VERSION ""

NS_ :

BS_:

BU_: SVB1 Tester Gateway CDS1 CDS2 ADV IRC AVP AVM PDC ADB1 ADB2 HDMAP DSM Fradar LCDA1 LCDA2

BO_ 3221225472 VECTOR__INDEPENDENT_SIG_MSG: 0 Vector__XXX
 SG_ Nanoseconds : 0|30@1+ (1,0) [0|0] "" Vector__XXX

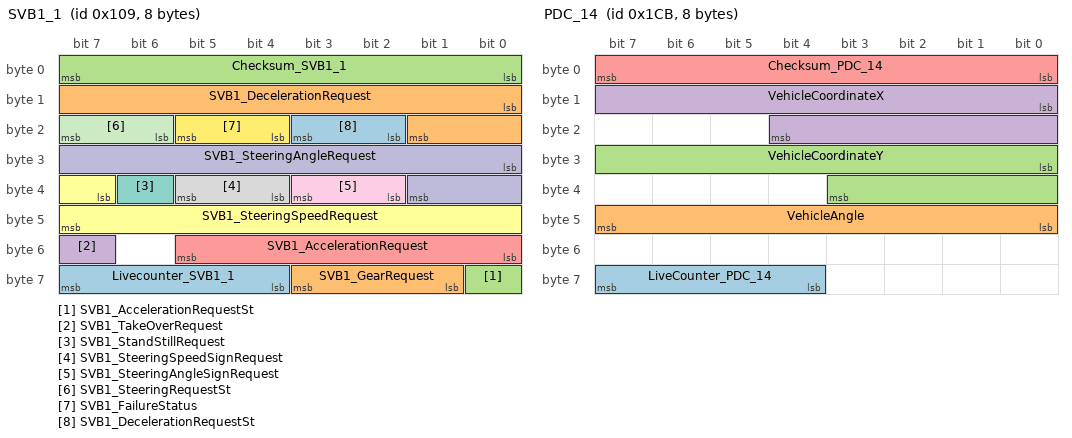
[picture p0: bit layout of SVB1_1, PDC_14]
BO_ 265 SVB1_1: 8 SVB1
 SG_ Livecounter_SVB1_1 : 60|4@1+ (1,0) [0|15] "Pulse"  CDS1,CDS2
 SG_ SVB1_GearRequest : 57|3@1+ (1,0) [0|7] ""  CDS1,CDS2
 SG_ SVB1_AccelerationRequestSt : 56|1@1+ (1,0) [0|1] ""  CDS1,CDS2
 SG_ SVB1_TakeOverRequest : 55|1@1+ (1,0) [0|1] ""  CDS1,CDS2
 SG_ SVB1_AccelerationRequest : 48|6@1+ (0.1,0) [0|6.3] "m/s2"  CDS1,CDS2
 SG_ SVB1_SteeringSpeedRequest : 39|9@1+ (1,0) [0|500] "deg/s"  CDS1,CDS2
 SG_ SVB1_StandStillRequest : 38|1@1+ (1,0) [0|1] ""  CDS1,CDS2
 SG_ SVB1_SteeringSpeedSignRequest : 36|2@1+ (1,0) [0|3] ""  CDS1,CDS2
 SG_ SVB1_SteeringAngleSignRequest : 34|2@1+ (1,0) [0|3] ""  CDS1,CDS2
 SG_ SVB1_SteeringAngleRequest : 24|10@1+ (1,0) [0|1023] "deg"  CDS1,CDS2
 SG_ SVB1_SteeringRequestSt : 22|2@1+ (1,0) [0|3] ""  CDS1,CDS2
 SG_ SVB1_FailureStatus : 20|2@1+ (1,0) [0|3] ""  CDS1,CDS2
 SG_ SVB1_DecelerationRequestSt : 18|2@1+ (1,0) [0|3] ""  CDS1,CDS2
 SG_ SVB1_DecelerationRequest : 8|10@1+ (0.01,-10) [-10|0] "m/s2"  CDS1,CDS2
 SG_ Checksum_SVB1_1 : 0|8@1+ (1,0) [0|255] ""  CDS1,CDS2

BO_ 416 SVB1_2: 8 SVB1
 SG_ Livecounter_SVB1_2 : 60|4@1+ (1,0) [0|15] "Pulse"  CDS1,CDS2
 SG_ Checksum_SVB1_2 : 0|8@1+ (1,0) [0|255] ""  CDS1,CDS2
 SG_ SVB1_LeftTurningLightRequest : 10|2@1+ (1,0) [0|3] ""  CDS1,CDS2
 SG_ SVB1_RightTurningLightRequest : 12|2@1+ (1,0) [0|3] ""  CDS1,CDS2
 SG_ SVB1_HazardLightRequest : 14|2@1+ (1,0) [0|3] ""  CDS1,CDS2
 SG_ SVB1_FogRequest : 16|3@1+ (1,0) [0|7] ""  CDS1,CDS2
 SG_ SVB1_HornRequest : 19|1@1+ (1,0) [0|1] ""  CDS1,CDS2
 SG_ SVB1_Lowbeamrequest : 20|2@1+ (1,0) [0|3] ""  CDS1,CDS2
 SG_ SVB1_HighBeamRequest : 22|2@1+ (1,0) [0|3] ""  CDS1,CDS2
 SG_ SVB1_HU_SpeechReq_LeftTempAdjSW : 26|3@1+ (1,0) [0|7] ""  CDS1,CDS2
 SG_ SVB1_HU_SpeechRequest_SetLeftBLW : 29|3@1+ (1,0) [0|7] ""  CDS1,CDS2
 SG_ SVB1_PositionLightRequest : 32|3@1+ (1,0) [0|7] ""  CDS1,CDS2
 SG_ SVB1_HU_SpeechRequest_AC : 35|2@1+ (1,0) [0|3] ""  CDS1,CDS2
 SG_ SVB1_HU_SpeechRequest_FRSREC : 37|2@1+ (1,0) [0|3] ""  CDS1,CDS2
 SG_ SVB1_HU_SpeechRequest_BlwlevelAd : 40|2@1+ (1,0) [0|3] ""  CDS1,CDS2
 SG_ SVB1_HU_SpeechReq_FLseatHeatLeve : 42|3@1+ (1,0) [0|7] ""  CDS1,CDS2
 SG_ SVB1_HU_SpeechReq_FRseatHeatLeve : 45|3@1+ (1,0) [0|7] ""  CDS1,CDS2
 SG_ SVB1_HU_SpeechReq_SetLeftTemp : 48|6@1+ (0.5,15) [15|40] "°Ê"  CDS1,CDS2
 SG_ SVB1_EPBRequest : 54|2@1+ (1,0) [0|3] ""  CDS1,CDS2
 SG_ SVB1_RequestTurnOffLowVoltage : 56|2@1+ (1,0) [0|3] ""  CDS1,CDS2

BO_ 704 SVB1_3: 8 SVB1
 SG_ SVB1_3_res : 0|8@1+ (1,0) [0|255] ""  CDS1,CDS2

BO_ 706 SVB1_4: 8 SVB1
 SG_ SVB1_4_res : 0|8@1+ (1,0) [0|255] ""  CDS1,CDS2

BO_ 708 SVB1_5: 8 SVB1
 SG_ SVB1_5_res : 0|8@1+ (1,0) [0|255] ""  CDS1,CDS2

BO_ 276 SVB1_6: 8 SVB1
 SG_ SVB1_6_res : 0|8@1+ (1,0) [0|255] ""  CDS1,CDS2

BO_ 459 PDC_14: 8 PDC
 SG_ LiveCounter_PDC_14 : 60|4@1+ (1,0) [0|15] "Pulse"  AVM,AVP,ADV
 SG_ VehicleAngle : 40|8@1+ (0.1,-10) [-10|10] "°„"  AVM,AVP,ADV
 SG_ VehicleCoordinateY : 24|12@1+ (1,-1000) [-1000|3095] "cm"  AVM,AVP,ADV
 SG_ VehicleCoordinateX : 8|13@1+ (1,0) [0|8191] "cm"  AVM,AVP,ADV
 SG_ Checksum_PDC_14 : 0|8@1+ (1,0) [0|255] ""  AVM,AVP,ADV

BO_ 605 PDC_2: 8 PDC
 SG_ ParkingSlotDegree_Right : 52|12@1+ (0.1,0) [0|409.5] "°„"  AVM,AVP
 SG_ ParkingSlotDegree_Left : 40|12@1+ (0.1,0) [0|409.5] "°„"  AVM,AVP
 SG_ SensorErrorSt_RRS : 39|1@1+ (1,0) [0|1] ""  AVM,AVP,ADV,Gateway
 SG_ ObjectRange_RRS : 36|3@1+ (1,0) [0|7] ""  AVM,AVP,ADV,Gateway
 SG_ SensorErrorSt_RLS : 35|1@1+ (1,0) [0|1] ""  AVM,AVP,ADV,Gateway
 SG_ ObjectRange_RLS : 32|3@1+ (1,0) [0|7] ""  AVM,AVP,ADV,Gateway
 SG_ SensorErrorSt_FRS : 31|1@1+ (1,0) [0|1] ""  AVM,AVP,ADV,Gateway
 SG_ ObjectRange_FRS : 28|3@1+ (1,0) [0|7] ""  AVM,AVP,ADV,Gateway
 SG_ SensorErrorSt_FLS : 27|1@1+ (1,0) [0|1] ""  AVM,AVP,ADV,Gateway
 SG_ ObjectRange_FLS : 24|3@1+ (1,0) [0|7] ""  AVM,AVP,ADV,Gateway
 SG_ SensorBlockageSt_RRS : 21|1@1+ (1,0) [0|1] ""  AVM,AVP,ADV,Gateway
 SG_ SensorBlockageSt_RLS : 20|1@1+ (1,0) [0|1] ""  AVM,AVP,ADV,Gateway
 SG_ SensorBlockageSt_FRS : 19|1@1+ (1,0) [0|1] ""  AVM,AVP,ADV,Gateway
 SG_ SensorBlockageSt_FLS : 18|1@1+ (1,0) [0|1] ""  AVM,AVP,ADV,Gateway
 SG_ SensorBlockageSt_FL : 15|1@1+ (1,0) [0|1] ""  AVM,AVP,ADV,Gateway
 SG_ SensorBlockageSt_FML : 14|1@1+ (1,0) [0|1] ""  AVM,AVP,ADV,Gateway
 SG_ SensorBlockageSt_FMR : 13|1@1+ (1,0) [0|1] ""  AVM,AVP,ADV,Gateway
 SG_ SensorBlockageSt_FR : 12|1@1+ (1,0) [0|1] ""  AVM,AVP,ADV,Gateway
 SG_ SensorBlockageSt_RL : 11|1@1+ (1,0) [0|1] ""  AVM,AVP,ADV,Gateway
 SG_ SensorBlockageSt_RML : 10|1@1+ (1,0) [0|1] ""  AVM,AVP,ADV,Gateway
 SG_ SensorBlockageSt_RMR : 9|1@1+ (1,0) [0|1] ""  AVM,AVP,ADV,Gateway
 SG_ SensorBlockageSt_RR : 8|1@1+ (1,0) [0|1] ""  AVM,AVP,ADV,Gateway

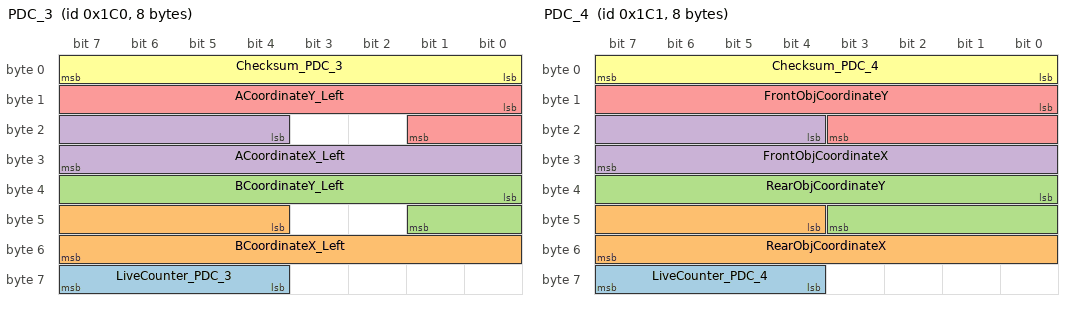
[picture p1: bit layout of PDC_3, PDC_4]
BO_ 448 PDC_3: 8 PDC
 SG_ LiveCounter_PDC_3 : 60|4@1+ (1,0) [0|15] "Pulse"  AVM,AVP,ADV
 SG_ BCoordinateX_Left : 44|12@1+ (1,0) [0|4095] "cm"  AVM,AVP,ADV
 SG_ BCoordinateY_Left : 32|10@1+ (1,0) [0|1023] "cm"  AVM,AVP,ADV
 SG_ ACoordinateX_Left : 20|12@1+ (1,0) [0|4095] "cm"  AVM,AVP,ADV
 SG_ ACoordinateY_Left : 8|10@1+ (1,0) [0|1023] "cm"  AVM,AVP,ADV
 SG_ Checksum_PDC_3 : 0|8@1+ (1,0) [0|255] ""  AVM,AVP,ADV

BO_ 449 PDC_4: 8 PDC
 SG_ LiveCounter_PDC_4 : 60|4@1+ (1,0) [0|15] "Pulse"  AVM,AVP,ADV
 SG_ RearObjCoordinateX : 44|12@1+ (2,-4000) [-4000|4190] "cm"  AVM,AVP,ADV
 SG_ RearObjCoordinateY : 32|12@1+ (2,-4000) [-4000|4190] "cm"  AVM,AVP,ADV
 SG_ FrontObjCoordinateX : 20|12@1+ (2,-4000) [-4000|4190] "cm"  AVM,AVP,ADV
 SG_ FrontObjCoordinateY : 8|12@1+ (2,-4000) [-4000|4190] "cm"  AVM,AVP,ADV
 SG_ Checksum_PDC_4 : 0|8@1+ (1,0) [0|255] ""  AVM,AVP,ADV

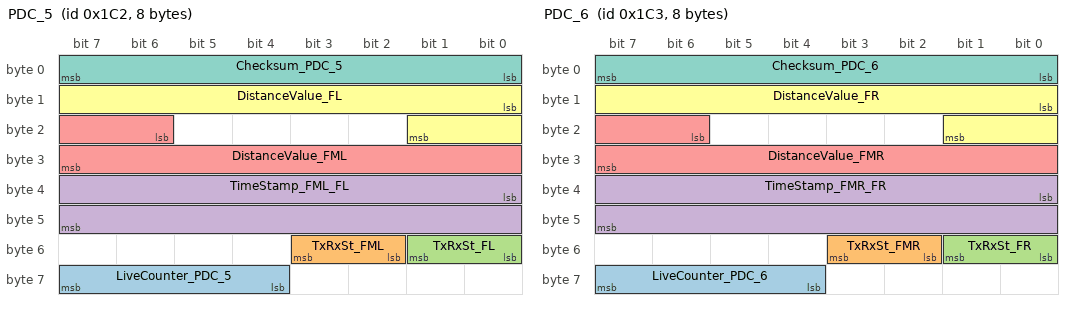
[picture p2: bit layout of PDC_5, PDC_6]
BO_ 450 PDC_5: 8 PDC
 SG_ LiveCounter_PDC_5 : 60|4@1+ (1,0) [0|15] "Pulse"  AVM,AVP,ADV
 SG_ TxRxSt_FML : 50|2@1+ (1,0) [0|3] ""  AVM,AVP,ADV
 SG_ TxRxSt_FL : 48|2@1+ (1,0) [0|3] ""  AVM,AVP,ADV
 SG_ TimeStamp_FML_FL : 32|16@1+ (1,0) [0|65535] "ms"  AVM,AVP,ADV
 SG_ DistanceValue_FML : 22|10@1+ (1,0) [0|1023] "cm"  AVM,AVP,ADV
 SG_ DistanceValue_FL : 8|10@1+ (1,0) [0|1023] "cm"  AVM,AVP,ADV
 SG_ Checksum_PDC_5 : 0|8@1+ (1,0) [0|255] ""  AVM,AVP,ADV

BO_ 451 PDC_6: 8 PDC
 SG_ LiveCounter_PDC_6 : 60|4@1+ (1,0) [0|15] "Pulse"  AVM,AVP,ADV
 SG_ TxRxSt_FMR : 50|2@1+ (1,0) [0|3] ""  AVM,AVP,ADV
 SG_ TxRxSt_FR : 48|2@1+ (1,0) [0|3] ""  AVM,AVP,ADV
 SG_ TimeStamp_FMR_FR : 32|16@1+ (1,0) [0|65535] "ms"  AVM,AVP,ADV
 SG_ DistanceValue_FMR : 22|10@1+ (1,0) [0|1023] "cm"  AVM,AVP,ADV
 SG_ DistanceValue_FR : 8|10@1+ (1,0) [0|1023] "cm"  AVM,AVP,ADV
 SG_ Checksum_PDC_6 : 0|8@1+ (1,0) [0|255] ""  AVM,AVP,ADV

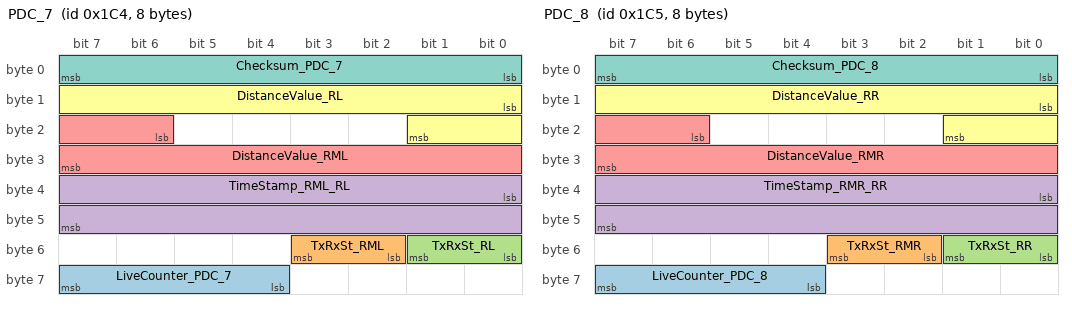
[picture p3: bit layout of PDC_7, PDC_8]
BO_ 452 PDC_7: 8 PDC
 SG_ LiveCounter_PDC_7 : 60|4@1+ (1,0) [0|15] "Pulse"  AVM,AVP,ADV
 SG_ TxRxSt_RML : 50|2@1+ (1,0) [0|3] ""  AVM,AVP,ADV
 SG_ TxRxSt_RL : 48|2@1+ (1,0) [0|3] ""  AVM,AVP,ADV
 SG_ TimeStamp_RML_RL : 32|16@1+ (1,0) [0|65535] "ms"  AVM,AVP,ADV
 SG_ DistanceValue_RML : 22|10@1+ (1,0) [0|1023] "cm"  AVM,AVP,ADV
 SG_ DistanceValue_RL : 8|10@1+ (1,0) [0|1023] "cm"  AVM,AVP,ADV
 SG_ Checksum_PDC_7 : 0|8@1+ (1,0) [0|255] ""  AVM,AVP,ADV

BO_ 453 PDC_8: 8 PDC
 SG_ LiveCounter_PDC_8 : 60|4@1+ (1,0) [0|15] "Pulse"  AVM,AVP,ADV
 SG_ TxRxSt_RMR : 50|2@1+ (1,0) [0|3] ""  AVM,AVP,ADV
 SG_ TxRxSt_RR : 48|2@1+ (1,0) [0|3] ""  AVM,AVP,ADV
 SG_ TimeStamp_RMR_RR : 32|16@1+ (1,0) [0|65535] "ms"  AVM,AVP,ADV
 SG_ DistanceValue_RMR : 22|10@1+ (1,0) [0|1023] "cm"  AVM,AVP,ADV
 SG_ DistanceValue_RR : 8|10@1+ (1,0) [0|1023] "cm"  AVM,AVP,ADV
 SG_ Checksum_PDC_8 : 0|8@1+ (1,0) [0|255] ""  AVM,AVP,ADV

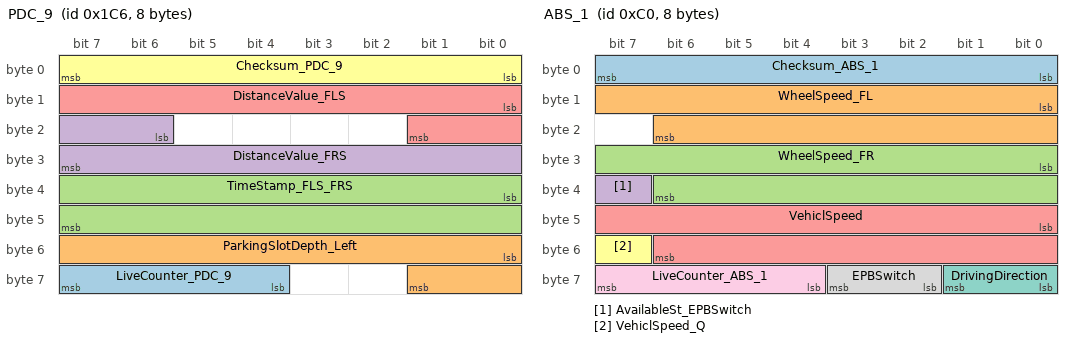
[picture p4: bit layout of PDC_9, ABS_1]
BO_ 454 PDC_9: 8 PDC
 SG_ LiveCounter_PDC_9 : 60|4@1+ (1,0) [0|15] "Pulse"  AVM,AVP,ADV
 SG_ ParkingSlotDepth_Left : 48|10@1+ (1,0) [0|1023] "cm"  AVM,AVP
 SG_ TimeStamp_FLS_FRS : 32|16@1+ (1,0) [0|65535] "ms"  AVM,AVP,ADV
 SG_ DistanceValue_FRS : 22|10@1+ (1,0) [0|1023] "cm"  AVM,AVP,ADV
 SG_ DistanceValue_FLS : 8|10@1+ (1,0) [0|1023] "cm"  AVM,AVP,ADV
 SG_ Checksum_PDC_9 : 0|8@1+ (1,0) [0|255] ""  AVM,AVP,ADV

BO_ 192 ABS_1: 8 Gateway
 SG_ Checksum_ABS_1 : 0|8@1+ (1,0) [0|255] ""  SVB1,CDS1,CDS2,ADV,IRC,AVP,AVM,PDC,ADB1,ADB2,HDMAP,DSM,Fradar,LCDA1,LCDA2
 SG_ WheelSpeed_FL : 8|15@1+ (0.01,0) [0|327.67] "km/h"  SVB1,CDS1,CDS2,ADV,AVP,AVM,PDC,HDMAP,DSM
 SG_ WheelSpeed_FR : 24|15@1+ (0.01,0) [0|327.67] "km/h"  SVB1,CDS1,CDS2,ADV,AVP,AVM,PDC,HDMAP,DSM
 SG_ AvailableSt_EPBSwitch : 39|1@1+ (1,0) [0|1] ""  SVB1,CDS1,CDS2,ADV
 SG_ VehiclSpeed : 40|15@1+ (0.01,0) [0|327.67] "km/h"  SVB1,CDS1,CDS2,ADV,IRC,AVP,AVM,PDC,ADB1,ADB2,HDMAP,DSM,Fradar,LCDA1,LCDA2
 SG_ VehiclSpeed_Q : 55|1@1+ (1,0) [0|1] ""  SVB1,CDS1,CDS2,ADV,IRC,HDMAP,DSM
 SG_ DrivingDirection : 56|2@1+ (1,0) [0|3] ""  SVB1,CDS1,CDS2,ADV,AVP,AVM,PDC,Fradar,LCDA1,LCDA2
 SG_ EPBSwitch : 58|2@1+ (1,0) [0|3] ""  SVB1,CDS1,CDS2,ADV
 SG_ LiveCounter_ABS_1 : 60|4@1+ (1,0) [0|15] ""  SVB1,CDS1,CDS2,ADV,IRC,AVP,AVM,PDC,ADB1,ADB2,HDMAP,DSM,Fradar,LCDA1,LCDA2

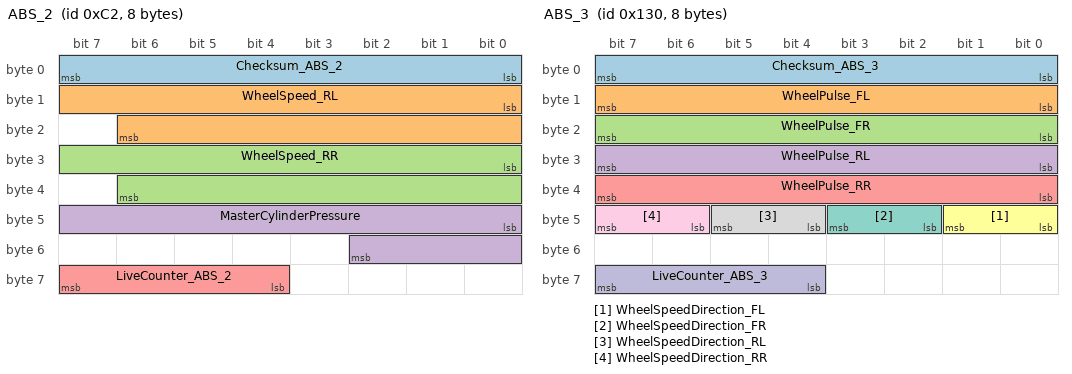
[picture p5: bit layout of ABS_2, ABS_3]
BO_ 194 ABS_2: 8 Gateway
 SG_ Checksum_ABS_2 : 0|8@1+ (1,0) [0|255] ""  SVB1,CDS1,CDS2,ADV,AVP,AVM,PDC,HDMAP
 SG_ WheelSpeed_RL : 8|15@1+ (0.01,0) [0|327.67] "km/h"  SVB1,CDS1,CDS2,ADV,AVP,AVM,PDC,HDMAP
 SG_ WheelSpeed_RR : 24|15@1+ (0.01,0) [0|327.67] "km/h"  SVB1,CDS1,CDS2,ADV,AVP,AVM,PDC,HDMAP
 SG_ MasterCylinderPressure : 40|11@1+ (0.1,0) [0|204.7] "bar"  SVB1,CDS1,CDS2,ADV,HDMAP
 SG_ LiveCounter_ABS_2 : 60|4@1+ (1,0) [0|15] ""  SVB1,CDS1,CDS2,ADV,AVP,AVM,PDC,HDMAP

BO_ 304 ABS_3: 8 Gateway
 SG_ Checksum_ABS_3 : 0|8@1+ (1,0) [0|255] ""  SVB1,CDS1,CDS2,ADV,AVP,AVM,PDC,HDMAP
 SG_ WheelPulse_FL : 8|8@1+ (1,0) [0|255] ""  SVB1,CDS1,CDS2,ADV,AVP,AVM,PDC,HDMAP
 SG_ WheelPulse_FR : 16|8@1+ (1,0) [0|255] ""  SVB1,CDS1,CDS2,ADV,AVP,AVM,PDC,HDMAP
 SG_ WheelPulse_RL : 24|8@1+ (1,0) [0|255] ""  SVB1,CDS1,CDS2,ADV,AVP,AVM,PDC,HDMAP
 SG_ WheelPulse_RR : 32|8@1+ (1,0) [0|255] ""  SVB1,CDS1,CDS2,ADV,AVP,AVM,PDC,HDMAP
 SG_ WheelSpeedDirection_FL : 40|2@1+ (1,0) [0|3] ""  CDS2,CDS1,SVB1,PDC
 SG_ WheelSpeedDirection_FR : 42|2@1+ (1,0) [0|3] ""  CDS2,CDS1,SVB1,PDC
 SG_ WheelSpeedDirection_RL : 44|2@1+ (1,0) [0|3] ""  CDS2,CDS1,SVB1,PDC
 SG_ WheelSpeedDirection_RR : 46|2@1+ (1,0) [0|3] ""  CDS2,CDS1,SVB1,PDC
 SG_ LiveCounter_ABS_3 : 60|4@1+ (1,0) [0|15] ""  SVB1,CDS1,CDS2,ADV,AVP,AVM,PDC,HDMAP

BO_ 306 ESC_2_1: 8 Gateway
 SG_ Checksum_ESC_2_1 : 0|8@1+ (1,0) [0|255] ""  SVB1,CDS1,CDS2,ADV,AVP,AVM,PDC
 SG_ WorkingSt_ESC : 8|1@1+ (1,0) [0|1] ""  SVB1,CDS1,CDS2
 SG_ ErrorSt_ESC : 9|1@1+ (1,0) [0|1] ""  SVB1,CDS1,CDS2,ADV
 SG_ Intervention_ESC : 10|1@1+ (1,0) [0|1] ""  SVB1,CDS1,CDS2,ADV
 SG_ ErrorSt_ABS : 11|1@1+ (1,0) [0|1] ""  SVB1,CDS1,CDS2
 SG_ Intervention_ABS : 12|1@1+ (1,0) [0|1] ""  SVB1,CDS1,CDS2,ADV
 SG_ Intervention_TCS : 14|1@1+ (1,0) [0|1] ""  SVB1,CDS1,CDS2,ADV
 SG_ ErrorSt_EBD : 15|1@1+ (1,0) [0|1] ""  CDS2,SVB1,CDS1,ADV
 SG_ AvailableSt_CDP : 16|1@1+ (1,0) [0|1] ""  CDS2,SVB1,CDS1
 SG_ Intervention_CDP_RWU : 17|1@1+ (1,0) [0|1] ""  CDS2,SVB1,CDS1
 SG_ LampCmd_EPB : 18|2@1+ (1,0) [0|3] ""  CDS2,CDS1,SVB1
 SG_ ErrotSt_EPB : 20|2@1+ (1,0) [0|3] ""  SVB1,CDS1,CDS2,ADV,AVP,AVM
 SG_ AvailableSt_HDC : 26|1@1+ (1,0) [0|1] ""  SVB1,CDS1,CDS2
 SG_ WorkingSt_HDC : 27|2@1+ (1,0) [0|3] ""  SVB1,CDS1,CDS2
 SG_ ErrorSt_AVH : 29|1@1+ (1,0) [0|1] ""  CDS2,CDS1,SVB1
 SG_ WorkingSt_AVH : 30|2@1+ (1,0) [0|3] ""  CDS2,CDS1,SVB1
 SG_ AvailableSt_CDDS : 32|1@1+ (1,0) [0|1] ""  SVB1,CDS1,CDS2
 SG_ Intervention_CDDS : 33|1@1+ (1,0) [0|1] ""  SVB1,CDS1,CDS2
 SG_ AvailableSt_AEB : 34|1@1+ (1,0) [0|1] ""  SVB1,CDS1,CDS2
 SG_ Intervention_AEB : 35|1@1+ (1,0) [0|1] ""  SVB1,CDS1,CDS2
 SG_ AvailableSt_ABP : 36|1@1+ (1,0) [0|1] ""  SVB1,CDS1,CDS2
 SG_ Intervention_ABP : 37|1@1+ (1,0) [0|1] ""  SVB1,CDS1,CDS2
 SG_ AvailableSt_AWB : 38|1@1+ (1,0) [0|1] ""  SVB1,CDS1,CDS2
 SG_ Intervention_AWB : 39|1@1+ (1,0) [0|1] ""  SVB1,CDS1,CDS2
 SG_ AvailableSt_HBA : 40|1@1+ (1,0) [0|1] ""  CDS2,CDS1,SVB1
 SG_ Intervention_HBA : 41|1@1+ (1,0) [0|1] ""  CDS2,CDS1,SVB1
 SG_ WorkingSt_HBB : 42|2@1+ (1,0) [0|3] ""  CDS2,CDS1,SVB1
 SG_ Intervention_HBB : 44|1@1+ (1,0) [0|1] ""  CDS2,CDS1,SVB1
 SG_ Intervention_EmergencyBrake : 45|1@1+ (1,0) [0|1] ""  CDS2,CDS1,SVB1
 SG_ VehicleStandstillSt : 46|1@1+ (1,0) [0|1] ""  SVB1,CDS1,CDS2,ADV
 SG_ BrakeLightCtrlCmd : 47|1@1+ (1,0) [0|1] ""  CDS2,CDS1,SVB1
 SG_ WorkingSt_EPB : 48|2@1+ (1,0) [0|3] ""  SVB1,CDS1,CDS2,ADV,AVP,AVM,PDC
 SG_ APA_Available_ESC : 50|1@1+ (1,0) [0|1] ""  CDS2,SVB1,CDS1,ADV
 SG_ APA_Intervention_ESC : 51|1@1+ (1,0) [0|1] ""  CDS2,SVB1,CDS1,ADV
 SG_ LiveCounter_ESC_2_1 : 60|4@1+ (1,0) [0|15] ""  SVB1,CDS1,CDS2,ADV,AVP,AVM,PDC

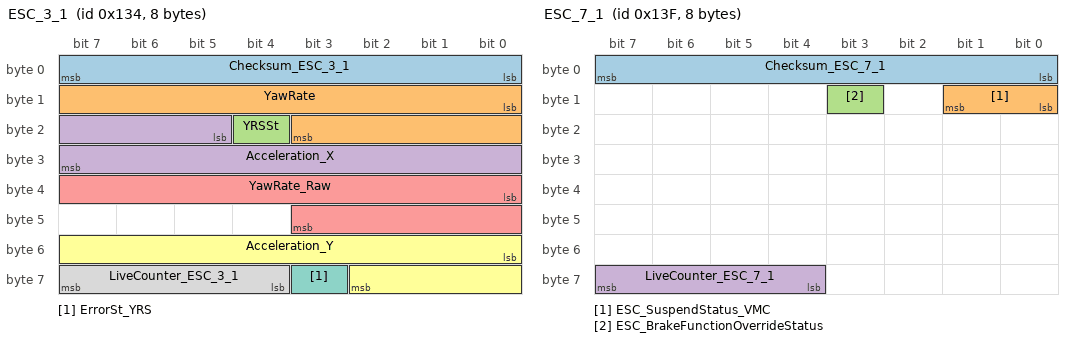
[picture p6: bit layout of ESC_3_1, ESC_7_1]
BO_ 308 ESC_3_1: 8 Gateway
 SG_ Checksum_ESC_3_1 : 0|8@1+ (1,0) [0|255] ""  SVB1,CDS1,CDS2,ADV,IRC,AVP,AVM,PDC,HDMAP,Fradar,LCDA1,LCDA2
 SG_ YawRate : 8|12@1+ (0.05,-100) [-100|104.75] "deg/s"  SVB1,CDS1,CDS2,ADV,IRC,AVP,AVM,PDC,HDMAP,Fradar,LCDA1,LCDA2
 SG_ YRSSt : 20|1@1+ (1,0) [0|1] ""  SVB1,CDS1,CDS2,ADV,IRC,AVP,AVM,HDMAP,Fradar,LCDA1,LCDA2
 SG_ Acceleration_X : 21|11@1+ (0.027127,-21.593) [-21.593|33.935969] ""  SVB1,CDS1,CDS2,ADV,AVP,AVM,HDMAP,Fradar,LCDA1,LCDA2
 SG_ YawRate_Raw : 32|12@1+ (0.05,-100) [-100|104.75] "deg/s"  CDS2,CDS1,SVB1,AVP,AVM
 SG_ Acceleration_Y : 48|11@1+ (0.027127,-21.593) [-21.593|33.935969] ""  SVB1,CDS1,CDS2,ADV,AVP,AVM,HDMAP,Fradar,LCDA1,LCDA2
 SG_ ErrorSt_YRS : 59|1@1+ (1,0) [0|1] ""  SVB1,CDS1,CDS2,ADV,AVP,AVM,HDMAP,Fradar,LCDA1,LCDA2
 SG_ LiveCounter_ESC_3_1 : 60|4@1+ (1,0) [0|15] ""  SVB1,CDS1,CDS2,ADV,IRC,AVP,AVM,PDC,HDMAP,Fradar,LCDA1,LCDA2

BO_ 312 ESC_5_1: 8 Gateway
 SG_ Checksum_ESC_5_1 : 0|8@1+ (1,0) [0|255] ""  SVB1,CDS1,CDS2,ADV,HDMAP,DSM
 SG_ ESC_AutoPark_LCSt : 25|3@1+ (1,0) [0|7] ""  CDS2,SVB1,CDS1,ADV
 SG_ ESC_AutoPark_LCFailureSt : 28|3@1+ (1,0) [0|7] ""  CDS2,SVB1,CDS1,ADV
 SG_ ESC_AutoPark_LC_BrakeMode : 35|2@1+ (1,0) [0|3] ""  CDS2,SVB1,CDS1,ADV
 SG_ ESC_LSMAvail_Parking : 37|1@1+ (1,0) [0|1] ""  CDS2,SVB1,CDS1,ADV
 SG_ ESC_AutoPark_LC_APA_Avail : 38|2@1+ (1,0) [0|3] ""  CDS2,SVB1,CDS1,ADV
 SG_ ESC_VLCSt_L12 : 40|1@1+ (1,0) [0|1] ""  SVB1,CDS1,CDS2
 SG_ ESC_VLCSt_L3 : 41|1@1+ (1,0) [0|1] ""  SVB1,CDS1,CDS2
 SG_ ESC_VLC_Error_L12 : 42|1@1+ (1,0) [0|1] ""  SVB1,CDS1,CDS2
 SG_ ESC_VMC_Error_L3 : 44|2@1+ (1,0) [0|3] ""  SVB1,CDS1,CDS2
 SG_ ESC_AutoDriving_LC_Brakemode : 46|2@1+ (1,0) [0|3] ""  SVB1,CDS1,CDS2
 SG_ ESC_AutoPark_LC_RPA_Avail : 48|2@1+ (1,0) [0|3] ""  CDS2,SVB1,CDS1,ADV
 SG_ ESC_AutoParkingSt_Feedback : 50|1@1+ (1,0) [0|1] ""  SVB1,CDS1,CDS2,ADV
 SG_ ESC_BrakePedalStatus : 51|1@1+ (1,0) [0|1] ""  SVB1,CDS1,CDS2,ADV,AVP,AVM,HDMAP,DSM
 SG_ ESC_BrakePedalStatus_Q : 52|2@1+ (1,0) [0|3] ""  SVB1,CDS1,CDS2,ADV,HDMAP,DSM
 SG_ ESC_BrakePedalDominant_Q : 54|2@1+ (1,0) [0|3] ""  SVB1,CDS1,CDS2,ADV,HDMAP,DSM
 SG_ ESC_BrakePedalDominant : 56|1@1+ (1,0) [0|1] ""  SVB1,CDS1,CDS2,ADV,HDMAP,DSM
 SG_ ESC_AutoPark_LC_AVP_Avail : 57|2@1+ (1,0) [0|3] ""  CDS2,SVB1,CDS1,ADV
 SG_ ESC_ShutOffFinished : 59|1@1+ (1,0) [0|1] ""  SVB1,CDS1,CDS2
 SG_ LiveCounter_ESC_5_1 : 60|4@1+ (1,0) [0|15] "Pulse"  SVB1,CDS1,CDS2,ADV,HDMAP,DSM

BO_ 319 ESC_7_1: 8 Gateway
 SG_ Checksum_ESC_7_1 : 0|8@1+ (1,0) [0|255] ""  SVB1,CDS1,CDS2,ADV
 SG_ ESC_SuspendStatus_VMC : 8|2@1+ (1,0) [0|3] ""  SVB1,CDS1,CDS2,ADV
 SG_ ESC_BrakeFunctionOverrideStatus : 11|1@1+ (1,0) [0|1] ""  SVB1,CDS1,CDS2,ADV
 SG_ LiveCounter_ESC_7_1 : 60|4@1+ (1,0) [0|15] ""  SVB1,CDS1,CDS2,ADV

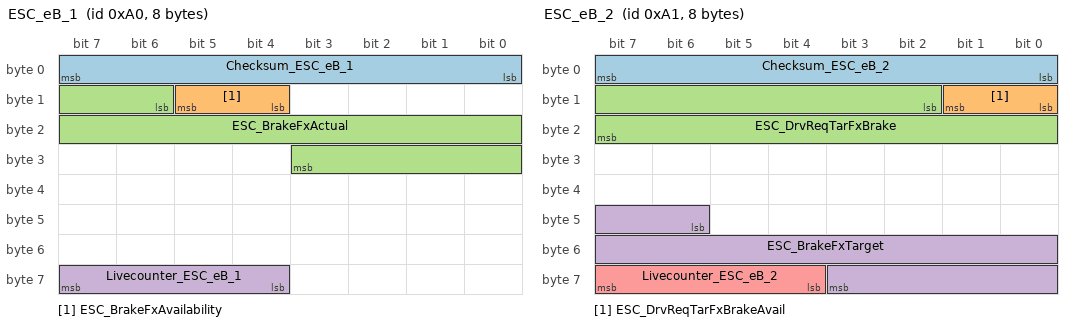
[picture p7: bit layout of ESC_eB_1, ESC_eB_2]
BO_ 160 ESC_eB_1: 8 Gateway
 SG_ Checksum_ESC_eB_1 : 0|8@1+ (1,0) [0|255] ""  SVB1,CDS2,CDS1
 SG_ ESC_BrakeFxAvailability : 12|2@1+ (1,0) [0|3] ""  SVB1,CDS2,CDS1
 SG_ ESC_BrakeFxActual : 14|14@1+ (8,-125000) [-125000|0] ""  SVB1,CDS2,CDS1
 SG_ Livecounter_ESC_eB_1 : 60|4@1+ (1,0) [0|15] "Pulse"  SVB1,CDS2,CDS1

BO_ 161 ESC_eB_2: 8 Gateway
 SG_ Checksum_ESC_eB_2 : 0|8@1+ (1,0) [0|255] ""  SVB1,CDS2,CDS1
 SG_ ESC_DrvReqTarFxBrakeAvail : 8|2@1+ (1,0) [0|3] ""  SVB1,CDS2,CDS1
 SG_ ESC_DrvReqTarFxBrake : 10|14@1+ (8,-125000) [-125000|0] ""  SVB1,CDS2,CDS1
 SG_ ESC_BrakeFxTarget : 46|14@1+ (8,-125000) [-125000|0] ""  SVB1,CDS2,CDS1
 SG_ Livecounter_ESC_eB_2 : 60|4@1+ (1,0) [0|15] "Pulse"  SVB1,CDS2,CDS1

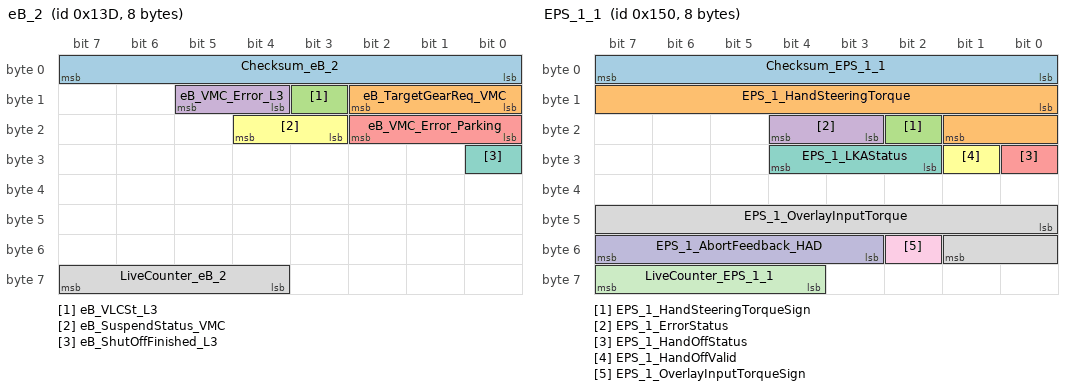
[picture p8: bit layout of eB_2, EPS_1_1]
BO_ 317 eB_2: 8 Gateway
 SG_ Checksum_eB_2 : 0|8@1+ (1,0) [0|255] ""  SVB1,CDS1,CDS2
 SG_ eB_TargetGearReq_VMC : 8|3@1+ (1,0) [0|7] ""  CDS2,CDS1,SVB1
 SG_ eB_VLCSt_L3 : 11|1@1+ (1,0) [0|1] ""  SVB1,CDS1,CDS2
 SG_ eB_VMC_Error_L3 : 12|2@1+ (1,0) [0|3] ""  SVB1,CDS1,CDS2
 SG_ eB_VMC_Error_Parking : 16|3@1+ (1,0) [0|7] ""  CDS2,CDS1,SVB1
 SG_ eB_SuspendStatus_VMC : 19|2@1+ (1,0) [0|3] ""  SVB1,CDS1,CDS2
 SG_ eB_ShutOffFinished_L3 : 24|1@1+ (1,0) [0|1] ""  SVB1,CDS1,CDS2
 SG_ LiveCounter_eB_2 : 60|4@1+ (1,0) [0|15] "Pulse"  SVB1,CDS1,CDS2

BO_ 336 EPS_1_1: 8 Gateway
 SG_ Checksum_EPS_1_1 : 0|8@1+ (1,0) [0|255] ""  SVB1,CDS1,CDS2,ADV,DSM
 SG_ EPS_1_HandSteeringTorque : 8|10@1+ (0.01,0) [0|10.23] "Nm"  SVB1,CDS1,CDS2,ADV,DSM
 SG_ EPS_1_HandSteeringTorqueSign : 18|1@1+ (1,0) [0|1] ""  SVB1,CDS1,CDS2,ADV,DSM
 SG_ EPS_1_ErrorStatus : 19|2@1+ (1,0) [0|3] ""  SVB1,CDS1,CDS2,ADV
 SG_ EPS_1_HandOffStatus : 24|1@1+ (1,0) [0|1] ""  SVB1,CDS1,CDS2,ADV,DSM
 SG_ EPS_1_HandOffValid : 25|1@1+ (1,0) [0|1] ""  SVB1,CDS1,CDS2,ADV,DSM
 SG_ EPS_1_LKAStatus : 26|3@1+ (1,0) [0|7] ""  SVB1,CDS1,CDS2
 SG_ EPS_1_OverlayInputTorque : 40|10@1+ (0.01,0) [0|10.23] "Nm"  SVB1,CDS1,CDS2,ADV
 SG_ EPS_1_OverlayInputTorqueSign : 50|1@1+ (1,0) [0|1] ""  SVB1,CDS1,CDS2,ADV
 SG_ EPS_1_AbortFeedback_HAD : 51|5@1+ (1,0) [0|31] ""  SVB1,Gateway,CDS1,CDS2,ADV
 SG_ LiveCounter_EPS_1_1 : 60|4@1+ (1,0) [0|15] "Pulse"  SVB1,CDS1,CDS2,ADV,DSM

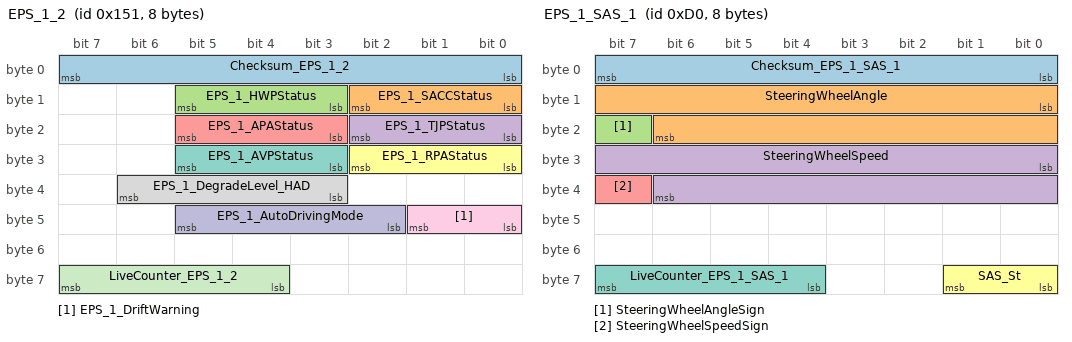
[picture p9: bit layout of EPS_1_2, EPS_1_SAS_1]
BO_ 337 EPS_1_2: 8 Gateway
 SG_ Checksum_EPS_1_2 : 0|8@1+ (1,0) [0|255] ""  SVB1,CDS1,CDS2,ADV
 SG_ EPS_1_SACCStatus : 8|3@1+ (1,0) [0|7] ""  SVB1,CDS1,CDS2
 SG_ EPS_1_HWPStatus : 11|3@1+ (1,0) [0|7] ""  SVB1,CDS1,CDS2
 SG_ EPS_1_TJPStatus : 16|3@1+ (1,0) [0|7] ""  SVB1,CDS1,CDS2
 SG_ EPS_1_APAStatus : 19|3@1+ (1,0) [0|7] ""  CDS2,SVB1,CDS1,ADV
 SG_ EPS_1_RPAStatus : 24|3@1+ (1,0) [0|7] ""  CDS2,SVB1,CDS1,ADV
 SG_ EPS_1_AVPStatus : 27|3@1+ (1,0) [0|7] ""  CDS2,SVB1,CDS1,ADV
 SG_ EPS_1_DegradeLevel_HAD : 35|4@1+ (1,0) [0|15] ""  SVB1,CDS1,CDS2,ADV
 SG_ EPS_1_DriftWarning : 40|2@1+ (1,0) [0|3] ""  SVB1,CDS1,CDS2
 SG_ EPS_1_AutoDrivingMode : 42|4@1+ (1,0) [0|15] ""  SVB1,CDS1,CDS2,ADV
 SG_ LiveCounter_EPS_1_2 : 60|4@1+ (1,0) [0|15] ""  SVB1,CDS1,CDS2,ADV

BO_ 208 EPS_1_SAS_1: 8 Gateway
 SG_ Checksum_EPS_1_SAS_1 : 0|8@1+ (1,0) [0|255] ""  SVB1,CDS1,CDS2,ADV,IRC,AVP,AVM,PDC,HDMAP,DSM,Fradar,LCDA1,LCDA2
 SG_ SteeringWheelAngle : 8|15@1+ (0.04375,0) [0|1433.55625] "°„"  SVB1,CDS1,CDS2,ADV,IRC,AVP,AVM,PDC,HDMAP,DSM,Fradar,LCDA1,LCDA2
 SG_ SteeringWheelAngleSign : 23|1@1+ (1,0) [0|1] ""  SVB1,CDS1,CDS2,ADV,IRC,AVP,AVM,PDC,HDMAP,DSM,Fradar,LCDA1,LCDA2
 SG_ SteeringWheelSpeed : 24|15@1+ (0.04375,0) [0|1433.55625] "°„/s"  SVB1,CDS1,CDS2,IRC,HDMAP,DSM
 SG_ SteeringWheelSpeedSign : 39|1@1+ (1,0) [0|1] ""  SVB1,CDS1,CDS2,IRC,HDMAP,DSM
 SG_ SAS_St : 56|2@1+ (1,0) [0|3] ""  SVB1,CDS1,CDS2,ADV,IRC,AVP,AVM,HDMAP,DSM,Fradar,LCDA1,LCDA2
 SG_ LiveCounter_EPS_1_SAS_1 : 60|4@1+ (1,0) [0|15] ""  SVB1,CDS1,CDS2,ADV,IRC,AVP,AVM,PDC,HDMAP,DSM,Fradar,LCDA1,LCDA2

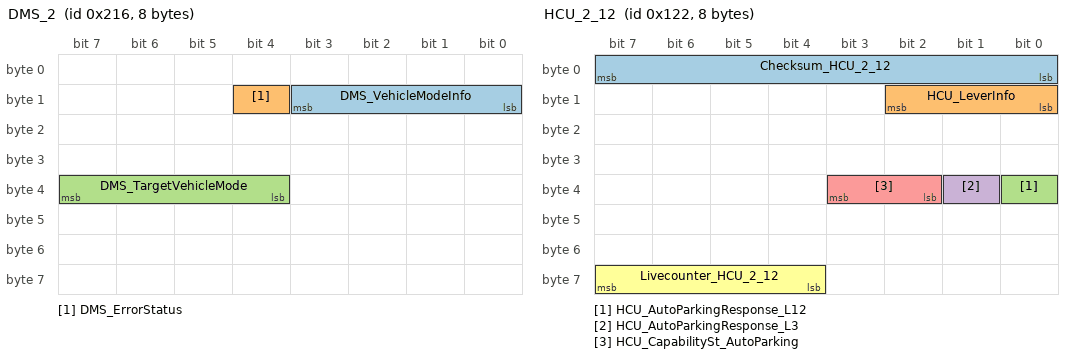
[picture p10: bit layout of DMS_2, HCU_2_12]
BO_ 534 DMS_2: 8 Gateway
 SG_ DMS_VehicleModeInfo : 8|4@1+ (1,0) [0|15] ""  SVB1,CDS1,CDS2,AVP,AVM
 SG_ DMS_ErrorStatus : 12|1@1+ (1,0) [0|1] ""  CDS2,SVB1,CDS1
 SG_ DMS_TargetVehicleMode : 36|4@1+ (1,0) [0|15] ""  SVB1,CDS1,CDS2

BO_ 290 HCU_2_12: 8 Gateway
 SG_ Checksum_HCU_2_12 : 0|8@1+ (1,0) [0|255] ""  SVB1,CDS1,CDS2,ADV,IRC,AVP,AVM,PDC,DSM,Fradar,LCDA1,LCDA2
 SG_ HCU_LeverInfo : 8|3@1+ (1,0) [0|7] ""  SVB1,CDS1,CDS2,ADV,IRC,AVP,AVM,PDC,DSM,Fradar,LCDA1,LCDA2
 SG_ HCU_AutoParkingResponse_L12 : 32|1@1+ (1,0) [0|1] ""  SVB1,CDS2,CDS1,ADV
 SG_ HCU_AutoParkingResponse_L3 : 33|1@1+ (1,0) [0|1] ""  SVB1,CDS2,CDS1
 SG_ HCU_CapabilitySt_AutoParking : 34|2@1+ (1,0) [0|3] ""  SVB1,CDS1,CDS2,ADV
 SG_ Livecounter_HCU_2_12 : 60|4@1+ (1,0) [0|15] "pulse"  SVB1,CDS1,CDS2,ADV,IRC,AVP,AVM,PDC,DSM,Fradar,LCDA1,LCDA2

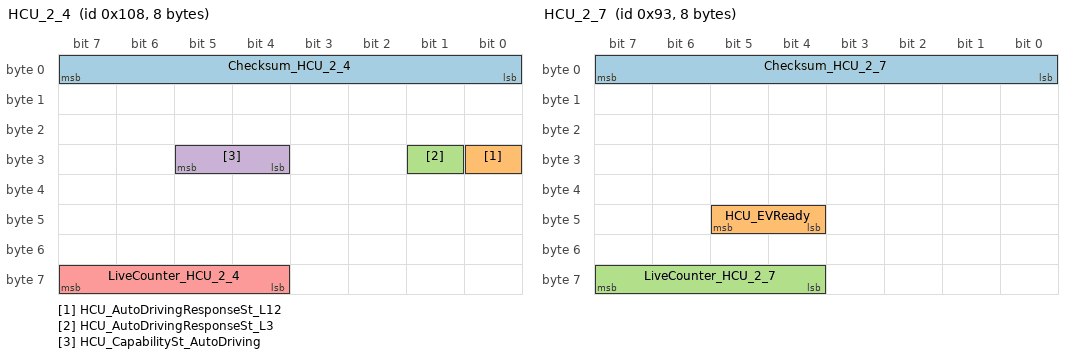
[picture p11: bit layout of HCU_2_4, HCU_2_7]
BO_ 264 HCU_2_4: 8 Gateway
 SG_ Checksum_HCU_2_4 : 0|8@1+ (1,0) [0|255] ""  SVB1,CDS1,CDS2
 SG_ HCU_AutoDrivingResponseSt_L12 : 24|1@1+ (1,0) [0|1] ""  SVB1,CDS1,CDS2
 SG_ HCU_AutoDrivingResponseSt_L3 : 25|1@1+ (1,0) [0|1] ""  SVB1,CDS1,CDS2
 SG_ HCU_CapabilitySt_AutoDriving : 28|2@1+ (1,0) [0|3] ""  SVB1,CDS1,CDS2
 SG_ LiveCounter_HCU_2_4 : 60|4@1+ (1,0) [0|15] ""  SVB1,CDS1,CDS2

BO_ 147 HCU_2_7: 8 Gateway
 SG_ Checksum_HCU_2_7 : 0|8@1+ (1,0) [0|255] ""  SVB1,CDS1,CDS2,ADV,DSM
 SG_ HCU_EVReady : 44|2@1+ (1,0) [0|3] ""  SVB1,CDS1,CDS2,ADV,DSM
 SG_ LiveCounter_HCU_2_7 : 60|4@1+ (1,0) [0|15] "Pulse"  SVB1,CDS1,CDS2,ADV,DSM

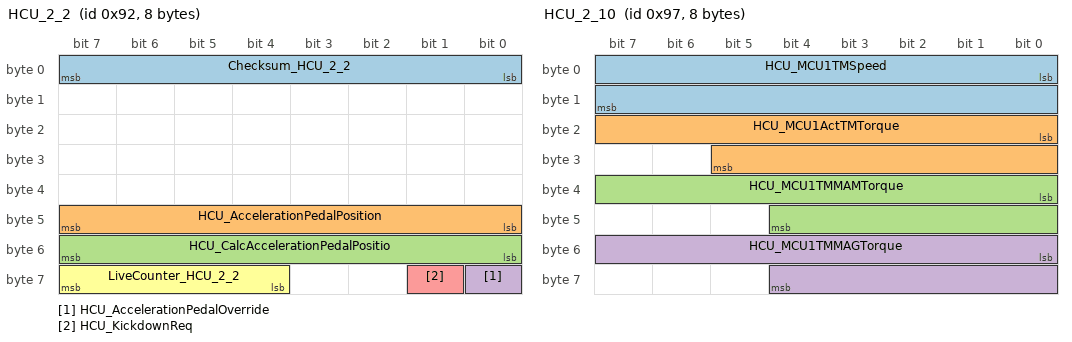
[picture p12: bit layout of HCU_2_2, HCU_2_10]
BO_ 146 HCU_2_2: 8 Gateway
 SG_ Checksum_HCU_2_2 : 0|8@1+ (1,0) [0|255] ""  SVB1,CDS1,CDS2,ADV,HDMAP,LCDA1,LCDA2
 SG_ HCU_AccelerationPedalPosition : 40|8@1+ (0.4,0) [0|102] "%"  SVB1,CDS1,CDS2,ADV,HDMAP,LCDA1,LCDA2
 SG_ HCU_CalcAccelerationPedalPositio : 48|8@1+ (0.4,0) [0|102] "%"  SVB1,CDS1,CDS2,ADV,HDMAP
 SG_ HCU_AccelerationPedalOverride : 56|1@1+ (1,0) [0|1] ""  SVB1,CDS1,CDS2,ADV
 SG_ HCU_KickdownReq : 57|1@1+ (1,0) [0|1] ""  SVB1,CDS1,CDS2,ADV
 SG_ LiveCounter_HCU_2_2 : 60|4@1+ (1,0) [0|15] ""  SVB1,CDS1,CDS2,ADV,HDMAP,LCDA1,LCDA2

BO_ 151 HCU_2_10: 8 Gateway
 SG_ HCU_MCU1TMSpeed : 0|16@1+ (1,-30000) [-30000|35535] "rpm"  SVB1,CDS1,CDS2
 SG_ HCU_MCU1ActTMTorque : 16|14@1+ (0.1,-800) [-800|838.3] "Nm"  SVB1,CDS1,CDS2
 SG_ HCU_MCU1TMMAMTorque : 32|13@1+ (0.1,0) [0|819.1] "Nm"  SVB1,CDS1,CDS2
 SG_ HCU_MCU1TMMAGTorque : 48|13@1+ (0.1,-800) [-800|19.1] "Nm"  SVB1,CDS1,CDS2

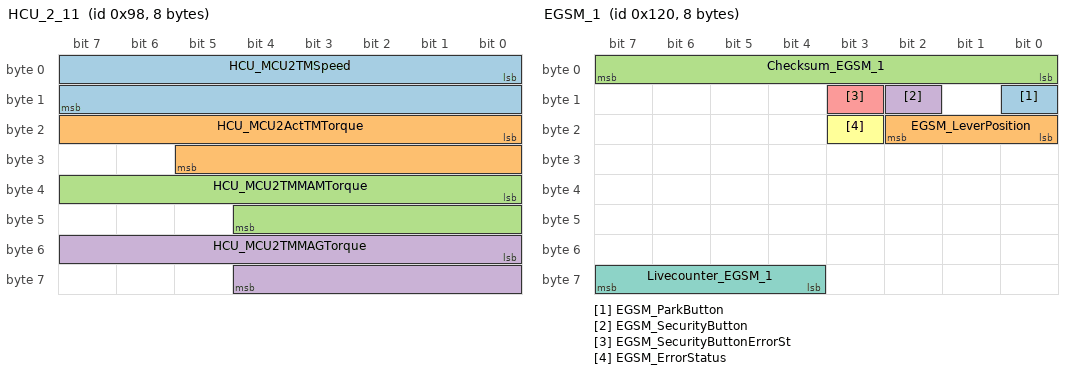
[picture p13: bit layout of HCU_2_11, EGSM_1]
BO_ 152 HCU_2_11: 8 Gateway
 SG_ HCU_MCU2TMSpeed : 0|16@1+ (1,-30000) [-30000|35535] "rpm"  SVB1,CDS1,CDS2
 SG_ HCU_MCU2ActTMTorque : 16|14@1+ (0.1,-800) [-800|838.3] "Nm"  SVB1,CDS1,CDS2
 SG_ HCU_MCU2TMMAMTorque : 32|13@1+ (0.1,0) [0|819.1] "Nm"  SVB1,CDS1,CDS2
 SG_ HCU_MCU2TMMAGTorque : 48|13@1+ (0.1,-800) [-800|19.1] "Nm"  SVB1,CDS1,CDS2

BO_ 288 EGSM_1: 8 Gateway
 SG_ EGSM_ParkButton : 8|1@1+ (1,0) [0|1] "" Vector__XXX
 SG_ EGSM_LeverPosition : 16|3@1+ (1,0) [0|7] "" Vector__XXX
 SG_ Checksum_EGSM_1 : 0|8@1+ (1,0) [0|255] ""  SVB1,CDS2,CDS1,ADV
 SG_ EGSM_SecurityButton : 10|1@1+ (1,0) [0|1] ""  SVB1,CDS2,CDS1,ADV
 SG_ EGSM_SecurityButtonErrorSt : 11|1@1+ (1,0) [0|1] ""  SVB1,CDS2,CDS1,ADV
 SG_ EGSM_ErrorStatus : 19|1@1+ (1,0) [0|1] ""  SVB1,CDS2,CDS1,ADV
 SG_ Livecounter_EGSM_1 : 60|4@1+ (1,0) [0|15] "Pulse"  SVB1,CDS2,CDS1,ADV

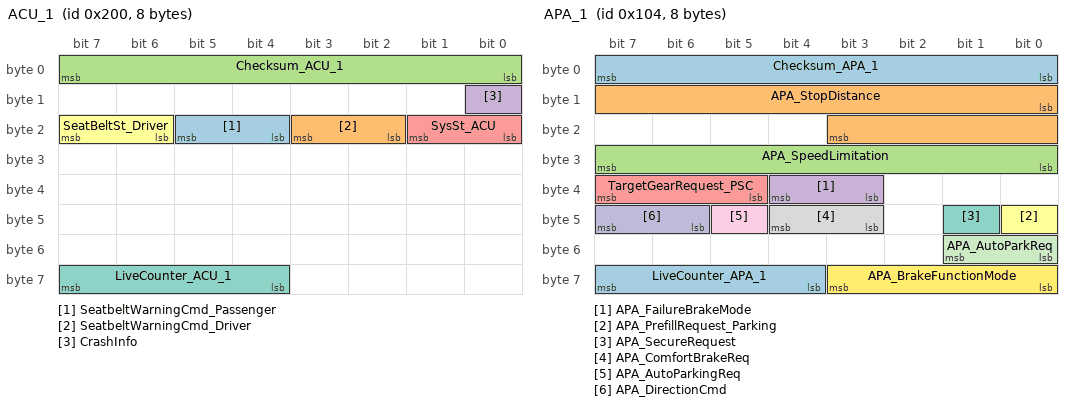
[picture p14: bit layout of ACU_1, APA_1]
BO_ 512 ACU_1: 8 Gateway
 SG_ SeatbeltWarningCmd_Passenger : 20|2@1+ (1,0) [0|3] "" Vector__XXX
 SG_ SeatbeltWarningCmd_Driver : 18|2@1+ (1,0) [0|3] "" Vector__XXX
 SG_ Checksum_ACU_1 : 0|8@1+ (1,0) [0|255] ""  SVB1,CDS1,CDS2,ADV
 SG_ CrashInfo : 8|1@1+ (1,0) [0|1] ""  SVB1,CDS1,CDS2,ADV
 SG_ SysSt_ACU : 16|2@1+ (1,0) [0|3] ""  SVB1,CDS1,CDS2,ADV
 SG_ SeatBeltSt_Driver : 22|2@1+ (1,0) [0|3] ""  SVB1,CDS1,CDS2,ADV
 SG_ LiveCounter_ACU_1 : 60|4@1+ (1,0) [0|15] ""  SVB1,CDS1,CDS2,ADV

BO_ 260 APA_1: 8 CDS1
 SG_ Checksum_APA_1 : 0|8@1+ (1,0) [0|255] ""  Gateway,HDMAP
 SG_ APA_StopDistance : 8|12@1+ (1,0) [0|4095] "cm"  Gateway
 SG_ APA_SpeedLimitation : 24|8@1+ (0.1,0) [0|15] "km/h"  Gateway
 SG_ APA_FailureBrakeMode : 35|2@1+ (1,0) [0|3] ""  Gateway
 SG_ TargetGearRequest_PSC : 37|3@1+ (1,0) [0|7] ""  Gateway
 SG_ APA_PrefillRequest_Parking : 40|1@1+ (1,0) [0|1] ""  Gateway
 SG_ APA_SecureRequest : 41|1@1+ (1,0) [0|1] ""  Gateway
 SG_ APA_ComfortBrakeReq : 43|2@1+ (1,0) [0|3] ""  Gateway
 SG_ APA_AutoParkingReq : 45|1@1+ (1,0) [0|1] ""  Gateway
 SG_ APA_DirectionCmd : 46|2@1+ (1,0) [0|3] ""  Gateway
 SG_ APA_AutoParkReq : 48|2@1+ (1,0) [0|3] ""  Gateway
 SG_ APA_BrakeFunctionMode : 56|4@1+ (1,0) [0|15] ""  Gateway,HDMAP
 SG_ LiveCounter_APA_1 : 60|4@1+ (1,0) [0|15] "Pulse"  Gateway,HDMAP

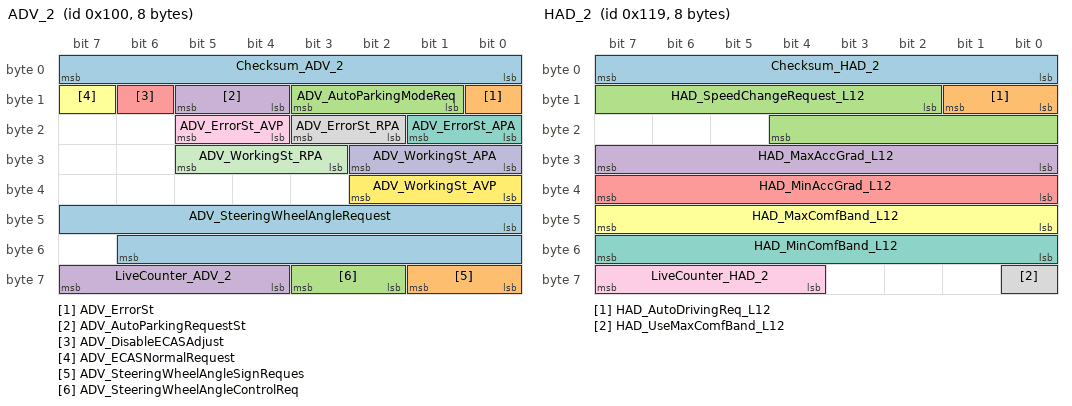
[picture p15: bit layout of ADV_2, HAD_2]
BO_ 256 ADV_2: 8 CDS1
 SG_ Checksum_ADV_2 : 0|8@1+ (1,0) [0|255] ""  CDS2,Gateway
 SG_ ADV_ErrorSt : 8|1@1+ (1,0) [0|1] ""  CDS2,Gateway
 SG_ ADV_AutoParkingModeReq : 9|3@1+ (1,0) [0|7] ""  CDS2,Gateway
 SG_ ADV_AutoParkingRequestSt : 12|2@1+ (1,0) [0|3] ""  CDS2,Gateway
 SG_ ADV_DisableECASAdjust : 14|1@1+ (1,0) [0|1] ""  CDS2,Gateway
 SG_ ADV_ECASNormalRequest : 15|1@1+ (1,0) [0|1] ""  CDS2,Gateway
 SG_ ADV_ErrorSt_APA : 16|2@1+ (1,0) [0|3] ""  CDS2,Gateway
 SG_ ADV_ErrorSt_RPA : 18|2@1+ (1,0) [0|3] ""  CDS2,Gateway
 SG_ ADV_ErrorSt_AVP : 20|2@1+ (1,0) [0|3] ""  CDS2,Gateway
 SG_ ADV_WorkingSt_APA : 24|3@1+ (1,0) [0|7] ""  CDS2,Gateway
 SG_ ADV_WorkingSt_RPA : 27|3@1+ (1,0) [0|7] ""  CDS2,Gateway
 SG_ ADV_WorkingSt_AVP : 32|3@1+ (1,0) [0|7] ""  CDS2,Gateway
 SG_ ADV_SteeringWheelAngleRequest : 40|15@1+ (0.04375,0) [0|1433.55625] "°„"  CDS2,Gateway
 SG_ ADV_SteeringWheelAngleSignReques : 56|2@1+ (1,0) [0|3] ""  CDS2,Gateway
 SG_ ADV_SteeringWheelAngleControlReq : 58|2@1+ (1,0) [0|3] ""  CDS2,Gateway
 SG_ LiveCounter_ADV_2 : 60|4@1+ (1,0) [0|15] "Pulse"  CDS2,Gateway

BO_ 280 HAD_1: 8 CDS1
 SG_ HAD_AcclPedActReq : 40|1@1+ (1,0) [0|1] "" Vector__XXX
 SG_ HAD_AcclPedPosReq : 27|4@1+ (0.05,0) [0|0.75] "" Vector__XXX
 SG_ Checksum_HAD_1 : 0|8@1+ (1,0) [0|255] ""  Gateway,CDS2,AVP,HDMAP
 SG_ HAD_WorkingSt_AEB_L12 : 20|2@1+ (1,0) [0|3] ""  Gateway,CDS2
 SG_ HAD_ErrorSt_AEB_L12 : 22|1@1+ (1,0) [0|1] ""  Gateway,CDS2
 SG_ HAD_ErrorSt_ACC_L12 : 23|1@1+ (1,0) [0|1] ""  Gateway,CDS2
 SG_ HAD_WorkingSt_ACC_L12 : 37|3@1+ (1,0) [0|7] ""  Gateway,CDS2,AVP,HDMAP
 SG_ HAD_ABPReq_L12 : 41|1@1+ (1,0) [0|1] ""  Gateway,CDS2
 SG_ HAD_AWBReq_L12 : 42|1@1+ (1,0) [0|1] ""  Gateway,CDS2
 SG_ HAD_AWBlevel_L12 : 43|3@1+ (1,0) [0|7] ""  Gateway,CDS2
 SG_ HAD_CruiseModeFunctionInd : 46|2@1+ (1,0) [0|3] ""  Gateway,CDS2,AVP
 SG_ HAD_BrakeModeReq_L12 : 48|2@1+ (1,0) [0|3] ""  Gateway,CDS2
 SG_ HAD_DrivedownReq_L12 : 50|1@1+ (1,0) [0|1] ""  Gateway,CDS2
 SG_ HAD_SecureRequest_L12 : 52|1@1+ (1,0) [0|1] ""  Gateway,CDS2
 SG_ HAD_AEBSensitivity_L12 : 53|2@1+ (1,0) [0|3] ""  Gateway,CDS2
 SG_ HAD_AutoDrivingReq : 56|2@1+ (1,0) [0|3] ""  Gateway,CDS2
 SG_ LiveCounter_HAD_1 : 60|4@1+ (1,0) [0|15] ""  Gateway,CDS2,AVP,HDMAP

BO_ 281 HAD_2: 8 CDS1
 SG_ Checksum_HAD_2 : 0|8@1+ (1,0) [0|255] ""  Gateway,CDS2,HDMAP
 SG_ HAD_AutoDrivingReq_L12 : 8|2@1+ (1,0) [0|3] ""  Gateway,CDS2,HDMAP
 SG_ HAD_SpeedChangeRequest_L12 : 10|11@1+ (0.01,-10.21) [-10.21|10.26] "m/s2"  Gateway,CDS2,HDMAP
 SG_ HAD_MaxAccGrad_L12 : 24|8@1+ (0.1,0) [0|25.5] "m/s2"  Gateway,CDS2
 SG_ HAD_MinAccGrad_L12 : 32|8@1+ (0.1,0) [0|25.5] "m/s2"  Gateway,CDS2
 SG_ HAD_MaxComfBand_L12 : 40|8@1+ (0.05,0) [0|12.75] "/s2"  Gateway,CDS2
 SG_ HAD_MinComfBand_L12 : 48|8@1+ (0.05,0) [0|12.75] "/s2"  Gateway,CDS2
 SG_ HAD_UseMaxComfBand_L12 : 56|1@1+ (1,0) [0|1] ""  Gateway,CDS2
 SG_ LiveCounter_HAD_2 : 60|4@1+ (1,0) [0|15] ""  Gateway,CDS2,HDMAP

BO_TX_BU_ 260 : ADV,CDS1;
BO_TX_BU_ 256 : ADV,CDS1;

CM_ "Version:V0.0 , Date:2018-10-12 , Author: , Check: , Review: , Approval: , Description:1.First version.(ALL) ;
Version:V1.0 , Date:2018-12-20 , Author:Sun Jianlei , Check:Yin Rongbin , Review:Chen Bo , Approval: , Description:1.Delete DMS_1.(HAD°¢Gateway) , 2.Add signal HAD_DrivedownReq in message HAD_4 and add signal IFC_DrivedownReq in message IFC_6.(HAD°¢IFC°¢Gateway) , 3.Delete signal APA_BrakeModeSt_APA in message APA_1.(HAD°¢ADV°¢Gateway) , 4.Add signals WMC_Error_ESC and WMC_Error_eB in message ESC_5.(HAD°¢IFC°¢Gateway) , 5.Add message ECAS_2 and ECAS_4 on ADAS CAN.(HAD°¢IFC°¢Gateway) , 6.Add signals TyrePressureValue_FL°¢TyrePressureValue_FR°¢TyrePressureValue_RL and TyrePressureValue_RR in message TPMS_1.(Gateway°¢HAD°¢IFC°¢ADV) , 7.Add signal APA_EPBRequest in message APA_1.(HAD°¢ADV°¢Gateway) , 8.change the signal length and physical range of HCU_MCU1TMSpeed in message HCU_2_10 and HCU_MCU2TMSpeed in message HCU_2_11.(HAD°¢IFC°¢Gateway) , 9.Delete signal BrakeTorqueOnWheels in message ABS_3.(HAD°¢";
CM_ BO_ 3221225472 "This is a message for not used signals, created by Vector CANdb++ DBC OLE DB Provider.";
CM_ SG_ 459 LiveCounter_PDC_14 "The Livecounter is used to check the signal consistency of the messages . If the signals are consecutive, the LiveCounter should also be sequential in the way 0, 1, 2 °≠15, 0, 1 °≠";
CM_ SG_ 459 VehicleAngle "This signal indicates the angle of vehicle after searched a parking space.";
CM_ SG_ 459 VehicleCoordinateY "This signal indicates the coordinate Y of vehicle after searched a parking space.";
CM_ SG_ 459 VehicleCoordinateX "This signal indicates the coordinate X of vehicle after searched a parking space.";
CM_ SG_ 459 Checksum_PDC_14 "The checksum is used to check whether the data from the CPU buffer are shifted without transmission errors to the CAN communication controller buffer and vice versa.";
CM_ SG_ 605 ParkingSlotDegree_Right "This signal indicates the right parking slot degree with the curb.0xFFE means no object was detected.";
CM_ SG_ 605 ParkingSlotDegree_Left "This signal indicates the left parking slot degree with the curb.0xFFE means no object was detected.";
CM_ SG_ 605 SensorErrorSt_RRS "This signal indicates if the rear right side radar sensor error or not,";
CM_ SG_ 605 ObjectRange_RRS "This signal indicates the rear right side object's range";
CM_ SG_ 605 SensorErrorSt_RLS "This signal indicates if the rear left side radar sensor error or not,";
CM_ SG_ 605 ObjectRange_RLS "This signal indicates the rear left side object's range";
CM_ SG_ 605 SensorErrorSt_FRS "This signal indicates if the front right side radar sensor error or not,";
CM_ SG_ 605 ObjectRange_FRS "This signal indicates the front right side object's range. ";
CM_ SG_ 605 SensorErrorSt_FLS "This signal indicates if the front left side radar sensor error or not,";
CM_ SG_ 605 ObjectRange_FLS "This signal indicates the front left side object's range.";
CM_ SG_ 605 SensorBlockageSt_RRS "This signal indicates if the rear right side radar sensor Blockage or not";
CM_ SG_ 605 SensorBlockageSt_RLS "This signal indicates if the rear left side radar sensor Blockage or not";
CM_ SG_ 605 SensorBlockageSt_FRS "This signal indicates if the front right side radar sensor Blockage or not";
CM_ SG_ 605 SensorBlockageSt_FLS "This signal indicates if the front left side radar sensor Blockage or not";
CM_ SG_ 605 SensorBlockageSt_FL "This signal indicates if the front left radar sensor Blockage or not";
CM_ SG_ 605 SensorBlockageSt_FML "This signal indicates if the front middle left radar sensor Blockage or not";
CM_ SG_ 605 SensorBlockageSt_FMR "This signal indicates if the front middle right radar sensor Blockage or not";
CM_ SG_ 605 SensorBlockageSt_FR "This signal indicates if the front right radar sensor Blockage or not";
CM_ SG_ 605 SensorBlockageSt_RL "This signal indicates if the rear left radar sensor Blockage or not";
CM_ SG_ 605 SensorBlockageSt_RML "This signal indicates if therear middle right left radar sensor Blockage or not";
CM_ SG_ 605 SensorBlockageSt_RMR "This signal indicates if the rear middle right radar sensor Blockage or not";
CM_ SG_ 605 SensorBlockageSt_RR "This signal indicates if the rear right radar sensor Blockage or not";
CM_ SG_ 448 LiveCounter_PDC_3 "The Livecounter is used to check the signal consistency of the messages . If the signals are consecutive, the LiveCounter should also be sequential in the way 0, 1, 2 °≠15, 0, 1 °≠";
CM_ SG_ 448 BCoordinateX_Left "This signal indicates the X coordinate of parking cell point B.0xFFE means no object was detected.";
CM_ SG_ 448 BCoordinateY_Left "This signal indicates the Y coordinate of parking cell point B.0x3FE means no object was detected.";
CM_ SG_ 448 ACoordinateX_Left "This signal indicates the X coordinate of parking cell point A.0xFFE means no object was detected.";
CM_ SG_ 448 ACoordinateY_Left "This signal indicates the Y coordinate of parking cell point A.0x3FE means no object was detected.";
CM_ SG_ 448 Checksum_PDC_3 "The checksum is used to check whether the data from the CPU buffer are shifted without transmission errors to the CAN communication controller buffer and vice versa.";
CM_ SG_ 449 LiveCounter_PDC_4 "The Livecounter is used to check the signal consistency of the messages . If the signals are consecutive, the LiveCounter should also be sequential in the way 0, 1, 2 °≠15, 0, 1 °≠";
CM_ SG_ 449 RearObjCoordinateX "This signal indicates the X coordinate of rear object.";
CM_ SG_ 449 RearObjCoordinateY "This signal indicates the Y coordinate of rear object.";
CM_ SG_ 449 FrontObjCoordinateX "This signal indicates the X coordinate of front object.";
CM_ SG_ 449 FrontObjCoordinateY "This signal indicates the Y coordinate of front object.";
CM_ SG_ 449 Checksum_PDC_4 "The checksum is used to check whether the data from the CPU buffer are shifted without transmission errors to the CAN communication controller buffer and vice versa.";
CM_ SG_ 450 LiveCounter_PDC_5 "The Livecounter is used to check the signal consistency of the messages . If the signals are consecutive, the LiveCounter should also be sequential in the way 0, 1, 2 °≠15, 0, 1 °≠";
CM_ SG_ 450 TxRxSt_FML "Ultrasonic wave transmit and receive status of front middle left radar.";
CM_ SG_ 450 TxRxSt_FL "Ultrasonic wave transmit and receive status of front left radar.";
CM_ SG_ 450 TimeStamp_FML_FL "This signal indicates the time stamp of the obstacle detection distance by front middle left  and front left radar.";
CM_ SG_ 450 DistanceValue_FML "This signal indicates the obstacle detection distance by front middle left radar.0x3FE means no object was detected.";
CM_ SG_ 450 DistanceValue_FL "This signal indicates the obstacle detection distance by front left radar.0x3FE means no object was detected.";
CM_ SG_ 450 Checksum_PDC_5 "The checksum is used to check whether the data from the CPU buffer are shifted without transmission errors to the CAN communication controller buffer and vice versa.";
CM_ SG_ 451 LiveCounter_PDC_6 "The Livecounter is used to check the signal consistency of the messages . If the signals are consecutive, the LiveCounter should also be sequential in the way 0, 1, 2 °≠15, 0, 1 °≠";
CM_ SG_ 451 TxRxSt_FMR "Ultrasonic wave transmit and receive status of front middle right radar.";
CM_ SG_ 451 TxRxSt_FR "Ultrasonic wave transmit and receive status of front right radar.";
CM_ SG_ 451 TimeStamp_FMR_FR "This signal indicates the time stamp of the obstacle detection distance by front middle right and front right radar.";
CM_ SG_ 451 DistanceValue_FMR "This signal indicates the obstacle detection distance by front middle right radar.0x3FE means no object was detected.";
CM_ SG_ 451 DistanceValue_FR "This signal indicates the obstacle detection distance by front right radar.0x3FE means no object was detected.";
CM_ SG_ 451 Checksum_PDC_6 "The checksum is used to check whether the data from the CPU buffer are shifted without transmission errors to the CAN communication controller buffer and vice versa.";
CM_ SG_ 452 LiveCounter_PDC_7 "The Livecounter is used to check the signal consistency of the messages . If the signals are consecutive, the LiveCounter should also be sequential in the way 0, 1, 2 °≠15, 0, 1 °≠";
CM_ SG_ 452 TxRxSt_RML "Ultrasonic wave transmit and receive status of rear middle left radar.";
CM_ SG_ 452 TxRxSt_RL "Ultrasonic wave transmit and receive status of front left radar.";
CM_ SG_ 452 TimeStamp_RML_RL "This signal indicates the time stamp of the obstacle detection distance by rear middle left and rear left radar.";
CM_ SG_ 452 DistanceValue_RML "This signal indicates the obstacle detection distance by rear middle left radar.0x3FE means no object was detected.";
CM_ SG_ 452 DistanceValue_RL "This signal indicates the obstacle detection distance by rear left radar.0x3FE means no object was detected.";
CM_ SG_ 452 Checksum_PDC_7 "The checksum is used to check whether the data from the CPU buffer are shifted without transmission errors to the CAN communication controller buffer and vice versa.";
CM_ SG_ 453 LiveCounter_PDC_8 "The Livecounter is used to check the signal consistency of the messages . If the signals are consecutive, the LiveCounter should also be sequential in the way 0, 1, 2 °≠15, 0, 1 °≠";
CM_ SG_ 453 TxRxSt_RMR "Ultrasonic wave transmit and receive status of rear middle right radar.";
CM_ SG_ 453 TxRxSt_RR "Ultrasonic wave transmit and receive status of rear right radar.";
CM_ SG_ 453 TimeStamp_RMR_RR "This signal indicates the time stamp of the obstacle detection distance by rear middle right and rear right radar.";
CM_ SG_ 453 DistanceValue_RMR "This signal indicates the obstacle detection distance by rear middle right radar.0x3FE means no object was detected.";
CM_ SG_ 453 DistanceValue_RR "This signal indicates the obstacle detection distance by rear right radar.0x3FE means no object was detected.";
CM_ SG_ 453 Checksum_PDC_8 "The checksum is used to check whether the data from the CPU buffer are shifted without transmission errors to the CAN communication controller buffer and vice versa.";
CM_ SG_ 454 LiveCounter_PDC_9 "The Livecounter is used to check the signal consistency of the messages . If the signals are consecutive, the LiveCounter should also be sequential in the way 0, 1, 2 °≠15, 0, 1 °≠";
CM_ SG_ 454 ParkingSlotDepth_Left "This signal indicates the left parking slot depth.0x3FE means no object was detected.";
CM_ SG_ 454 TimeStamp_FLS_FRS "This signal indicates the time stamp of the obstacle detection distance by front left side and front right side radar.";
CM_ SG_ 454 DistanceValue_FRS "This signal indicates the obstacle detection distance by front right side radar.0x3FE means no object was detected.";
CM_ SG_ 454 DistanceValue_FLS "This signal indicates the obstacle detection distance by front left side radar.0x3FE means no object was detected.";
CM_ SG_ 454 Checksum_PDC_9 "The checksum is used to check whether the data from the CPU buffer are shifted without transmission errors to the CAN communication controller buffer and vice versa.";
CM_ SG_ 192 Checksum_ABS_1 "The checksum is used to check whether the data from the CPU buffer are shifted without transmission errors to the CAN communication controller buffer and vice versa.";
CM_ SG_ 192 WheelSpeed_FL "This signal is front left wheel speed which sent by ABS without filtering. ";
CM_ SG_ 192 WheelSpeed_FR "This signal is front right wheel speed which sent by ABS without filtering.";
CM_ SG_ 192 AvailableSt_EPBSwitch "This signal indicates the available status of EPB switch";
CM_ SG_ 192 VehiclSpeed "The signal describes the raw vehicle speed calculated by ABS. The ABS calculates the vehicle speed based on the raw wheel speed signals from the wheel speed sensors. The vehicle speed output could be the average of the wheel speeds of the driven axle.";
CM_ SG_ 192 VehiclSpeed_Q "Qualifier for VehicleSpeed";
CM_ SG_ 192 DrivingDirection "The signal indicates driving direction of the vehicle.";
CM_ SG_ 192 EPBSwitch "Indicates the EPB switch is pressed or not.";
CM_ SG_ 192 LiveCounter_ABS_1 "The Livecounter is used to check the signal consistency of the messages . If the signals are consecutive, the LiveCounter should also be sequential in the way 0, 1, 2 °≠15, 0, 1 °≠";
CM_ SG_ 194 Checksum_ABS_2 "The checksum is used to check whether the data from the CPU buffer are shifted without transmission errors to the CAN communication controller buffer and vice versa.";
CM_ SG_ 194 WheelSpeed_RL "This signal is rear left wheel speed which sent by ABS without filtering.";
CM_ SG_ 194 WheelSpeed_RR "This signal is rear right wheel speed which sent by ABS without filtering.";
CM_ SG_ 194 MasterCylinderPressure "The signal indicates the actual pressure in the master cylinder.";
CM_ SG_ 194 LiveCounter_ABS_2 "The Livecounter is used to check the signal consistency of the messages . If the signals are consecutive, the LiveCounter should also be sequential in the way 0, 1, 2 °≠15, 0, 1 °≠";
CM_ SG_ 304 Checksum_ABS_3 "The checksum is used to check whether the data from the CPU buffer are shifted without transmission errors to the CAN communication controller buffer and vice versa.";
CM_ SG_ 304 WheelPulse_FL "This signal is the front left wheel speed pulse(raw data).";
CM_ SG_ 304 WheelPulse_FR "This signal is the front right wheel speed pulse(raw data).";
CM_ SG_ 304 WheelPulse_RL "This signal is the rear left wheel speed pulse(raw data).";
CM_ SG_ 304 WheelPulse_RR "This signal is the rear right wheel speed pulse(raw data).";
CM_ SG_ 304 WheelSpeedDirection_FL "This signal is the the front left wheel speed direction.";
CM_ SG_ 304 WheelSpeedDirection_FR "This signal is the the front right wheel speed direction.";
CM_ SG_ 304 WheelSpeedDirection_RL "This signal is the the rear left wheel speed direction.";
CM_ SG_ 304 WheelSpeedDirection_RR "This signal is the the rear right  wheel speed direction.";
CM_ SG_ 304 LiveCounter_ABS_3 "The Livecounter is used to check the signal consistency of the messages . If the signals are consecutive, the LiveCounter should also be sequential in the way 0, 1, 2 °≠15, 0, 1 °≠";
CM_ SG_ 306 Checksum_ESC_2_1 "The checksum is used to check whether the data from the CPU buffer are shifted without transmission errors to the CAN communication controller buffer and vice versa.";
CM_ SG_ 306 WorkingSt_ESC "This signal indicates the ESC system working status.";
CM_ SG_ 306 ErrorSt_ESC "This signal indicates the ESC function error status,including VDC and TCS.";
CM_ SG_ 306 Intervention_ESC "The signal is indicates if theESC function is intervention or not.";
CM_ SG_ 306 ErrorSt_ABS "This signal indicates the ABS function error status.";
CM_ SG_ 306 Intervention_ABS "The signal indicates if the ABS function is intervention or not.";
CM_ SG_ 306 Intervention_TCS "The signal indicates if the TCS function is intervention or not.";
CM_ SG_ 306 ErrorSt_EBD "This signal indicates the EBD function error status.";
CM_ SG_ 306 AvailableSt_CDP "This signal Indicates if the CDP function is available or not";
CM_ SG_ 306 Intervention_CDP_RWU "The signal is indicates if the CDP or RWU or SRU function is intervention or not.";
CM_ SG_ 306 LampCmd_EPB "The signal indicates the working status of EPB.";
CM_ SG_ 306 ErrotSt_EPB "This signal indicates the EPB error status.";
CM_ SG_ 306 AvailableSt_HDC "This signal indicates if the HDC function is available or not";
CM_ SG_ 306 WorkingSt_HDC "The signal indicates the working status of HDC.";
CM_ SG_ 306 ErrorSt_AVH "This signal indicates if the AVH function is error or not";
CM_ SG_ 306 WorkingSt_AVH "The signal indicates the woking status of AVH.
When AVH is standby , it means AVH is On, but not active braking.
When AVH is active , it means AVH is On and active braking.
When AVH is inactive, it  means AVH already on but not ready intervention";
CM_ SG_ 306 AvailableSt_CDDS "This signal Indicates if the CDD-s function is available or not.";
CM_ SG_ 306 Intervention_CDDS "This signal Indicates the CDD-S function is intervention or not.";
CM_ SG_ 306 AvailableSt_AEB "This signal indicates the AEB function is available or not.";
CM_ SG_ 306 Intervention_AEB "The signal is indicates if the AEB function is intervention or not.";
CM_ SG_ 306 AvailableSt_ABP "This signal indicates the ABP function is available or not.";
CM_ SG_ 306 Intervention_ABP "The signal is indicates if the  ABP function is intervention or not.";
CM_ SG_ 306 AvailableSt_AWB "This signal indicates if the AWB function is available or not";
CM_ SG_ 306 Intervention_AWB "The signal is indicates if the AWB function is intervention or not.";
CM_ SG_ 306 AvailableSt_HBA "This signal indicates if the HBA is available or not";
CM_ SG_ 306 Intervention_HBA "This signal Indicates if the HBA is intervention or not.";
CM_ SG_ 306 WorkingSt_HBB "This signal indicates the working status of HBB.";
CM_ SG_ 306 Intervention_HBB "This signal indicates if the HBB function is intervention or not";
CM_ SG_ 306 Intervention_EmergencyBrake "The signal is indicates if the EmergencyBrake is Intervention or not.
This signal is only used for L1L2.L3 use another signal.";
CM_ SG_ 306 VehicleStandstillSt "The signal indicates the vehicle whether is in standstill or not.";
CM_ SG_ 306 BrakeLightCtrlCmd "The signal indicates the brake light control command.";
CM_ SG_ 306 WorkingSt_EPB "The signal indicates the working status of EPB.";
CM_ SG_ 306 APA_Available_ESC "Indicates the EPB switch is pressed or not.";
CM_ SG_ 306 APA_Intervention_ESC "This signal Indicates if the APA is intervention or not.";
CM_ SG_ 306 LiveCounter_ESC_2_1 "The Livecounter is used to check the signal consistency of the messages . If the signals are consecutive, the LiveCounter should also be sequential in the way 0, 1, 2 °≠15, 0, 1 °≠";
CM_ SG_ 308 Checksum_ESC_3_1 "The checksum is used to check whether the data from the CPU buffer are shifted without transmission errors to the CAN communication controller buffer and vice versa.";
CM_ SG_ 308 YawRate "This signal indicates the yaw rate data (real data; sign depends on mounting position)
anticlockwise=positive, clockwise=negative";
CM_ SG_ 308 YRSSt "This signal indicates the status of yaw rate sensor";
CM_ SG_ 308 Acceleration_X "The signal is LongitudinalAcceleration(exact value).Positive value represents  forward,  negative value represents backward. ";
CM_ SG_ 308 YawRate_Raw "This signal indicates the yaw rate data (raw data)
anticlockwise=positive, clockwise=negative";
CM_ SG_ 308 Acceleration_Y "The signal is Lateral Acceleration(exact value).Positive value represents right side of vehicle, negative value represents  left side of vehicle. ";
CM_ SG_ 308 ErrorSt_YRS "This signal indicates if the YRS is error or not.";
CM_ SG_ 308 LiveCounter_ESC_3_1 "The Livecounter is used to check the signal consistency of the messages . If the signals are consecutive, the LiveCounter should also be sequential in the way 0, 1, 2 °≠15, 0, 1 °≠";
CM_ SG_ 312 Checksum_ESC_5_1 "The checksum is used to check whether the data from the CPU buffer are shifted without transmission errors to the CAN communication controller buffer and vice versa.";
CM_ SG_ 312 ESC_AutoPark_LCSt "This signal indicates the longitudinal controller status";
CM_ SG_ 312 ESC_AutoPark_LCFailureSt "This signal indicates  the failure of the longitudinal controller";
CM_ SG_ 312 ESC_AutoPark_LC_BrakeMode "This signal indicates Longitudinal controller brake mode";
CM_ SG_ 312 ESC_LSMAvail_Parking "Availability Feedback for LSM Motion Service";
CM_ SG_ 312 ESC_AutoPark_LC_APA_Avail "This signal indicates if the APA function available or not ";
CM_ SG_ 312 ESC_VLCSt_L12 "This signal indicates the vehicle longitudinal control status for L12 autodriving function.";
CM_ SG_ 312 ESC_VLCSt_L3 "This signal indicates the vehicle longitudinal control status for L3 autodriving function.";
CM_ SG_ 312 ESC_VLC_Error_L12 "This signal indicates ESC is available for L12 autodriving function or not.";
CM_ SG_ 312 ESC_VMC_Error_L3 "This signal indicates VMC system in ESC is available for L3 autodriving function or not.";
CM_ SG_ 312 ESC_AutoDriving_LC_Brakemode "This signal indicates Longitudinal controller brake mode";
CM_ SG_ 312 ESC_AutoPark_LC_RPA_Avail "This signal indicates if the RPA function available or not ";
CM_ SG_ 312 ESC_AutoParkingSt_Feedback "The feedback signal to °∞APA_AutoParkingReq°±";
CM_ SG_ 312 ESC_BrakePedalStatus "Indacates whether the pedal is applied by the driver.";
CM_ SG_ 312 ESC_BrakePedalStatus_Q "Qualifier for eB_BrakePedalStatus";
CM_ SG_ 312 ESC_BrakePedalDominant_Q "Qualifier for BrakePedalDominant";
CM_ SG_ 312 ESC_BrakePedalDominant "Indacates  the pedal is applied request by the driver is dominant or not.";
CM_ SG_ 312 ESC_AutoPark_LC_AVP_Avail "This signal indicates if the AVP function available or not ";
CM_ SG_ 312 ESC_ShutOffFinished "Indicates  that the shut off of VMC is finished.";
CM_ SG_ 312 LiveCounter_ESC_5_1 "The Livecounter is used to check the signal consistency of the messages . If the signals are consecutive, the LiveCounter should also be sequential in the way 0, 1, 2 °≠15, 0, 1 °≠";
CM_ SG_ 319 Checksum_ESC_7_1 "The checksum is used to check whether the data from the CPU buffer are shifted without transmission errors to the CAN communication controller buffer and vice versa.";
CM_ SG_ 319 ESC_SuspendStatus_VMC "This signal indicates if the VMC system is suspend";
CM_ SG_ 319 ESC_BrakeFunctionOverrideStatus "This signal indicates whether the brake function request override superior system";
CM_ SG_ 319 LiveCounter_ESC_7_1 "The Livecounter is used to check the signal consistency of the messages . If the signals are consecutive, the LiveCounter should also be sequential in the way 0, 1, 2 °≠15, 0, 1 °≠";
CM_ SG_ 160 ESC_BrakeFxAvailability "availability to process external Fx request";
CM_ SG_ 160 ESC_BrakeFxActual "estimated current longitudinal brake force";
CM_ SG_ 161 ESC_DrvReqTarFxBrakeAvail "quality of °∞DrvReqTarFxBrake°±";
CM_ SG_ 161 ESC_DrvReqTarFxBrake "brake force requested by driver over brake pedal";
CM_ SG_ 161 ESC_BrakeFxTarget "Target brake force request from superior system";
CM_ SG_ 317 Checksum_eB_2 "The checksum is used to check whether the data from the CPU buffer are shifted without transmission errors to the CAN communication controller buffer and vice versa.";
CM_ SG_ 317 eB_TargetGearReq_VMC "eBooster request to change the lever  position.";
CM_ SG_ 317 eB_VLCSt_L3 "This signal indicates the vehicle longitudinal control status for L3 autodriving function.";
CM_ SG_ 317 eB_VMC_Error_L3 "This signal indicates VMC system in eBOOSTER is available for L3 autodriving function or not.";
CM_ SG_ 317 eB_VMC_Error_Parking "This signal indicates VMC system in eB is available for autoParking function or not.";
CM_ SG_ 317 eB_SuspendStatus_VMC "This signal indicates if the VMC system is suspend";
CM_ SG_ 317 eB_ShutOffFinished_L3 "Indicates  that the shut off of VMC is finished.";
CM_ SG_ 317 LiveCounter_eB_2 "The Livecounter is used to check the signal consistency of the messages . If the signals are consecutive, the LiveCounter should also be sequential in the way 0, 1, 2 °≠15, 0, 1 °≠";
CM_ SG_ 336 EPS_1_HandSteeringTorque "The signal indicates the torque measured by the torque sensor at the steering wheel. In case of a sensor error, the default value (0x3FF) of the signal is set";
CM_ SG_ 336 EPS_1_HandSteeringTorqueSign "Indicates sign of hand steering torque (+/-)
Hand steering torque to left = positive
Hand steering torque to right = negative
";
CM_ SG_ 336 EPS_1_ErrorStatus "Error indication of the EPS system";
CM_ SG_ 336 EPS_1_HandOffStatus "Detect if the driver is controlling the steering wheel";
CM_ SG_ 336 EPS_1_HandOffValid "Indicates if the hand off signal is valid or not.";
CM_ SG_ 336 EPS_1_LKAStatus "The signal indicates the status of LDP(LKA) function ";
CM_ SG_ 336 EPS_1_OverlayInputTorque "The signal indicates the actual applied overlay toque in EPS.";
CM_ SG_ 336 EPS_1_OverlayInputTorqueSign "Indicates sign of OverlayInputTorque (+/-)
Hand steering torque to left = positive
Hand steering torque to right = negative
";
CM_ SG_ 336 EPS_1_AbortFeedback_HAD "EPS APA Abort Feedback";
CM_ SG_ 337 Checksum_EPS_1_2 "The checksum is used to check whether the data from the CPU buffer are shifted without transmission errors to the CAN communication controller buffer and vice versa.";
CM_ SG_ 337 EPS_1_SACCStatus "The signal indicates the status of SACC/LCA/HWA/TJA function ";
CM_ SG_ 337 EPS_1_HWPStatus "The signal indicates the status of SACCfunction ";
CM_ SG_ 337 EPS_1_TJPStatus "The signal indicates the status of TJA function ";
CM_ SG_ 337 EPS_1_APAStatus "The signal indicates the status of APA function ";
CM_ SG_ 337 EPS_1_RPAStatus "The signal indicates the status of RPA function ";
CM_ SG_ 337 EPS_1_AVPStatus "The signal indicates the status of AVP function ";
CM_ SG_ 337 EPS_1_DegradeLevel_HAD "EPS capability description under different faults for autonomous Driving";
CM_ SG_ 337 EPS_1_DriftWarning "Indicates the vehicle is drifted over threshold value or not ";
CM_ SG_ 337 EPS_1_AutoDrivingMode "Which auto driving/parking mode is active";
CM_ SG_ 337 LiveCounter_EPS_1_2 "The Livecounter is used to check the signal consistency of the messages . If the signals are consecutive, the LiveCounter should also be sequential in the way 0, 1, 2 °≠15, 0, 1 °≠";
CM_ SG_ 208 Checksum_EPS_1_SAS_1 "The checksum is used to check whether the data from the CPU buffer are shifted without transmission errors to the CAN communication controller buffer and vice versa.";
CM_ SG_ 208 SteeringWheelAngle "This signal indicates the angle of steering wheel .";
CM_ SG_ 208 SteeringWheelAngleSign "This signal shows the direction of steering wheel angle, it's used in pairs with °∞SteeringWheelAngle°±.";
CM_ SG_ 208 SteeringWheelSpeed "This signal indicates the teering wheel rotation speed.";
CM_ SG_ 208 SteeringWheelSpeedSign "This signal shows the direction of steering wheel speed, it's used in pairs with °∞SteeringWheelSpeed°±. ";
CM_ SG_ 208 SAS_St "The signal indicates the status of SAS. ";
CM_ SG_ 208 LiveCounter_EPS_1_SAS_1 "The Livecounter is used to check the signal consistency of the messages . If the signals are consecutive, the LiveCounter should also be sequential in the way 0, 1, 2 °≠15, 0, 1 °≠";
CM_ SG_ 534 DMS_VehicleModeInfo "The signal indicates the vehicle mode.";
CM_ SG_ 534 DMS_ErrorStatus "DMS error status";
CM_ SG_ 534 DMS_TargetVehicleMode "Indicates the target vehicle mode of DMS";
CM_ SG_ 290 Checksum_HCU_2_12 "The checksum is used to check whether the data from the CPU buffer are shifted without transmission errors to the CAN communication controller buffer and vice versa.";
CM_ SG_ 290 HCU_LeverInfo "This signal indicate Lever info for display";
CM_ SG_ 290 HCU_AutoParkingResponse_L12 "The signal indicates if HCU can response the L12 autoparking request";
CM_ SG_ 290 HCU_AutoParkingResponse_L3 "The signal indicates if HCU can response the L3 autoparking request";
CM_ SG_ 290 HCU_CapabilitySt_AutoParking "The signal is the capability of HCU for auto parking functions.";
CM_ SG_ 290 Livecounter_HCU_2_12 "The Livecounter is used to check the signal consistency of the messages . If the signals are consecutive, the LiveCounter should also be sequential in the way 0, 1, 2 °≠15, 0, 1 °≠";
CM_ SG_ 264 Checksum_HCU_2_4 "The checksum is used to check whether the data from the CPU buffer are shifted without transmission errors to the CAN communication controller buffer and vice versa.";
CM_ SG_ 264 HCU_AutoDrivingResponseSt_L12 "The signal indicates if HCU can response the L12 autodriving request or not.";
CM_ SG_ 264 HCU_AutoDrivingResponseSt_L3 "The signal indicates if HCU can response the L3 autodriving request or not.";
CM_ SG_ 264 HCU_CapabilitySt_AutoDriving "The signal is the capability of HCU for auto driving functions.";
CM_ SG_ 264 LiveCounter_HCU_2_4 "The Livecounter is used to check the signal consistency of the messages . If the signals are consecutive, the LiveCounter should also be sequential in the way 0, 1, 2 °≠15, 0, 1 °≠";
CM_ SG_ 147 HCU_EVReady "EV system can run or not";
CM_ SG_ 146 Checksum_HCU_2_2 "The checksum is used to check whether the data from the CPU buffer are shifted without transmission errors to the CAN communication controller buffer and vice versa.";
CM_ SG_ 146 HCU_AccelerationPedalPosition "This signal indicates the actual acceleration pedal position";
CM_ SG_ 146 HCU_CalcAccelerationPedalPositio "This signal indicates the calculated acceleration pedal position in cruise control mode.";
CM_ SG_ 146 HCU_AccelerationPedalOverride "This signal indicates the torque demanded by the driver is higher than the torque demanded by ACC.";
CM_ SG_ 146 HCU_KickdownReq "This signal is used to show the fast acceleration request from the driver. ";
CM_ SG_ 146 LiveCounter_HCU_2_2 "The Livecounter is used to check the signal consistency of the messages . If the signals are consecutive, the LiveCounter should also be sequential in the way 0, 1, 2 °≠15, 0, 1 °≠";
CM_ SG_ 151 HCU_MCU1TMSpeed "The TM Speed of MCU1";
CM_ SG_ 151 HCU_MCU1ActTMTorque "The Actual TM Drive Torque of MCU1";
CM_ SG_ 151 HCU_MCU1TMMAMTorque "The TM Maximum Available Motoring Torque of MCU1";
CM_ SG_ 151 HCU_MCU1TMMAGTorque "The TM Maximum Available Generating Torque of MCU1";
CM_ SG_ 152 HCU_MCU2TMSpeed "The TM Speed of MCU2";
CM_ SG_ 152 HCU_MCU2ActTMTorque "The Actual TM Drive Torque of MCU2";
CM_ SG_ 152 HCU_MCU2TMMAMTorque "The TM Maximum Available Motoring Torque of MCU2";
CM_ SG_ 152 HCU_MCU2TMMAGTorque "The TM Maximum Available Generating Torque of MCU2";
CM_ SG_ 288 EGSM_SecurityButton "This signal indicate the security button in the knob is pressed or not.";
CM_ SG_ 288 EGSM_SecurityButtonErrorSt "This signal indicate the security button in the knob is error or not.";
CM_ SG_ 288 EGSM_ErrorStatus "Indicate the SBW system error";
CM_ SG_ 512 Checksum_ACU_1 "The checksum is used to check whether the data from the CPU buffer are shifted without transmission errors to the CAN communication controller buffer and vice versa.";
CM_ SG_ 512 CrashInfo "This signal indicates the crash is happened or not. ECUs received the crash info for crash mode.";
CM_ SG_ 512 SysSt_ACU "The signal is sent to IC to display the ACU system information. ";
CM_ SG_ 512 SeatBeltSt_Driver "The signal is sent to indicate the Driver Seat Belt is buckled or Unbuckled.";
CM_ SG_ 512 LiveCounter_ACU_1 "The Livecounter is used to check the signal consistency of the messages . If the signals are consecutive, the LiveCounter should also be sequential in the way 0, 1, 2 °≠15, 0, 1 °≠";
CM_ SG_ 260 Checksum_APA_1 "The checksum is used to check whether the data from the CPU buffer are shifted without transmission errors to the CAN communication controller buffer and vice versa.";
CM_ SG_ 260 APA_StopDistance "This signal inform the ESC the parking target distance ";
CM_ SG_ 260 APA_SpeedLimitation "This signal inform ESC the velocity maximum";
CM_ SG_ 260 APA_FailureBrakeMode "This signal indicates the brake mode when APA/RPA failure";
CM_ SG_ 260 TargetGearRequest_PSC "This signal indicates the target gear position";
CM_ SG_ 260 APA_PrefillRequest_Parking "Brake Prefill request";
CM_ SG_ 260 APA_SecureRequest "In the emergency condition,APA requests P locking and push EPB.
This signal is used for L1L2L3 function.";
CM_ SG_ 260 APA_ComfortBrakeReq "Comfort Brake Mode Request";
CM_ SG_ 260 APA_AutoParkingReq "HAD request to active auto parking function.
";
CM_ SG_ 260 APA_DirectionCmd "The heading direction command from HAD/ADV in APA/RPA function.";
CM_ SG_ 260 APA_AutoParkReq "The active status from HAD/ADV of APA/RPA function.";
CM_ SG_ 260 APA_BrakeFunctionMode "This signal indicate which function mode the ESC enters";
CM_ SG_ 260 LiveCounter_APA_1 "The Livecounter is used to check the signal consistency of the messages . If the signals are consecutive, the LiveCounter should also be sequential in the way 0, 1, 2 °≠15, 0, 1 °≠";
CM_ SG_ 256 ADV_ErrorSt "This signal indicates ADV is error or not.If the value of this signal is °∞Error°Æ,EPS shoud ignore this message and respond the message from ADV.";
CM_ SG_ 256 ADV_AutoParkingModeReq "Auto parking mode request";
CM_ SG_ 256 ADV_AutoParkingRequestSt "Auto Parking request status";
CM_ SG_ 256 ADV_DisableECASAdjust "Indicates the system is parking,ECAS cannot be adjust by other commands.";
CM_ SG_ 256 ADV_ECASNormalRequest "Indicates ADV request ECAS to adjust to normal height.";
CM_ SG_ 256 ADV_ErrorSt_APA "ADV system capbility for TJP";
CM_ SG_ 256 ADV_ErrorSt_RPA "ADV system capbility for APA/RPA";
CM_ SG_ 256 ADV_ErrorSt_AVP "ADV system capbility for AVP";
CM_ SG_ 256 ADV_WorkingSt_APA "This signal indicates the APA working status.,Signal Initial=last value";
CM_ SG_ 256 ADV_WorkingSt_RPA "This signal indicates the RPA working status.,Signal Initial=last value";
CM_ SG_ 256 ADV_WorkingSt_AVP "This signal indicates the AVP working status.,Signal Initial=last value";
CM_ SG_ 256 ADV_SteeringWheelAngleRequest "Steering Wheel Angle Request";
CM_ SG_ 256 ADV_SteeringWheelAngleSignReques "Steering Wheel Angle Sign Request";
CM_ SG_ 256 ADV_SteeringWheelAngleControlReq "Steering Wheel Angle Control Request";
CM_ SG_ 280 Checksum_HAD_1 "The checksum is used to check whether the data from the CPU buffer are shifted without transmission errors to the CAN communication controller buffer and vice versa.";
CM_ SG_ 280 HAD_WorkingSt_AEB_L12 "This signal indicates the AEB working status.";
CM_ SG_ 280 HAD_ErrorSt_AEB_L12 "This signal indicates the AEB error status.";
CM_ SG_ 280 HAD_ErrorSt_ACC_L12 "This signal indicates the ACC error status.";
CM_ SG_ 280 HAD_WorkingSt_ACC_L12 "This signal indicates the ACC working status.";
CM_ SG_ 280 HAD_ABPReq_L12 "This signal indicates the request for prefill function.";
CM_ SG_ 280 HAD_AWBReq_L12 "This signal in the request of the brake jerk warning to ESC.";
CM_ SG_ 280 HAD_AWBlevel_L12 "This signal indicates the different level request of the brake jerk warning.";
CM_ SG_ 280 HAD_CruiseModeFunctionInd "This signal indicates setting result of the configuration of cruise mode function.,Signal Initial=last value";
CM_ SG_ 280 HAD_BrakeModeReq_L12 "This signal indicate HAD request to brake cosily or urgently.
This signal is only used for L12 function";
CM_ SG_ 280 HAD_DrivedownReq_L12 "HAD request to quit out the auto pilot function.
This signal is only used for L12 function";
CM_ SG_ 280 HAD_SecureRequest_L12 "HAD request to stop the car safely.
This signal is only used for L12 function";
CM_ SG_ 280 HAD_AEBSensitivity_L12 "This signal indicates the sensitivity of AEB function";
CM_ SG_ 280 HAD_AutoDrivingReq "Auto driving function active request from HAD to HCU.";
CM_ SG_ 280 LiveCounter_HAD_1 "The Livecounter is used to check the signal consistency of the messages . If the signals are consecutive, the LiveCounter should also be sequential in the way 0, 1, 2 °≠15, 0, 1 °≠";
CM_ SG_ 281 Checksum_HAD_2 "The checksum is used to check whether the data from the CPU buffer are shifted without transmission errors to the CAN communication controller buffer and vice versa.";
CM_ SG_ 281 HAD_AutoDrivingReq_L12 "This signal indicates the acceleration or deceleration command is from L1L2 function or L3 function.";
CM_ SG_ 281 HAD_SpeedChangeRequest_L12 "This signal is the value of acceleration request or deceleration request(L1L2).";
CM_ SG_ 281 HAD_MaxAccGrad_L12 "The maximum acceleration gradient allowed by HAD";
CM_ SG_ 281 HAD_MinAccGrad_L12 "The minimum acceleration gradient allowed by HAD";
CM_ SG_ 281 HAD_MaxComfBand_L12 "Upper limit for acceleration comfort zone ";
CM_ SG_ 281 HAD_MinComfBand_L12 "Low limit for acceleartion comfort zone";
CM_ SG_ 281 HAD_UseMaxComfBand_L12 "HAD request to use the upper limit value of acceleration comfort zone.
";
CM_ SG_ 281 LiveCounter_HAD_2 "The Livecounter is used to check the signal consistency of the messages . If the signals are consecutive, the LiveCounter should also be sequential in the way 0, 1, 2 °≠15, 0, 1 °≠";
BA_DEF_  "ProtocolType" STRING ;
BA_DEF_ BU_  "NmAsrCanMsgReducedTime" INT 0 65535;
BA_DEF_ SG_  "GenSigStartValue" INT 0 1000000000;
BA_DEF_ BO_  "GenMsgILSupport" ENUM  "No","Yes";
BA_DEF_ BO_  "CanTpSTmin" INT 0 0;
BA_DEF_ BO_  "CanTpFcFrameId" HEX 0 2147483647;
BA_DEF_  "NmAsrBaseAddress" HEX 0 2047;
BA_DEF_  "NmAsrMessageCount" INT 1 256;
BA_DEF_  "NmType" STRING ;
BA_DEF_  "Baudrate" INT 0 1000000;
BA_DEF_  "Manufacturer" STRING ;
BA_DEF_  "NmAsrWaitBusSleepTime" INT 0 65535;
BA_DEF_  "NmAsrTimeoutTime" INT 0 65535;
BA_DEF_  "NmAsrRepeatMessageTime" INT 0 65535;
BA_DEF_  "NmAsrCanMsgCycleTime" INT 0 65535;
BA_DEF_  "VersionNumber" INT 0 99;
BA_DEF_  "VersionYear" INT 1 99;
BA_DEF_  "VersionMonth" INT 1 12;
BA_DEF_  "VersionDay" INT 1 31;
BA_DEF_ SG_  "GenSigSendType" ENUM  "Cyclic","OnWrite","OnWriteWithRepetition","OnChange","OnChangeWithRepetition","IfActive","IfActiveWithRepetition","NoSigSendType";
BA_DEF_ BO_  "GenMsgCycleTime" INT 0 50000;
BA_DEF_ BO_  "GenMsgSendType" ENUM  "Cyclic","not_used","not_used","not_used","not_used","Cyclic","not_used","IfActive","NoMsgSendType","Spontaneous","CyclicAndSpontaneous","NoMsgSendType";
BA_DEF_  "DBName" STRING ;
BA_DEF_  "BusType" STRING ;
BA_DEF_ SG_  "GenSigInvalidValue" INT 0 0;
BA_DEF_ SG_  "GenSigStartRemark" STRING ;
BA_DEF_ SG_  "GenSigInvalidRemark" STRING ;
BA_DEF_ SG_  "GenSigEvent" STRING ;
BA_DEF_ SG_  "SystemSignalLongSymbol" STRING ;
BA_DEF_REL_ BU_SG_REL_  "GenSigTimeoutTime" INT 0 5000;
BA_DEF_DEF_  "ProtocolType" "*";
BA_DEF_DEF_  "NmAsrCanMsgReducedTime" 50;
BA_DEF_DEF_  "GenSigStartValue" 0;
BA_DEF_DEF_  "GenMsgILSupport" "Yes";
BA_DEF_DEF_  "CanTpSTmin" 1;
BA_DEF_DEF_  "CanTpFcFrameId" 2147483647;
BA_DEF_DEF_  "NmAsrBaseAddress" 1280;
BA_DEF_DEF_  "NmAsrMessageCount" 128;
BA_DEF_DEF_  "NmType" "NmAsr";
BA_DEF_DEF_  "Baudrate" 500000;
BA_DEF_DEF_  "Manufacturer" "FAW";
BA_DEF_DEF_  "NmAsrWaitBusSleepTime" 750;
BA_DEF_DEF_  "NmAsrTimeoutTime" 1000;
BA_DEF_DEF_  "NmAsrRepeatMessageTime" 400;
BA_DEF_DEF_  "NmAsrCanMsgCycleTime" 100;
BA_DEF_DEF_  "VersionNumber" 0;
BA_DEF_DEF_  "VersionYear" 1;
BA_DEF_DEF_  "VersionMonth" 1;
BA_DEF_DEF_  "VersionDay" 1;
BA_DEF_DEF_  "GenSigSendType" "NoSigSendType";
BA_DEF_DEF_  "GenMsgCycleTime" 0;
BA_DEF_DEF_  "GenMsgSendType" "NoMsgSendType";
BA_DEF_DEF_  "DBName" "";
BA_DEF_DEF_  "BusType" "CAN";
BA_DEF_DEF_  "GenSigInvalidValue" 0;
BA_DEF_DEF_  "GenSigStartRemark" "";
BA_DEF_DEF_  "GenSigInvalidRemark" "";
BA_DEF_DEF_  "GenSigEvent" "";
BA_DEF_DEF_REL_ "GenSigTimeoutTime" 0;
BA_DEF_DEF_  "SystemSignalLongSymbol" "";
BA_ "VersionYear" 20;
BA_ "VersionMonth" 8;
BA_ "VersionDay" 14;
BA_ "VersionNumber" 3;
BA_ "DBName" "FAW_E115_ADAS_Network_CANDBC";
BA_ "GenMsgSendType" BO_ 265 0;
BA_ "GenMsgCycleTime" BO_ 265 10;
BA_ "GenMsgSendType" BO_ 416 0;
BA_ "GenMsgCycleTime" BO_ 416 100;
BA_ "GenMsgSendType" BO_ 704 0;
BA_ "GenMsgCycleTime" BO_ 704 20;
BA_ "GenMsgSendType" BO_ 706 0;
BA_ "GenMsgCycleTime" BO_ 706 100;
BA_ "GenMsgSendType" BO_ 708 0;
BA_ "GenMsgCycleTime" BO_ 708 100;
BA_ "GenMsgSendType" BO_ 276 0;
BA_ "GenMsgCycleTime" BO_ 276 100;
BA_ "GenMsgSendType" BO_ 459 0;
BA_ "GenMsgCycleTime" BO_ 459 50;
BA_ "GenMsgSendType" BO_ 605 0;
BA_ "GenMsgCycleTime" BO_ 605 100;
BA_ "GenMsgSendType" BO_ 448 0;
BA_ "GenMsgCycleTime" BO_ 448 50;
BA_ "GenMsgSendType" BO_ 449 0;
BA_ "GenMsgCycleTime" BO_ 449 50;
BA_ "GenMsgSendType" BO_ 450 0;
BA_ "GenMsgCycleTime" BO_ 450 50;
BA_ "GenMsgSendType" BO_ 451 0;
BA_ "GenMsgCycleTime" BO_ 451 50;
BA_ "GenMsgSendType" BO_ 452 0;
BA_ "GenMsgCycleTime" BO_ 452 50;
BA_ "GenMsgSendType" BO_ 453 0;
BA_ "GenMsgCycleTime" BO_ 453 50;
BA_ "GenMsgSendType" BO_ 454 0;
BA_ "GenMsgCycleTime" BO_ 454 50;
BA_ "GenMsgSendType" BO_ 192 0;
BA_ "GenMsgCycleTime" BO_ 192 10;
BA_ "GenMsgSendType" BO_ 194 0;
BA_ "GenMsgCycleTime" BO_ 194 10;
BA_ "GenMsgSendType" BO_ 304 0;
BA_ "GenMsgCycleTime" BO_ 304 20;
BA_ "GenMsgSendType" BO_ 306 0;
BA_ "GenMsgCycleTime" BO_ 306 20;
BA_ "GenMsgSendType" BO_ 308 0;
BA_ "GenMsgCycleTime" BO_ 308 20;
BA_ "GenMsgSendType" BO_ 312 0;
BA_ "GenMsgCycleTime" BO_ 312 20;
BA_ "GenMsgSendType" BO_ 319 0;
BA_ "GenMsgCycleTime" BO_ 319 20;
BA_ "GenMsgSendType" BO_ 160 0;
BA_ "GenMsgCycleTime" BO_ 160 10;
BA_ "GenMsgSendType" BO_ 161 0;
BA_ "GenMsgCycleTime" BO_ 161 10;
BA_ "GenMsgSendType" BO_ 317 0;
BA_ "GenMsgCycleTime" BO_ 317 20;
BA_ "GenMsgSendType" BO_ 336 0;
BA_ "GenMsgCycleTime" BO_ 336 20;
BA_ "GenMsgSendType" BO_ 337 0;
BA_ "GenMsgCycleTime" BO_ 337 20;
BA_ "GenMsgSendType" BO_ 208 0;
BA_ "GenMsgCycleTime" BO_ 208 10;
BA_ "GenMsgSendType" BO_ 534 0;
BA_ "GenMsgCycleTime" BO_ 534 100;
BA_ "GenMsgSendType" BO_ 290 0;
BA_ "GenMsgCycleTime" BO_ 290 20;
BA_ "GenMsgSendType" BO_ 264 0;
BA_ "GenMsgCycleTime" BO_ 264 20;
BA_ "GenMsgSendType" BO_ 147 0;
BA_ "GenMsgCycleTime" BO_ 147 10;
BA_ "GenMsgSendType" BO_ 146 0;
BA_ "GenMsgCycleTime" BO_ 146 10;
BA_ "GenMsgSendType" BO_ 151 0;
BA_ "GenMsgCycleTime" BO_ 151 10;
BA_ "GenMsgSendType" BO_ 152 0;
BA_ "GenMsgCycleTime" BO_ 152 10;
BA_ "GenMsgSendType" BO_ 288 0;
BA_ "GenMsgCycleTime" BO_ 288 20;
BA_ "GenMsgCycleTime" BO_ 512 100;
BA_ "GenMsgSendType" BO_ 512 0;
BA_ "GenMsgSendType" BO_ 260 0;
BA_ "GenMsgCycleTime" BO_ 260 20;
BA_ "GenMsgSendType" BO_ 256 0;
BA_ "GenMsgCycleTime" BO_ 256 20;
BA_ "GenMsgSendType" BO_ 280 0;
BA_ "GenMsgCycleTime" BO_ 280 20;
BA_ "GenMsgSendType" BO_ 281 0;
BA_ "GenMsgCycleTime" BO_ 281 20;
BA_ "GenSigInvalidRemark" SG_ 265 SVB1_AccelerationRequest "O";
BA_ "GenSigInvalidValue" SG_ 265 SVB1_AccelerationRequest 63;
BA_ "GenSigInvalidValue" SG_ 265 SVB1_SteeringSpeedRequest 511;
BA_ "GenSigInvalidRemark" SG_ 265 SVB1_SteeringAngleRequest "O";
BA_ "GenSigInvalidValue" SG_ 265 SVB1_SteeringAngleRequest 1023;
BA_ "GenSigInvalidValue" SG_ 265 SVB1_DecelerationRequest 1023;
BA_ "GenSigStartValue" SG_ 265 SVB1_DecelerationRequest 1000;
BA_ "GenSigStartRemark" SG_ 265 Checksum_SVB1_1 "V";
BA_ "GenSigStartRemark" SG_ 416 Checksum_SVB1_2 "V";
BA_ "GenSigInvalidValue" SG_ 416 SVB1_EPBRequest 3;
BA_ "GenSigInvalidRemark" SG_ 459 VehicleCoordinateY "2000";
BA_ "GenSigStartRemark" SG_ 459 VehicleCoordinateY "2000";
BA_ "GenSigInvalidValue" SG_ 459 VehicleCoordinateY 4095;
BA_ "GenSigStartValue" SG_ 459 VehicleCoordinateY 4094;
BA_ "GenSigInvalidRemark" SG_ 459 VehicleCoordinateX "5000";
BA_ "GenSigStartRemark" SG_ 459 VehicleCoordinateX "5000";
BA_ "GenSigInvalidValue" SG_ 459 VehicleCoordinateX 8191;
BA_ "GenSigStartValue" SG_ 459 VehicleCoordinateX 8190;
BA_ "GenSigStartRemark" SG_ 459 Checksum_PDC_14 "V";
BA_ "GenSigInvalidRemark" SG_ 605 ParkingSlotDegree_Right "1800";
BA_ "GenSigStartRemark" SG_ 605 ParkingSlotDegree_Right "1800";
BA_ "GenSigInvalidValue" SG_ 605 ParkingSlotDegree_Right 4095;
BA_ "GenSigStartValue" SG_ 605 ParkingSlotDegree_Right 4094;
BA_ "GenSigInvalidRemark" SG_ 605 ParkingSlotDegree_Left "1800";
BA_ "GenSigStartRemark" SG_ 605 ParkingSlotDegree_Left "1800";
BA_ "GenSigInvalidValue" SG_ 605 ParkingSlotDegree_Left 4095;
BA_ "GenSigStartValue" SG_ 605 ParkingSlotDegree_Left 4094;
BA_ "GenSigEvent" SG_ 605 ObjectRange_RRS "Y";
BA_ "GenSigSendType" SG_ 605 ObjectRange_RRS 1;
BA_ "GenSigInvalidValue" SG_ 605 ObjectRange_RRS 7;
BA_ "GenSigEvent" SG_ 605 ObjectRange_RLS "Y";
BA_ "GenSigSendType" SG_ 605 ObjectRange_RLS 1;
BA_ "GenSigInvalidValue" SG_ 605 ObjectRange_RLS 7;
BA_ "GenSigEvent" SG_ 605 ObjectRange_FRS "Y";
BA_ "GenSigSendType" SG_ 605 ObjectRange_FRS 1;
BA_ "GenSigInvalidValue" SG_ 605 ObjectRange_FRS 7;
BA_ "GenSigEvent" SG_ 605 ObjectRange_FLS "Y";
BA_ "GenSigSendType" SG_ 605 ObjectRange_FLS 1;
BA_ "GenSigInvalidValue" SG_ 605 ObjectRange_FLS 7;
BA_ "GenSigInvalidRemark" SG_ 448 BCoordinateX_Left "3600";
BA_ "GenSigStartRemark" SG_ 448 BCoordinateX_Left "3600";
BA_ "GenSigInvalidValue" SG_ 448 BCoordinateX_Left 4095;
BA_ "GenSigStartValue" SG_ 448 BCoordinateX_Left 4094;
BA_ "GenSigInvalidRemark" SG_ 448 BCoordinateY_Left "500";
BA_ "GenSigStartRemark" SG_ 448 BCoordinateY_Left "500";
BA_ "GenSigInvalidValue" SG_ 448 BCoordinateY_Left 1023;
BA_ "GenSigStartValue" SG_ 448 BCoordinateY_Left 1022;
BA_ "GenSigInvalidRemark" SG_ 448 ACoordinateX_Left "3600";
BA_ "GenSigStartRemark" SG_ 448 ACoordinateX_Left "3600";
BA_ "GenSigInvalidValue" SG_ 448 ACoordinateX_Left 4095;
BA_ "GenSigStartValue" SG_ 448 ACoordinateX_Left 4094;
BA_ "GenSigInvalidRemark" SG_ 448 ACoordinateY_Left "500";
BA_ "GenSigStartRemark" SG_ 448 ACoordinateY_Left "500";
BA_ "GenSigInvalidValue" SG_ 448 ACoordinateY_Left 1023;
BA_ "GenSigStartValue" SG_ 448 ACoordinateY_Left 1022;
BA_ "GenSigStartRemark" SG_ 448 Checksum_PDC_3 "V";
BA_ "GenSigInvalidRemark" SG_ 449 RearObjCoordinateX "4000";
BA_ "GenSigStartRemark" SG_ 449 RearObjCoordinateX "4000";
BA_ "GenSigInvalidValue" SG_ 449 RearObjCoordinateX 4095;
BA_ "GenSigStartValue" SG_ 449 RearObjCoordinateX 4094;
BA_ "GenSigInvalidRemark" SG_ 449 RearObjCoordinateY "4000";
BA_ "GenSigStartRemark" SG_ 449 RearObjCoordinateY "4000";
BA_ "GenSigInvalidValue" SG_ 449 RearObjCoordinateY 4095;
BA_ "GenSigStartValue" SG_ 449 RearObjCoordinateY 4094;
BA_ "GenSigInvalidRemark" SG_ 449 FrontObjCoordinateX "4000";
BA_ "GenSigStartRemark" SG_ 449 FrontObjCoordinateX "4000";
BA_ "GenSigInvalidValue" SG_ 449 FrontObjCoordinateX 4095;
BA_ "GenSigStartValue" SG_ 449 FrontObjCoordinateX 4094;
BA_ "GenSigInvalidRemark" SG_ 449 FrontObjCoordinateY "4000";
BA_ "GenSigStartRemark" SG_ 449 FrontObjCoordinateY "4000";
BA_ "GenSigInvalidValue" SG_ 449 FrontObjCoordinateY 4095;
BA_ "GenSigStartValue" SG_ 449 FrontObjCoordinateY 4094;
BA_ "GenSigStartRemark" SG_ 449 Checksum_PDC_4 "V";
BA_ "GenSigInvalidRemark" SG_ 450 DistanceValue_FML "500";
BA_ "GenSigStartRemark" SG_ 450 DistanceValue_FML "500";
BA_ "GenSigInvalidValue" SG_ 450 DistanceValue_FML 1023;
BA_ "GenSigStartValue" SG_ 450 DistanceValue_FML 1022;
BA_ "GenSigInvalidRemark" SG_ 450 DistanceValue_FL "500";
BA_ "GenSigStartRemark" SG_ 450 DistanceValue_FL "500";
BA_ "GenSigInvalidValue" SG_ 450 DistanceValue_FL 1023;
BA_ "GenSigStartValue" SG_ 450 DistanceValue_FL 1022;
BA_ "GenSigStartRemark" SG_ 450 Checksum_PDC_5 "V";
BA_ "GenSigInvalidRemark" SG_ 451 DistanceValue_FMR "500";
BA_ "GenSigStartRemark" SG_ 451 DistanceValue_FMR "500";
BA_ "GenSigInvalidValue" SG_ 451 DistanceValue_FMR 1023;
BA_ "GenSigStartValue" SG_ 451 DistanceValue_FMR 1022;
BA_ "GenSigInvalidRemark" SG_ 451 DistanceValue_FR "500";
BA_ "GenSigStartRemark" SG_ 451 DistanceValue_FR "500";
BA_ "GenSigInvalidValue" SG_ 451 DistanceValue_FR 1023;
BA_ "GenSigStartValue" SG_ 451 DistanceValue_FR 1022;
BA_ "GenSigStartRemark" SG_ 451 Checksum_PDC_6 "V";
BA_ "GenSigInvalidRemark" SG_ 452 DistanceValue_RML "500";
BA_ "GenSigStartRemark" SG_ 452 DistanceValue_RML "500";
BA_ "GenSigInvalidValue" SG_ 452 DistanceValue_RML 1023;
BA_ "GenSigStartValue" SG_ 452 DistanceValue_RML 1022;
BA_ "GenSigInvalidRemark" SG_ 452 DistanceValue_RL "500";
BA_ "GenSigStartRemark" SG_ 452 DistanceValue_RL "500";
BA_ "GenSigInvalidValue" SG_ 452 DistanceValue_RL 1023;
BA_ "GenSigStartValue" SG_ 452 DistanceValue_RL 1022;
BA_ "GenSigStartRemark" SG_ 452 Checksum_PDC_7 "V";
BA_ "GenSigInvalidRemark" SG_ 453 DistanceValue_RMR "500";
BA_ "GenSigStartRemark" SG_ 453 DistanceValue_RMR "500";
BA_ "GenSigInvalidValue" SG_ 453 DistanceValue_RMR 1023;
BA_ "GenSigStartValue" SG_ 453 DistanceValue_RMR 1022;
BA_ "GenSigInvalidRemark" SG_ 453 DistanceValue_RR "500";
BA_ "GenSigStartRemark" SG_ 453 DistanceValue_RR "500";
BA_ "GenSigInvalidValue" SG_ 453 DistanceValue_RR 1023;
BA_ "GenSigStartValue" SG_ 453 DistanceValue_RR 1022;
BA_ "GenSigStartRemark" SG_ 453 Checksum_PDC_8 "V";
BA_ "GenSigInvalidRemark" SG_ 454 ParkingSlotDepth_Left "500";
BA_ "GenSigStartRemark" SG_ 454 ParkingSlotDepth_Left "500";
BA_ "GenSigInvalidValue" SG_ 454 ParkingSlotDepth_Left 1023;
BA_ "GenSigStartValue" SG_ 454 ParkingSlotDepth_Left 1022;
BA_ "GenSigInvalidRemark" SG_ 454 DistanceValue_FRS "500";
BA_ "GenSigStartRemark" SG_ 454 DistanceValue_FRS "500";
BA_ "GenSigInvalidValue" SG_ 454 DistanceValue_FRS 1023;
BA_ "GenSigStartValue" SG_ 454 DistanceValue_FRS 1022;
BA_ "GenSigInvalidRemark" SG_ 454 DistanceValue_FLS "500";
BA_ "GenSigStartRemark" SG_ 454 DistanceValue_FLS "500";
BA_ "GenSigInvalidValue" SG_ 454 DistanceValue_FLS 1023;
BA_ "GenSigStartValue" SG_ 454 DistanceValue_FLS 1022;
BA_ "GenSigStartRemark" SG_ 454 Checksum_PDC_9 "V";
BA_ "GenSigStartRemark" SG_ 192 Checksum_ABS_1 "V";
BA_ "GenSigInvalidRemark" SG_ 192 WheelSpeed_FL "O";
BA_ "GenSigStartRemark" SG_ 192 WheelSpeed_FL "O";
BA_ "GenSigInvalidValue" SG_ 192 WheelSpeed_FL 32767;
BA_ "GenSigStartValue" SG_ 192 WheelSpeed_FL 32766;
BA_ "GenSigInvalidRemark" SG_ 192 WheelSpeed_FR "O";
BA_ "GenSigStartRemark" SG_ 192 WheelSpeed_FR "O";
BA_ "GenSigInvalidValue" SG_ 192 WheelSpeed_FR 32767;
BA_ "GenSigStartValue" SG_ 192 WheelSpeed_FR 32766;
BA_ "GenSigInvalidRemark" SG_ 192 VehiclSpeed "O";
BA_ "GenSigStartRemark" SG_ 192 VehiclSpeed "O";
BA_ "GenSigInvalidValue" SG_ 192 VehiclSpeed 32767;
BA_ "GenSigStartValue" SG_ 192 VehiclSpeed 32766;
BA_ "GenSigInvalidValue" SG_ 192 VehiclSpeed_Q 3;
BA_ "GenSigInvalidValue" SG_ 192 DrivingDirection 3;
BA_ "GenSigInvalidValue" SG_ 192 EPBSwitch 3;
BA_ "GenSigStartRemark" SG_ 194 Checksum_ABS_2 "V";
BA_ "GenSigInvalidRemark" SG_ 194 WheelSpeed_RL "O";
BA_ "GenSigStartRemark" SG_ 194 WheelSpeed_RL "O";
BA_ "GenSigInvalidValue" SG_ 194 WheelSpeed_RL 32767;
BA_ "GenSigStartValue" SG_ 194 WheelSpeed_RL 32766;
BA_ "GenSigInvalidRemark" SG_ 194 WheelSpeed_RR "O";
BA_ "GenSigStartRemark" SG_ 194 WheelSpeed_RR "O";
BA_ "GenSigInvalidValue" SG_ 194 WheelSpeed_RR 32767;
BA_ "GenSigStartValue" SG_ 194 WheelSpeed_RR 32766;
BA_ "GenSigInvalidRemark" SG_ 194 MasterCylinderPressure "2000";
BA_ "GenSigStartRemark" SG_ 194 MasterCylinderPressure "2000";
BA_ "GenSigInvalidValue" SG_ 194 MasterCylinderPressure 2047;
BA_ "GenSigStartValue" SG_ 194 MasterCylinderPressure 2046;
BA_ "GenSigStartRemark" SG_ 304 Checksum_ABS_3 "V";
BA_ "GenSigInvalidRemark" SG_ 304 WheelPulse_FL "O";
BA_ "GenSigStartRemark" SG_ 304 WheelPulse_FL "O";
BA_ "GenSigInvalidValue" SG_ 304 WheelPulse_FL 255;
BA_ "GenSigStartValue" SG_ 304 WheelPulse_FL 254;
BA_ "GenSigInvalidRemark" SG_ 304 WheelPulse_FR "O";
BA_ "GenSigStartRemark" SG_ 304 WheelPulse_FR "O";
BA_ "GenSigInvalidValue" SG_ 304 WheelPulse_FR 255;
BA_ "GenSigStartValue" SG_ 304 WheelPulse_FR 254;
BA_ "GenSigInvalidRemark" SG_ 304 WheelPulse_RL "O";
BA_ "GenSigStartRemark" SG_ 304 WheelPulse_RL "O";
BA_ "GenSigInvalidValue" SG_ 304 WheelPulse_RL 255;
BA_ "GenSigStartValue" SG_ 304 WheelPulse_RL 254;
BA_ "GenSigInvalidRemark" SG_ 304 WheelPulse_RR "O";
BA_ "GenSigStartRemark" SG_ 304 WheelPulse_RR "O";
BA_ "GenSigInvalidValue" SG_ 304 WheelPulse_RR 255;
BA_ "GenSigStartValue" SG_ 304 WheelPulse_RR 254;
BA_ "GenSigInvalidValue" SG_ 304 WheelSpeedDirection_FL 3;
BA_ "GenSigInvalidValue" SG_ 304 WheelSpeedDirection_FR 3;
BA_ "GenSigInvalidValue" SG_ 304 WheelSpeedDirection_RL 3;
BA_ "GenSigInvalidValue" SG_ 304 WheelSpeedDirection_RR 3;
BA_ "GenSigStartRemark" SG_ 306 Checksum_ESC_2_1 "V";
BA_ "GenSigStartValue" SG_ 306 WorkingSt_ESC 1;
BA_ "GenSigStartValue" SG_ 306 AvailableSt_HBA 1;
BA_ "GenSigStartRemark" SG_ 308 Checksum_ESC_3_1 "V";
BA_ "GenSigInvalidRemark" SG_ 308 YawRate "4000";
BA_ "GenSigStartRemark" SG_ 308 YawRate "4000";
BA_ "GenSigInvalidValue" SG_ 308 YawRate 4095;
BA_ "GenSigStartValue" SG_ 308 YawRate 4094;
BA_ "GenSigInvalidRemark" SG_ 308 Acceleration_X "1592";
BA_ "GenSigStartRemark" SG_ 308 Acceleration_X "1592";
BA_ "GenSigInvalidValue" SG_ 308 Acceleration_X 2047;
BA_ "GenSigStartValue" SG_ 308 Acceleration_X 2046;
BA_ "GenSigInvalidRemark" SG_ 308 YawRate_Raw "4000";
BA_ "GenSigStartRemark" SG_ 308 YawRate_Raw "4000";
BA_ "GenSigInvalidValue" SG_ 308 YawRate_Raw 4095;
BA_ "GenSigStartValue" SG_ 308 YawRate_Raw 4094;
BA_ "GenSigInvalidRemark" SG_ 308 Acceleration_Y "1592";
BA_ "GenSigStartRemark" SG_ 308 Acceleration_Y "1592";
BA_ "GenSigInvalidValue" SG_ 308 Acceleration_Y 2047;
BA_ "GenSigStartValue" SG_ 308 Acceleration_Y 2046;
BA_ "GenSigStartRemark" SG_ 312 Checksum_ESC_5_1 "V";
BA_ "GenSigInvalidValue" SG_ 312 ESC_AutoPark_LCSt 7;
BA_ "GenSigInvalidValue" SG_ 312 ESC_AutoPark_LCFailureSt 7;
BA_ "GenSigStartRemark" SG_ 319 Checksum_ESC_7_1 "V";
BA_ "GenSigStartRemark" SG_ 160 Checksum_ESC_eB_1 "V";
BA_ "GenSigStartRemark" SG_ 161 Checksum_ESC_eB_2 "V";
BA_ "GenSigStartRemark" SG_ 317 Checksum_eB_2 "V";
BA_ "GenSigStartRemark" SG_ 336 Checksum_EPS_1_1 "V";
BA_ "GenSigInvalidRemark" SG_ 336 EPS_1_HandSteeringTorque "1000";
BA_ "GenSigStartRemark" SG_ 336 EPS_1_HandSteeringTorque "1000";
BA_ "GenSigInvalidValue" SG_ 336 EPS_1_HandSteeringTorque 1023;
BA_ "GenSigStartValue" SG_ 336 EPS_1_HandSteeringTorque 1022;
BA_ "GenSigInvalidRemark" SG_ 336 EPS_1_OverlayInputTorque "1000";
BA_ "GenSigStartRemark" SG_ 336 EPS_1_OverlayInputTorque "1000";
BA_ "GenSigInvalidValue" SG_ 336 EPS_1_OverlayInputTorque 1023;
BA_ "GenSigStartValue" SG_ 336 EPS_1_OverlayInputTorque 1022;
BA_ "GenSigStartRemark" SG_ 337 Checksum_EPS_1_2 "V";
BA_ "GenSigStartRemark" SG_ 208 Checksum_EPS_1_SAS_1 "V";
BA_ "GenSigInvalidRemark" SG_ 208 SteeringWheelAngle "O";
BA_ "GenSigInvalidValue" SG_ 208 SteeringWheelAngle 32767;
BA_ "GenSigInvalidRemark" SG_ 208 SteeringWheelSpeed "O";
BA_ "GenSigInvalidValue" SG_ 208 SteeringWheelSpeed 32767;
BA_ "GenSigStartValue" SG_ 208 SAS_St 1;
BA_ "GenSigInvalidValue" SG_ 534 DMS_VehicleModeInfo 15;
BA_ "GenSigInvalidValue" SG_ 534 DMS_TargetVehicleMode 15;
BA_ "GenSigStartRemark" SG_ 290 Checksum_HCU_2_12 "V";
BA_ "GenSigInvalidValue" SG_ 290 HCU_LeverInfo 7;
BA_ "GenSigStartValue" SG_ 290 HCU_LeverInfo 5;
BA_ "GenSigStartRemark" SG_ 264 Checksum_HCU_2_4 "V";
BA_ "GenSigStartRemark" SG_ 147 Checksum_HCU_2_7 "V";
BA_ "GenSigStartRemark" SG_ 146 Checksum_HCU_2_2 "V";
BA_ "GenSigInvalidRemark" SG_ 146 HCU_AccelerationPedalPosition "250";
BA_ "GenSigStartRemark" SG_ 146 HCU_AccelerationPedalPosition "250";
BA_ "GenSigInvalidValue" SG_ 146 HCU_AccelerationPedalPosition 255;
BA_ "GenSigStartValue" SG_ 146 HCU_AccelerationPedalPosition 254;
BA_ "GenSigInvalidRemark" SG_ 146 HCU_CalcAccelerationPedalPositio "250";
BA_ "GenSigStartRemark" SG_ 146 HCU_CalcAccelerationPedalPositio "250";
BA_ "GenSigInvalidValue" SG_ 146 HCU_CalcAccelerationPedalPositio 255;
BA_ "GenSigStartValue" SG_ 146 HCU_CalcAccelerationPedalPositio 254;
BA_ "SystemSignalLongSymbol" SG_ 146 HCU_CalcAccelerationPedalPositio "HCU_CalcAccelerationPedalPosition";
BA_ "GenSigInvalidRemark" SG_ 151 HCU_MCU1TMSpeed "60000";
BA_ "GenSigStartRemark" SG_ 151 HCU_MCU1TMSpeed "60000";
BA_ "GenSigInvalidValue" SG_ 151 HCU_MCU1TMSpeed 65535;
BA_ "GenSigStartValue" SG_ 151 HCU_MCU1TMSpeed 65534;
BA_ "GenSigInvalidRemark" SG_ 151 HCU_MCU1ActTMTorque "16000";
BA_ "GenSigStartRemark" SG_ 151 HCU_MCU1ActTMTorque "16000";
BA_ "GenSigInvalidValue" SG_ 151 HCU_MCU1ActTMTorque 16383;
BA_ "GenSigStartValue" SG_ 151 HCU_MCU1ActTMTorque 16382;
BA_ "GenSigInvalidRemark" SG_ 151 HCU_MCU1TMMAMTorque "8000";
BA_ "GenSigStartRemark" SG_ 151 HCU_MCU1TMMAMTorque "8000";
BA_ "GenSigInvalidValue" SG_ 151 HCU_MCU1TMMAMTorque 8191;
BA_ "GenSigStartValue" SG_ 151 HCU_MCU1TMMAMTorque 8190;
BA_ "GenSigInvalidRemark" SG_ 151 HCU_MCU1TMMAGTorque "8000";
BA_ "GenSigStartRemark" SG_ 151 HCU_MCU1TMMAGTorque "8000";
BA_ "GenSigInvalidValue" SG_ 151 HCU_MCU1TMMAGTorque 8191;
BA_ "GenSigStartValue" SG_ 151 HCU_MCU1TMMAGTorque 8190;
BA_ "GenSigInvalidRemark" SG_ 152 HCU_MCU2TMSpeed "60000";
BA_ "GenSigStartRemark" SG_ 152 HCU_MCU2TMSpeed "60000";
BA_ "GenSigInvalidValue" SG_ 152 HCU_MCU2TMSpeed 65535;
BA_ "GenSigStartValue" SG_ 152 HCU_MCU2TMSpeed 65534;
BA_ "GenSigInvalidRemark" SG_ 152 HCU_MCU2ActTMTorque "16000";
BA_ "GenSigStartRemark" SG_ 152 HCU_MCU2ActTMTorque "16000";
BA_ "GenSigInvalidValue" SG_ 152 HCU_MCU2ActTMTorque 16383;
BA_ "GenSigStartValue" SG_ 152 HCU_MCU2ActTMTorque 16382;
BA_ "GenSigInvalidRemark" SG_ 152 HCU_MCU2TMMAMTorque "8000";
BA_ "GenSigStartRemark" SG_ 152 HCU_MCU2TMMAMTorque "8000";
BA_ "GenSigInvalidValue" SG_ 152 HCU_MCU2TMMAMTorque 8191;
BA_ "GenSigStartValue" SG_ 152 HCU_MCU2TMMAMTorque 8190;
BA_ "GenSigInvalidRemark" SG_ 152 HCU_MCU2TMMAGTorque "8000";
BA_ "GenSigStartRemark" SG_ 152 HCU_MCU2TMMAGTorque "8000";
BA_ "GenSigInvalidValue" SG_ 152 HCU_MCU2TMMAGTorque 8191;
BA_ "GenSigStartValue" SG_ 152 HCU_MCU2TMMAGTorque 8190;
BA_ "GenSigStartRemark" SG_ 288 Checksum_EGSM_1 "V";
BA_ "GenSigStartRemark" SG_ 512 Checksum_ACU_1 "V";
BA_ "GenSigEvent" SG_ 512 CrashInfo "Y";
BA_ "GenSigSendType" SG_ 512 CrashInfo 1;
BA_ "GenSigEvent" SG_ 512 SeatBeltSt_Driver "Y";
BA_ "GenSigSendType" SG_ 512 SeatBeltSt_Driver 1;
BA_ "GenSigStartRemark" SG_ 260 Checksum_APA_1 "V";
BA_ "GenSigInvalidValue" SG_ 260 TargetGearRequest_PSC 7;
BA_ "GenSigInvalidValue" SG_ 260 APA_ComfortBrakeReq 3;
BA_ "GenSigStartRemark" SG_ 256 Checksum_ADV_2 "V";
BA_ "GenSigStartRemark" SG_ 256 ADV_WorkingSt_APA "L";
BA_ "GenSigStartRemark" SG_ 256 ADV_WorkingSt_RPA "L";
BA_ "GenSigStartRemark" SG_ 256 ADV_WorkingSt_AVP "L";
BA_ "GenSigInvalidRemark" SG_ 256 ADV_SteeringWheelAngleRequest "O";
BA_ "GenSigInvalidValue" SG_ 256 ADV_SteeringWheelAngleRequest 32767;
BA_ "SystemSignalLongSymbol" SG_ 256 ADV_SteeringWheelAngleSignReques "ADV_SteeringWheelAngleSignRequest";
BA_ "SystemSignalLongSymbol" SG_ 256 ADV_SteeringWheelAngleControlReq "ADV_SteeringWheelAngleControlRequest";
BA_ "GenSigStartRemark" SG_ 280 Checksum_HAD_1 "V";
BA_ "GenSigStartValue" SG_ 280 HAD_WorkingSt_AEB_L12 1;
BA_ "GenSigStartRemark" SG_ 280 HAD_CruiseModeFunctionInd "L";
BA_ "GenSigStartRemark" SG_ 281 Checksum_HAD_2 "V";
BA_ "GenSigInvalidRemark" SG_ 281 HAD_SpeedChangeRequest_L12 "2042";
BA_ "GenSigStartRemark" SG_ 281 HAD_SpeedChangeRequest_L12 "2042";
BA_ "GenSigInvalidValue" SG_ 281 HAD_SpeedChangeRequest_L12 2047;
BA_ "GenSigStartValue" SG_ 281 HAD_SpeedChangeRequest_L12 2046;
BA_ "GenSigInvalidRemark" SG_ 281 HAD_MaxAccGrad_L12 "127";
BA_ "GenSigStartRemark" SG_ 281 HAD_MaxAccGrad_L12 "127";
BA_ "GenSigInvalidValue" SG_ 281 HAD_MaxAccGrad_L12 255;
BA_ "GenSigStartValue" SG_ 281 HAD_MaxAccGrad_L12 254;
BA_ "GenSigInvalidRemark" SG_ 281 HAD_MinAccGrad_L12 "127";
BA_ "GenSigStartRemark" SG_ 281 HAD_MinAccGrad_L12 "127";
BA_ "GenSigInvalidValue" SG_ 281 HAD_MinAccGrad_L12 255;
BA_ "GenSigStartValue" SG_ 281 HAD_MinAccGrad_L12 254;
BA_ "GenSigInvalidRemark" SG_ 281 HAD_MaxComfBand_L12 "90";
BA_ "GenSigStartRemark" SG_ 281 HAD_MaxComfBand_L12 "90";
BA_ "GenSigInvalidValue" SG_ 281 HAD_MaxComfBand_L12 255;
BA_ "GenSigStartValue" SG_ 281 HAD_MaxComfBand_L12 254;
BA_ "GenSigInvalidRemark" SG_ 281 HAD_MinComfBand_L12 "90";
BA_ "GenSigStartRemark" SG_ 281 HAD_MinComfBand_L12 "90";
BA_ "GenSigInvalidValue" SG_ 281 HAD_MinComfBand_L12 255;
BA_ "GenSigStartValue" SG_ 281 HAD_MinComfBand_L12 254;
BA_REL_ "GenSigTimeoutTime" BU_SG_REL_ AVM SG_ 459 LiveCounter_PDC_14 500;
BA_REL_ "GenSigTimeoutTime" BU_SG_REL_ AVP SG_ 459 LiveCounter_PDC_14 500;
BA_REL_ "GenSigTimeoutTime" BU_SG_REL_ ADV SG_ 459 LiveCounter_PDC_14 500;
BA_REL_ "GenSigTimeoutTime" BU_SG_REL_ AVM SG_ 459 VehicleAngle 500;
BA_REL_ "GenSigTimeoutTime" BU_SG_REL_ AVP SG_ 459 VehicleAngle 500;
BA_REL_ "GenSigTimeoutTime" BU_SG_REL_ ADV SG_ 459 VehicleAngle 500;
BA_REL_ "GenSigTimeoutTime" BU_SG_REL_ AVM SG_ 459 VehicleCoordinateY 500;
BA_REL_ "GenSigTimeoutTime" BU_SG_REL_ AVP SG_ 459 VehicleCoordinateY 500;
BA_REL_ "GenSigTimeoutTime" BU_SG_REL_ ADV SG_ 459 VehicleCoordinateY 500;
BA_REL_ "GenSigTimeoutTime" BU_SG_REL_ AVM SG_ 459 VehicleCoordinateX 500;
BA_REL_ "GenSigTimeoutTime" BU_SG_REL_ AVP SG_ 459 VehicleCoordinateX 500;
BA_REL_ "GenSigTimeoutTime" BU_SG_REL_ ADV SG_ 459 VehicleCoordinateX 500;
BA_REL_ "GenSigTimeoutTime" BU_SG_REL_ AVM SG_ 459 Checksum_PDC_14 500;
BA_REL_ "GenSigTimeoutTime" BU_SG_REL_ AVP SG_ 459 Checksum_PDC_14 500;
BA_REL_ "GenSigTimeoutTime" BU_SG_REL_ ADV SG_ 459 Checksum_PDC_14 500;
BA_REL_ "GenSigTimeoutTime" BU_SG_REL_ AVM SG_ 605 ParkingSlotDegree_Right 1000;
BA_REL_ "GenSigTimeoutTime" BU_SG_REL_ AVP SG_ 605 ParkingSlotDegree_Right 1000;
BA_REL_ "GenSigTimeoutTime" BU_SG_REL_ AVM SG_ 605 ParkingSlotDegree_Left 1000;
BA_REL_ "GenSigTimeoutTime" BU_SG_REL_ AVP SG_ 605 ParkingSlotDegree_Left 1000;
BA_REL_ "GenSigTimeoutTime" BU_SG_REL_ AVM SG_ 605 SensorErrorSt_RRS 1000;
BA_REL_ "GenSigTimeoutTime" BU_SG_REL_ AVP SG_ 605 SensorErrorSt_RRS 1000;
BA_REL_ "GenSigTimeoutTime" BU_SG_REL_ ADV SG_ 605 SensorErrorSt_RRS 1000;
BA_REL_ "GenSigTimeoutTime" BU_SG_REL_ Gateway SG_ 605 SensorErrorSt_RRS 1000;
BA_REL_ "GenSigTimeoutTime" BU_SG_REL_ AVM SG_ 605 ObjectRange_RRS 1000;
BA_REL_ "GenSigTimeoutTime" BU_SG_REL_ AVP SG_ 605 ObjectRange_RRS 1000;
BA_REL_ "GenSigTimeoutTime" BU_SG_REL_ ADV SG_ 605 ObjectRange_RRS 1000;
BA_REL_ "GenSigTimeoutTime" BU_SG_REL_ Gateway SG_ 605 ObjectRange_RRS 1000;
BA_REL_ "GenSigTimeoutTime" BU_SG_REL_ AVM SG_ 605 SensorErrorSt_RLS 1000;
BA_REL_ "GenSigTimeoutTime" BU_SG_REL_ AVP SG_ 605 SensorErrorSt_RLS 1000;
BA_REL_ "GenSigTimeoutTime" BU_SG_REL_ ADV SG_ 605 SensorErrorSt_RLS 1000;
BA_REL_ "GenSigTimeoutTime" BU_SG_REL_ Gateway SG_ 605 SensorErrorSt_RLS 1000;
BA_REL_ "GenSigTimeoutTime" BU_SG_REL_ AVM SG_ 605 ObjectRange_RLS 1000;
BA_REL_ "GenSigTimeoutTime" BU_SG_REL_ AVP SG_ 605 ObjectRange_RLS 1000;
BA_REL_ "GenSigTimeoutTime" BU_SG_REL_ ADV SG_ 605 ObjectRange_RLS 1000;
BA_REL_ "GenSigTimeoutTime" BU_SG_REL_ Gateway SG_ 605 ObjectRange_RLS 1000;
BA_REL_ "GenSigTimeoutTime" BU_SG_REL_ AVM SG_ 605 SensorErrorSt_FRS 1000;
BA_REL_ "GenSigTimeoutTime" BU_SG_REL_ AVP SG_ 605 SensorErrorSt_FRS 1000;
BA_REL_ "GenSigTimeoutTime" BU_SG_REL_ ADV SG_ 605 SensorErrorSt_FRS 1000;
BA_REL_ "GenSigTimeoutTime" BU_SG_REL_ Gateway SG_ 605 SensorErrorSt_FRS 1000;
BA_REL_ "GenSigTimeoutTime" BU_SG_REL_ AVM SG_ 605 ObjectRange_FRS 1000;
BA_REL_ "GenSigTimeoutTime" BU_SG_REL_ AVP SG_ 605 ObjectRange_FRS 1000;
BA_REL_ "GenSigTimeoutTime" BU_SG_REL_ ADV SG_ 605 ObjectRange_FRS 1000;
BA_REL_ "GenSigTimeoutTime" BU_SG_REL_ Gateway SG_ 605 ObjectRange_FRS 1000;
BA_REL_ "GenSigTimeoutTime" BU_SG_REL_ AVM SG_ 605 SensorErrorSt_FLS 1000;
BA_REL_ "GenSigTimeoutTime" BU_SG_REL_ AVP SG_ 605 SensorErrorSt_FLS 1000;
BA_REL_ "GenSigTimeoutTime" BU_SG_REL_ ADV SG_ 605 SensorErrorSt_FLS 1000;
BA_REL_ "GenSigTimeoutTime" BU_SG_REL_ Gateway SG_ 605 SensorErrorSt_FLS 1000;
BA_REL_ "GenSigTimeoutTime" BU_SG_REL_ AVM SG_ 605 ObjectRange_FLS 1000;
BA_REL_ "GenSigTimeoutTime" BU_SG_REL_ AVP SG_ 605 ObjectRange_FLS 1000;
BA_REL_ "GenSigTimeoutTime" BU_SG_REL_ ADV SG_ 605 ObjectRange_FLS 1000;
BA_REL_ "GenSigTimeoutTime" BU_SG_REL_ Gateway SG_ 605 ObjectRange_FLS 1000;
BA_REL_ "GenSigTimeoutTime" BU_SG_REL_ AVM SG_ 605 SensorBlockageSt_RRS 1000;
BA_REL_ "GenSigTimeoutTime" BU_SG_REL_ AVP SG_ 605 SensorBlockageSt_RRS 1000;
BA_REL_ "GenSigTimeoutTime" BU_SG_REL_ ADV SG_ 605 SensorBlockageSt_RRS 1000;
BA_REL_ "GenSigTimeoutTime" BU_SG_REL_ Gateway SG_ 605 SensorBlockageSt_RRS 1000;
BA_REL_ "GenSigTimeoutTime" BU_SG_REL_ AVM SG_ 605 SensorBlockageSt_RLS 1000;
BA_REL_ "GenSigTimeoutTime" BU_SG_REL_ AVP SG_ 605 SensorBlockageSt_RLS 1000;
BA_REL_ "GenSigTimeoutTime" BU_SG_REL_ ADV SG_ 605 SensorBlockageSt_RLS 1000;
BA_REL_ "GenSigTimeoutTime" BU_SG_REL_ Gateway SG_ 605 SensorBlockageSt_RLS 1000;
BA_REL_ "GenSigTimeoutTime" BU_SG_REL_ AVM SG_ 605 SensorBlockageSt_FRS 1000;
BA_REL_ "GenSigTimeoutTime" BU_SG_REL_ AVP SG_ 605 SensorBlockageSt_FRS 1000;
BA_REL_ "GenSigTimeoutTime" BU_SG_REL_ ADV SG_ 605 SensorBlockageSt_FRS 1000;
BA_REL_ "GenSigTimeoutTime" BU_SG_REL_ Gateway SG_ 605 SensorBlockageSt_FRS 1000;
BA_REL_ "GenSigTimeoutTime" BU_SG_REL_ AVM SG_ 605 SensorBlockageSt_FLS 1000;
BA_REL_ "GenSigTimeoutTime" BU_SG_REL_ AVP SG_ 605 SensorBlockageSt_FLS 1000;
BA_REL_ "GenSigTimeoutTime" BU_SG_REL_ ADV SG_ 605 SensorBlockageSt_FLS 1000;
BA_REL_ "GenSigTimeoutTime" BU_SG_REL_ Gateway SG_ 605 SensorBlockageSt_FLS 1000;
BA_REL_ "GenSigTimeoutTime" BU_SG_REL_ AVM SG_ 605 SensorBlockageSt_FL 1000;
BA_REL_ "GenSigTimeoutTime" BU_SG_REL_ AVP SG_ 605 SensorBlockageSt_FL 1000;
BA_REL_ "GenSigTimeoutTime" BU_SG_REL_ ADV SG_ 605 SensorBlockageSt_FL 1000;
BA_REL_ "GenSigTimeoutTime" BU_SG_REL_ Gateway SG_ 605 SensorBlockageSt_FL 1000;
BA_REL_ "GenSigTimeoutTime" BU_SG_REL_ AVM SG_ 605 SensorBlockageSt_FML 1000;
BA_REL_ "GenSigTimeoutTime" BU_SG_REL_ AVP SG_ 605 SensorBlockageSt_FML 1000;
BA_REL_ "GenSigTimeoutTime" BU_SG_REL_ ADV SG_ 605 SensorBlockageSt_FML 1000;
BA_REL_ "GenSigTimeoutTime" BU_SG_REL_ Gateway SG_ 605 SensorBlockageSt_FML 1000;
BA_REL_ "GenSigTimeoutTime" BU_SG_REL_ AVM SG_ 605 SensorBlockageSt_FMR 1000;
BA_REL_ "GenSigTimeoutTime" BU_SG_REL_ AVP SG_ 605 SensorBlockageSt_FMR 1000;
BA_REL_ "GenSigTimeoutTime" BU_SG_REL_ ADV SG_ 605 SensorBlockageSt_FMR 1000;
BA_REL_ "GenSigTimeoutTime" BU_SG_REL_ Gateway SG_ 605 SensorBlockageSt_FMR 1000;
BA_REL_ "GenSigTimeoutTime" BU_SG_REL_ AVM SG_ 605 SensorBlockageSt_FR 1000;
BA_REL_ "GenSigTimeoutTime" BU_SG_REL_ AVP SG_ 605 SensorBlockageSt_FR 1000;
BA_REL_ "GenSigTimeoutTime" BU_SG_REL_ ADV SG_ 605 SensorBlockageSt_FR 1000;
BA_REL_ "GenSigTimeoutTime" BU_SG_REL_ Gateway SG_ 605 SensorBlockageSt_FR 1000;
BA_REL_ "GenSigTimeoutTime" BU_SG_REL_ AVM SG_ 605 SensorBlockageSt_RL 1000;
BA_REL_ "GenSigTimeoutTime" BU_SG_REL_ AVP SG_ 605 SensorBlockageSt_RL 1000;
BA_REL_ "GenSigTimeoutTime" BU_SG_REL_ ADV SG_ 605 SensorBlockageSt_RL 1000;
BA_REL_ "GenSigTimeoutTime" BU_SG_REL_ Gateway SG_ 605 SensorBlockageSt_RL 1000;
BA_REL_ "GenSigTimeoutTime" BU_SG_REL_ AVM SG_ 605 SensorBlockageSt_RML 1000;
BA_REL_ "GenSigTimeoutTime" BU_SG_REL_ AVP SG_ 605 SensorBlockageSt_RML 1000;
BA_REL_ "GenSigTimeoutTime" BU_SG_REL_ ADV SG_ 605 SensorBlockageSt_RML 1000;
BA_REL_ "GenSigTimeoutTime" BU_SG_REL_ Gateway SG_ 605 SensorBlockageSt_RML 1000;
BA_REL_ "GenSigTimeoutTime" BU_SG_REL_ AVM SG_ 605 SensorBlockageSt_RMR 1000;
BA_REL_ "GenSigTimeoutTime" BU_SG_REL_ AVP SG_ 605 SensorBlockageSt_RMR 1000;
BA_REL_ "GenSigTimeoutTime" BU_SG_REL_ ADV SG_ 605 SensorBlockageSt_RMR 1000;
BA_REL_ "GenSigTimeoutTime" BU_SG_REL_ Gateway SG_ 605 SensorBlockageSt_RMR 1000;
BA_REL_ "GenSigTimeoutTime" BU_SG_REL_ AVM SG_ 605 SensorBlockageSt_RR 1000;
BA_REL_ "GenSigTimeoutTime" BU_SG_REL_ AVP SG_ 605 SensorBlockageSt_RR 1000;
BA_REL_ "GenSigTimeoutTime" BU_SG_REL_ ADV SG_ 605 SensorBlockageSt_RR 1000;
BA_REL_ "GenSigTimeoutTime" BU_SG_REL_ Gateway SG_ 605 SensorBlockageSt_RR 1000;
BA_REL_ "GenSigTimeoutTime" BU_SG_REL_ AVM SG_ 448 LiveCounter_PDC_3 500;
BA_REL_ "GenSigTimeoutTime" BU_SG_REL_ AVP SG_ 448 LiveCounter_PDC_3 500;
BA_REL_ "GenSigTimeoutTime" BU_SG_REL_ ADV SG_ 448 LiveCounter_PDC_3 500;
BA_REL_ "GenSigTimeoutTime" BU_SG_REL_ AVM SG_ 448 BCoordinateX_Left 500;
BA_REL_ "GenSigTimeoutTime" BU_SG_REL_ AVP SG_ 448 BCoordinateX_Left 500;
BA_REL_ "GenSigTimeoutTime" BU_SG_REL_ ADV SG_ 448 BCoordinateX_Left 500;
BA_REL_ "GenSigTimeoutTime" BU_SG_REL_ AVM SG_ 448 BCoordinateY_Left 500;
BA_REL_ "GenSigTimeoutTime" BU_SG_REL_ AVP SG_ 448 BCoordinateY_Left 500;
BA_REL_ "GenSigTimeoutTime" BU_SG_REL_ ADV SG_ 448 BCoordinateY_Left 500;
BA_REL_ "GenSigTimeoutTime" BU_SG_REL_ AVM SG_ 448 ACoordinateX_Left 500;
BA_REL_ "GenSigTimeoutTime" BU_SG_REL_ AVP SG_ 448 ACoordinateX_Left 500;
BA_REL_ "GenSigTimeoutTime" BU_SG_REL_ ADV SG_ 448 ACoordinateX_Left 500;
BA_REL_ "GenSigTimeoutTime" BU_SG_REL_ AVM SG_ 448 ACoordinateY_Left 500;
BA_REL_ "GenSigTimeoutTime" BU_SG_REL_ AVP SG_ 448 ACoordinateY_Left 500;
BA_REL_ "GenSigTimeoutTime" BU_SG_REL_ ADV SG_ 448 ACoordinateY_Left 500;
BA_REL_ "GenSigTimeoutTime" BU_SG_REL_ AVM SG_ 448 Checksum_PDC_3 500;
BA_REL_ "GenSigTimeoutTime" BU_SG_REL_ AVP SG_ 448 Checksum_PDC_3 500;
BA_REL_ "GenSigTimeoutTime" BU_SG_REL_ ADV SG_ 448 Checksum_PDC_3 500;
BA_REL_ "GenSigTimeoutTime" BU_SG_REL_ AVM SG_ 449 LiveCounter_PDC_4 500;
BA_REL_ "GenSigTimeoutTime" BU_SG_REL_ AVP SG_ 449 LiveCounter_PDC_4 500;
BA_REL_ "GenSigTimeoutTime" BU_SG_REL_ ADV SG_ 449 LiveCounter_PDC_4 500;
BA_REL_ "GenSigTimeoutTime" BU_SG_REL_ AVM SG_ 449 RearObjCoordinateX 500;
BA_REL_ "GenSigTimeoutTime" BU_SG_REL_ AVP SG_ 449 RearObjCoordinateX 500;
BA_REL_ "GenSigTimeoutTime" BU_SG_REL_ ADV SG_ 449 RearObjCoordinateX 500;
BA_REL_ "GenSigTimeoutTime" BU_SG_REL_ AVM SG_ 449 RearObjCoordinateY 500;
BA_REL_ "GenSigTimeoutTime" BU_SG_REL_ AVP SG_ 449 RearObjCoordinateY 500;
BA_REL_ "GenSigTimeoutTime" BU_SG_REL_ ADV SG_ 449 RearObjCoordinateY 500;
BA_REL_ "GenSigTimeoutTime" BU_SG_REL_ AVM SG_ 449 FrontObjCoordinateX 500;
BA_REL_ "GenSigTimeoutTime" BU_SG_REL_ AVP SG_ 449 FrontObjCoordinateX 500;
BA_REL_ "GenSigTimeoutTime" BU_SG_REL_ ADV SG_ 449 FrontObjCoordinateX 500;
BA_REL_ "GenSigTimeoutTime" BU_SG_REL_ AVM SG_ 449 FrontObjCoordinateY 500;
BA_REL_ "GenSigTimeoutTime" BU_SG_REL_ AVP SG_ 449 FrontObjCoordinateY 500;
BA_REL_ "GenSigTimeoutTime" BU_SG_REL_ ADV SG_ 449 FrontObjCoordinateY 500;
BA_REL_ "GenSigTimeoutTime" BU_SG_REL_ AVM SG_ 449 Checksum_PDC_4 500;
BA_REL_ "GenSigTimeoutTime" BU_SG_REL_ AVP SG_ 449 Checksum_PDC_4 500;
BA_REL_ "GenSigTimeoutTime" BU_SG_REL_ ADV SG_ 449 Checksum_PDC_4 500;
BA_REL_ "GenSigTimeoutTime" BU_SG_REL_ AVM SG_ 450 LiveCounter_PDC_5 500;
BA_REL_ "GenSigTimeoutTime" BU_SG_REL_ AVP SG_ 450 LiveCounter_PDC_5 500;
BA_REL_ "GenSigTimeoutTime" BU_SG_REL_ ADV SG_ 450 LiveCounter_PDC_5 500;
BA_REL_ "GenSigTimeoutTime" BU_SG_REL_ AVM SG_ 450 TxRxSt_FML 500;
BA_REL_ "GenSigTimeoutTime" BU_SG_REL_ AVP SG_ 450 TxRxSt_FML 500;
BA_REL_ "GenSigTimeoutTime" BU_SG_REL_ ADV SG_ 450 TxRxSt_FML 500;
BA_REL_ "GenSigTimeoutTime" BU_SG_REL_ AVM SG_ 450 TxRxSt_FL 500;
BA_REL_ "GenSigTimeoutTime" BU_SG_REL_ AVP SG_ 450 TxRxSt_FL 500;
BA_REL_ "GenSigTimeoutTime" BU_SG_REL_ ADV SG_ 450 TxRxSt_FL 500;
BA_REL_ "GenSigTimeoutTime" BU_SG_REL_ AVM SG_ 450 TimeStamp_FML_FL 500;
BA_REL_ "GenSigTimeoutTime" BU_SG_REL_ AVP SG_ 450 TimeStamp_FML_FL 500;
BA_REL_ "GenSigTimeoutTime" BU_SG_REL_ ADV SG_ 450 TimeStamp_FML_FL 500;
BA_REL_ "GenSigTimeoutTime" BU_SG_REL_ AVM SG_ 450 DistanceValue_FML 500;
BA_REL_ "GenSigTimeoutTime" BU_SG_REL_ AVP SG_ 450 DistanceValue_FML 500;
BA_REL_ "GenSigTimeoutTime" BU_SG_REL_ ADV SG_ 450 DistanceValue_FML 500;
BA_REL_ "GenSigTimeoutTime" BU_SG_REL_ AVM SG_ 450 DistanceValue_FL 500;
BA_REL_ "GenSigTimeoutTime" BU_SG_REL_ AVP SG_ 450 DistanceValue_FL 500;
BA_REL_ "GenSigTimeoutTime" BU_SG_REL_ ADV SG_ 450 DistanceValue_FL 500;
BA_REL_ "GenSigTimeoutTime" BU_SG_REL_ AVM SG_ 450 Checksum_PDC_5 500;
BA_REL_ "GenSigTimeoutTime" BU_SG_REL_ AVP SG_ 450 Checksum_PDC_5 500;
BA_REL_ "GenSigTimeoutTime" BU_SG_REL_ ADV SG_ 450 Checksum_PDC_5 500;
BA_REL_ "GenSigTimeoutTime" BU_SG_REL_ AVM SG_ 451 LiveCounter_PDC_6 500;
BA_REL_ "GenSigTimeoutTime" BU_SG_REL_ AVP SG_ 451 LiveCounter_PDC_6 500;
BA_REL_ "GenSigTimeoutTime" BU_SG_REL_ ADV SG_ 451 LiveCounter_PDC_6 500;
BA_REL_ "GenSigTimeoutTime" BU_SG_REL_ AVM SG_ 451 TxRxSt_FMR 500;
BA_REL_ "GenSigTimeoutTime" BU_SG_REL_ AVP SG_ 451 TxRxSt_FMR 500;
BA_REL_ "GenSigTimeoutTime" BU_SG_REL_ ADV SG_ 451 TxRxSt_FMR 500;
BA_REL_ "GenSigTimeoutTime" BU_SG_REL_ AVM SG_ 451 TxRxSt_FR 500;
BA_REL_ "GenSigTimeoutTime" BU_SG_REL_ AVP SG_ 451 TxRxSt_FR 500;
BA_REL_ "GenSigTimeoutTime" BU_SG_REL_ ADV SG_ 451 TxRxSt_FR 500;
BA_REL_ "GenSigTimeoutTime" BU_SG_REL_ AVM SG_ 451 TimeStamp_FMR_FR 500;
BA_REL_ "GenSigTimeoutTime" BU_SG_REL_ AVP SG_ 451 TimeStamp_FMR_FR 500;
BA_REL_ "GenSigTimeoutTime" BU_SG_REL_ ADV SG_ 451 TimeStamp_FMR_FR 500;
BA_REL_ "GenSigTimeoutTime" BU_SG_REL_ AVM SG_ 451 DistanceValue_FMR 500;
BA_REL_ "GenSigTimeoutTime" BU_SG_REL_ AVP SG_ 451 DistanceValue_FMR 500;
BA_REL_ "GenSigTimeoutTime" BU_SG_REL_ ADV SG_ 451 DistanceValue_FMR 500;
BA_REL_ "GenSigTimeoutTime" BU_SG_REL_ AVM SG_ 451 DistanceValue_FR 500;
BA_REL_ "GenSigTimeoutTime" BU_SG_REL_ AVP SG_ 451 DistanceValue_FR 500;
BA_REL_ "GenSigTimeoutTime" BU_SG_REL_ ADV SG_ 451 DistanceValue_FR 500;
BA_REL_ "GenSigTimeoutTime" BU_SG_REL_ AVM SG_ 451 Checksum_PDC_6 500;
BA_REL_ "GenSigTimeoutTime" BU_SG_REL_ AVP SG_ 451 Checksum_PDC_6 500;
BA_REL_ "GenSigTimeoutTime" BU_SG_REL_ ADV SG_ 451 Checksum_PDC_6 500;
BA_REL_ "GenSigTimeoutTime" BU_SG_REL_ AVM SG_ 452 LiveCounter_PDC_7 500;
BA_REL_ "GenSigTimeoutTime" BU_SG_REL_ AVP SG_ 452 LiveCounter_PDC_7 500;
BA_REL_ "GenSigTimeoutTime" BU_SG_REL_ ADV SG_ 452 LiveCounter_PDC_7 500;
BA_REL_ "GenSigTimeoutTime" BU_SG_REL_ AVM SG_ 452 TxRxSt_RML 500;
BA_REL_ "GenSigTimeoutTime" BU_SG_REL_ AVP SG_ 452 TxRxSt_RML 500;
BA_REL_ "GenSigTimeoutTime" BU_SG_REL_ ADV SG_ 452 TxRxSt_RML 500;
BA_REL_ "GenSigTimeoutTime" BU_SG_REL_ AVM SG_ 452 TxRxSt_RL 500;
BA_REL_ "GenSigTimeoutTime" BU_SG_REL_ AVP SG_ 452 TxRxSt_RL 500;
BA_REL_ "GenSigTimeoutTime" BU_SG_REL_ ADV SG_ 452 TxRxSt_RL 500;
BA_REL_ "GenSigTimeoutTime" BU_SG_REL_ AVM SG_ 452 TimeStamp_RML_RL 500;
BA_REL_ "GenSigTimeoutTime" BU_SG_REL_ AVP SG_ 452 TimeStamp_RML_RL 500;
BA_REL_ "GenSigTimeoutTime" BU_SG_REL_ ADV SG_ 452 TimeStamp_RML_RL 500;
BA_REL_ "GenSigTimeoutTime" BU_SG_REL_ AVM SG_ 452 DistanceValue_RML 500;
BA_REL_ "GenSigTimeoutTime" BU_SG_REL_ AVP SG_ 452 DistanceValue_RML 500;
BA_REL_ "GenSigTimeoutTime" BU_SG_REL_ ADV SG_ 452 DistanceValue_RML 500;
BA_REL_ "GenSigTimeoutTime" BU_SG_REL_ AVM SG_ 452 DistanceValue_RL 500;
BA_REL_ "GenSigTimeoutTime" BU_SG_REL_ AVP SG_ 452 DistanceValue_RL 500;
BA_REL_ "GenSigTimeoutTime" BU_SG_REL_ ADV SG_ 452 DistanceValue_RL 500;
BA_REL_ "GenSigTimeoutTime" BU_SG_REL_ AVM SG_ 452 Checksum_PDC_7 500;
BA_REL_ "GenSigTimeoutTime" BU_SG_REL_ AVP SG_ 452 Checksum_PDC_7 500;
BA_REL_ "GenSigTimeoutTime" BU_SG_REL_ ADV SG_ 452 Checksum_PDC_7 500;
BA_REL_ "GenSigTimeoutTime" BU_SG_REL_ AVM SG_ 453 LiveCounter_PDC_8 500;
BA_REL_ "GenSigTimeoutTime" BU_SG_REL_ AVP SG_ 453 LiveCounter_PDC_8 500;
BA_REL_ "GenSigTimeoutTime" BU_SG_REL_ ADV SG_ 453 LiveCounter_PDC_8 500;
BA_REL_ "GenSigTimeoutTime" BU_SG_REL_ AVM SG_ 453 TxRxSt_RMR 500;
BA_REL_ "GenSigTimeoutTime" BU_SG_REL_ AVP SG_ 453 TxRxSt_RMR 500;
BA_REL_ "GenSigTimeoutTime" BU_SG_REL_ ADV SG_ 453 TxRxSt_RMR 500;
BA_REL_ "GenSigTimeoutTime" BU_SG_REL_ AVM SG_ 453 TxRxSt_RR 500;
BA_REL_ "GenSigTimeoutTime" BU_SG_REL_ AVP SG_ 453 TxRxSt_RR 500;
BA_REL_ "GenSigTimeoutTime" BU_SG_REL_ ADV SG_ 453 TxRxSt_RR 500;
BA_REL_ "GenSigTimeoutTime" BU_SG_REL_ AVM SG_ 453 TimeStamp_RMR_RR 500;
BA_REL_ "GenSigTimeoutTime" BU_SG_REL_ AVP SG_ 453 TimeStamp_RMR_RR 500;
BA_REL_ "GenSigTimeoutTime" BU_SG_REL_ ADV SG_ 453 TimeStamp_RMR_RR 500;
BA_REL_ "GenSigTimeoutTime" BU_SG_REL_ AVM SG_ 453 DistanceValue_RMR 500;
BA_REL_ "GenSigTimeoutTime" BU_SG_REL_ AVP SG_ 453 DistanceValue_RMR 500;
BA_REL_ "GenSigTimeoutTime" BU_SG_REL_ ADV SG_ 453 DistanceValue_RMR 500;
BA_REL_ "GenSigTimeoutTime" BU_SG_REL_ AVM SG_ 453 DistanceValue_RR 500;
BA_REL_ "GenSigTimeoutTime" BU_SG_REL_ AVP SG_ 453 DistanceValue_RR 500;
BA_REL_ "GenSigTimeoutTime" BU_SG_REL_ ADV SG_ 453 DistanceValue_RR 500;
BA_REL_ "GenSigTimeoutTime" BU_SG_REL_ AVM SG_ 453 Checksum_PDC_8 500;
BA_REL_ "GenSigTimeoutTime" BU_SG_REL_ AVP SG_ 453 Checksum_PDC_8 500;
BA_REL_ "GenSigTimeoutTime" BU_SG_REL_ ADV SG_ 453 Checksum_PDC_8 500;
BA_REL_ "GenSigTimeoutTime" BU_SG_REL_ AVM SG_ 454 LiveCounter_PDC_9 500;
BA_REL_ "GenSigTimeoutTime" BU_SG_REL_ AVP SG_ 454 LiveCounter_PDC_9 500;
BA_REL_ "GenSigTimeoutTime" BU_SG_REL_ ADV SG_ 454 LiveCounter_PDC_9 500;
BA_REL_ "GenSigTimeoutTime" BU_SG_REL_ AVM SG_ 454 ParkingSlotDepth_Left 500;
BA_REL_ "GenSigTimeoutTime" BU_SG_REL_ AVP SG_ 454 ParkingSlotDepth_Left 500;
BA_REL_ "GenSigTimeoutTime" BU_SG_REL_ AVM SG_ 454 TimeStamp_FLS_FRS 500;
BA_REL_ "GenSigTimeoutTime" BU_SG_REL_ AVP SG_ 454 TimeStamp_FLS_FRS 500;
BA_REL_ "GenSigTimeoutTime" BU_SG_REL_ ADV SG_ 454 TimeStamp_FLS_FRS 500;
BA_REL_ "GenSigTimeoutTime" BU_SG_REL_ AVM SG_ 454 DistanceValue_FRS 500;
BA_REL_ "GenSigTimeoutTime" BU_SG_REL_ AVP SG_ 454 DistanceValue_FRS 500;
BA_REL_ "GenSigTimeoutTime" BU_SG_REL_ ADV SG_ 454 DistanceValue_FRS 500;
BA_REL_ "GenSigTimeoutTime" BU_SG_REL_ AVM SG_ 454 DistanceValue_FLS 500;
BA_REL_ "GenSigTimeoutTime" BU_SG_REL_ AVP SG_ 454 DistanceValue_FLS 500;
BA_REL_ "GenSigTimeoutTime" BU_SG_REL_ ADV SG_ 454 DistanceValue_FLS 500;
BA_REL_ "GenSigTimeoutTime" BU_SG_REL_ AVM SG_ 454 Checksum_PDC_9 500;
BA_REL_ "GenSigTimeoutTime" BU_SG_REL_ AVP SG_ 454 Checksum_PDC_9 500;
BA_REL_ "GenSigTimeoutTime" BU_SG_REL_ ADV SG_ 454 Checksum_PDC_9 500;
BA_REL_ "GenSigTimeoutTime" BU_SG_REL_ CDS1 SG_ 192 Checksum_ABS_1 100;
BA_REL_ "GenSigTimeoutTime" BU_SG_REL_ CDS2 SG_ 192 Checksum_ABS_1 100;
BA_REL_ "GenSigTimeoutTime" BU_SG_REL_ ADV SG_ 192 Checksum_ABS_1 100;
BA_REL_ "GenSigTimeoutTime" BU_SG_REL_ IRC SG_ 192 Checksum_ABS_1 100;
BA_REL_ "GenSigTimeoutTime" BU_SG_REL_ AVP SG_ 192 Checksum_ABS_1 100;
BA_REL_ "GenSigTimeoutTime" BU_SG_REL_ AVM SG_ 192 Checksum_ABS_1 100;
BA_REL_ "GenSigTimeoutTime" BU_SG_REL_ PDC SG_ 192 Checksum_ABS_1 100;
BA_REL_ "GenSigTimeoutTime" BU_SG_REL_ ADB1 SG_ 192 Checksum_ABS_1 100;
BA_REL_ "GenSigTimeoutTime" BU_SG_REL_ ADB2 SG_ 192 Checksum_ABS_1 100;
BA_REL_ "GenSigTimeoutTime" BU_SG_REL_ HDMAP SG_ 192 Checksum_ABS_1 100;
BA_REL_ "GenSigTimeoutTime" BU_SG_REL_ DSM SG_ 192 Checksum_ABS_1 100;
BA_REL_ "GenSigTimeoutTime" BU_SG_REL_ Fradar SG_ 192 Checksum_ABS_1 100;
BA_REL_ "GenSigTimeoutTime" BU_SG_REL_ LCDA1 SG_ 192 Checksum_ABS_1 100;
BA_REL_ "GenSigTimeoutTime" BU_SG_REL_ LCDA2 SG_ 192 Checksum_ABS_1 100;
BA_REL_ "GenSigTimeoutTime" BU_SG_REL_ CDS1 SG_ 192 WheelSpeed_FL 100;
BA_REL_ "GenSigTimeoutTime" BU_SG_REL_ CDS2 SG_ 192 WheelSpeed_FL 100;
BA_REL_ "GenSigTimeoutTime" BU_SG_REL_ ADV SG_ 192 WheelSpeed_FL 100;
BA_REL_ "GenSigTimeoutTime" BU_SG_REL_ AVP SG_ 192 WheelSpeed_FL 100;
BA_REL_ "GenSigTimeoutTime" BU_SG_REL_ AVM SG_ 192 WheelSpeed_FL 100;
BA_REL_ "GenSigTimeoutTime" BU_SG_REL_ PDC SG_ 192 WheelSpeed_FL 100;
BA_REL_ "GenSigTimeoutTime" BU_SG_REL_ HDMAP SG_ 192 WheelSpeed_FL 100;
BA_REL_ "GenSigTimeoutTime" BU_SG_REL_ DSM SG_ 192 WheelSpeed_FL 100;
BA_REL_ "GenSigTimeoutTime" BU_SG_REL_ CDS1 SG_ 192 WheelSpeed_FR 100;
BA_REL_ "GenSigTimeoutTime" BU_SG_REL_ CDS2 SG_ 192 WheelSpeed_FR 100;
BA_REL_ "GenSigTimeoutTime" BU_SG_REL_ ADV SG_ 192 WheelSpeed_FR 100;
BA_REL_ "GenSigTimeoutTime" BU_SG_REL_ AVP SG_ 192 WheelSpeed_FR 100;
BA_REL_ "GenSigTimeoutTime" BU_SG_REL_ AVM SG_ 192 WheelSpeed_FR 100;
BA_REL_ "GenSigTimeoutTime" BU_SG_REL_ PDC SG_ 192 WheelSpeed_FR 100;
BA_REL_ "GenSigTimeoutTime" BU_SG_REL_ HDMAP SG_ 192 WheelSpeed_FR 100;
BA_REL_ "GenSigTimeoutTime" BU_SG_REL_ DSM SG_ 192 WheelSpeed_FR 100;
BA_REL_ "GenSigTimeoutTime" BU_SG_REL_ CDS1 SG_ 192 AvailableSt_EPBSwitch 100;
BA_REL_ "GenSigTimeoutTime" BU_SG_REL_ CDS2 SG_ 192 AvailableSt_EPBSwitch 100;
BA_REL_ "GenSigTimeoutTime" BU_SG_REL_ ADV SG_ 192 AvailableSt_EPBSwitch 100;
BA_REL_ "GenSigTimeoutTime" BU_SG_REL_ CDS1 SG_ 192 VehiclSpeed 100;
BA_REL_ "GenSigTimeoutTime" BU_SG_REL_ CDS2 SG_ 192 VehiclSpeed 100;
BA_REL_ "GenSigTimeoutTime" BU_SG_REL_ ADV SG_ 192 VehiclSpeed 100;
BA_REL_ "GenSigTimeoutTime" BU_SG_REL_ IRC SG_ 192 VehiclSpeed 100;
BA_REL_ "GenSigTimeoutTime" BU_SG_REL_ AVP SG_ 192 VehiclSpeed 100;
BA_REL_ "GenSigTimeoutTime" BU_SG_REL_ AVM SG_ 192 VehiclSpeed 100;
BA_REL_ "GenSigTimeoutTime" BU_SG_REL_ PDC SG_ 192 VehiclSpeed 100;
BA_REL_ "GenSigTimeoutTime" BU_SG_REL_ ADB1 SG_ 192 VehiclSpeed 100;
BA_REL_ "GenSigTimeoutTime" BU_SG_REL_ ADB2 SG_ 192 VehiclSpeed 100;
BA_REL_ "GenSigTimeoutTime" BU_SG_REL_ HDMAP SG_ 192 VehiclSpeed 100;
BA_REL_ "GenSigTimeoutTime" BU_SG_REL_ DSM SG_ 192 VehiclSpeed 100;
BA_REL_ "GenSigTimeoutTime" BU_SG_REL_ Fradar SG_ 192 VehiclSpeed 100;
BA_REL_ "GenSigTimeoutTime" BU_SG_REL_ LCDA1 SG_ 192 VehiclSpeed 100;
BA_REL_ "GenSigTimeoutTime" BU_SG_REL_ LCDA2 SG_ 192 VehiclSpeed 100;
BA_REL_ "GenSigTimeoutTime" BU_SG_REL_ CDS1 SG_ 192 VehiclSpeed_Q 100;
BA_REL_ "GenSigTimeoutTime" BU_SG_REL_ CDS2 SG_ 192 VehiclSpeed_Q 100;
BA_REL_ "GenSigTimeoutTime" BU_SG_REL_ ADV SG_ 192 VehiclSpeed_Q 100;
BA_REL_ "GenSigTimeoutTime" BU_SG_REL_ IRC SG_ 192 VehiclSpeed_Q 100;
BA_REL_ "GenSigTimeoutTime" BU_SG_REL_ HDMAP SG_ 192 VehiclSpeed_Q 100;
BA_REL_ "GenSigTimeoutTime" BU_SG_REL_ DSM SG_ 192 VehiclSpeed_Q 100;
BA_REL_ "GenSigTimeoutTime" BU_SG_REL_ CDS1 SG_ 192 DrivingDirection 100;
BA_REL_ "GenSigTimeoutTime" BU_SG_REL_ CDS2 SG_ 192 DrivingDirection 100;
BA_REL_ "GenSigTimeoutTime" BU_SG_REL_ ADV SG_ 192 DrivingDirection 100;
BA_REL_ "GenSigTimeoutTime" BU_SG_REL_ AVP SG_ 192 DrivingDirection 100;
BA_REL_ "GenSigTimeoutTime" BU_SG_REL_ AVM SG_ 192 DrivingDirection 100;
BA_REL_ "GenSigTimeoutTime" BU_SG_REL_ PDC SG_ 192 DrivingDirection 100;
BA_REL_ "GenSigTimeoutTime" BU_SG_REL_ Fradar SG_ 192 DrivingDirection 100;
BA_REL_ "GenSigTimeoutTime" BU_SG_REL_ LCDA1 SG_ 192 DrivingDirection 100;
BA_REL_ "GenSigTimeoutTime" BU_SG_REL_ LCDA2 SG_ 192 DrivingDirection 100;
BA_REL_ "GenSigTimeoutTime" BU_SG_REL_ CDS1 SG_ 192 EPBSwitch 100;
BA_REL_ "GenSigTimeoutTime" BU_SG_REL_ CDS2 SG_ 192 EPBSwitch 100;
BA_REL_ "GenSigTimeoutTime" BU_SG_REL_ ADV SG_ 192 EPBSwitch 100;
BA_REL_ "GenSigTimeoutTime" BU_SG_REL_ CDS1 SG_ 192 LiveCounter_ABS_1 100;
BA_REL_ "GenSigTimeoutTime" BU_SG_REL_ CDS2 SG_ 192 LiveCounter_ABS_1 100;
BA_REL_ "GenSigTimeoutTime" BU_SG_REL_ ADV SG_ 192 LiveCounter_ABS_1 100;
BA_REL_ "GenSigTimeoutTime" BU_SG_REL_ IRC SG_ 192 LiveCounter_ABS_1 100;
BA_REL_ "GenSigTimeoutTime" BU_SG_REL_ AVP SG_ 192 LiveCounter_ABS_1 100;
BA_REL_ "GenSigTimeoutTime" BU_SG_REL_ AVM SG_ 192 LiveCounter_ABS_1 100;
BA_REL_ "GenSigTimeoutTime" BU_SG_REL_ PDC SG_ 192 LiveCounter_ABS_1 100;
BA_REL_ "GenSigTimeoutTime" BU_SG_REL_ ADB1 SG_ 192 LiveCounter_ABS_1 100;
BA_REL_ "GenSigTimeoutTime" BU_SG_REL_ ADB2 SG_ 192 LiveCounter_ABS_1 100;
BA_REL_ "GenSigTimeoutTime" BU_SG_REL_ HDMAP SG_ 192 LiveCounter_ABS_1 100;
BA_REL_ "GenSigTimeoutTime" BU_SG_REL_ DSM SG_ 192 LiveCounter_ABS_1 100;
BA_REL_ "GenSigTimeoutTime" BU_SG_REL_ Fradar SG_ 192 LiveCounter_ABS_1 100;
BA_REL_ "GenSigTimeoutTime" BU_SG_REL_ LCDA1 SG_ 192 LiveCounter_ABS_1 100;
BA_REL_ "GenSigTimeoutTime" BU_SG_REL_ LCDA2 SG_ 192 LiveCounter_ABS_1 100;
BA_REL_ "GenSigTimeoutTime" BU_SG_REL_ CDS1 SG_ 194 Checksum_ABS_2 100;
BA_REL_ "GenSigTimeoutTime" BU_SG_REL_ CDS2 SG_ 194 Checksum_ABS_2 100;
BA_REL_ "GenSigTimeoutTime" BU_SG_REL_ ADV SG_ 194 Checksum_ABS_2 100;
BA_REL_ "GenSigTimeoutTime" BU_SG_REL_ AVP SG_ 194 Checksum_ABS_2 100;
BA_REL_ "GenSigTimeoutTime" BU_SG_REL_ AVM SG_ 194 Checksum_ABS_2 100;
BA_REL_ "GenSigTimeoutTime" BU_SG_REL_ PDC SG_ 194 Checksum_ABS_2 100;
BA_REL_ "GenSigTimeoutTime" BU_SG_REL_ HDMAP SG_ 194 Checksum_ABS_2 100;
BA_REL_ "GenSigTimeoutTime" BU_SG_REL_ CDS1 SG_ 194 WheelSpeed_RL 100;
BA_REL_ "GenSigTimeoutTime" BU_SG_REL_ CDS2 SG_ 194 WheelSpeed_RL 100;
BA_REL_ "GenSigTimeoutTime" BU_SG_REL_ ADV SG_ 194 WheelSpeed_RL 100;
BA_REL_ "GenSigTimeoutTime" BU_SG_REL_ AVP SG_ 194 WheelSpeed_RL 100;
BA_REL_ "GenSigTimeoutTime" BU_SG_REL_ AVM SG_ 194 WheelSpeed_RL 100;
BA_REL_ "GenSigTimeoutTime" BU_SG_REL_ PDC SG_ 194 WheelSpeed_RL 100;
BA_REL_ "GenSigTimeoutTime" BU_SG_REL_ HDMAP SG_ 194 WheelSpeed_RL 100;
BA_REL_ "GenSigTimeoutTime" BU_SG_REL_ CDS1 SG_ 194 WheelSpeed_RR 100;
BA_REL_ "GenSigTimeoutTime" BU_SG_REL_ CDS2 SG_ 194 WheelSpeed_RR 100;
BA_REL_ "GenSigTimeoutTime" BU_SG_REL_ ADV SG_ 194 WheelSpeed_RR 100;
BA_REL_ "GenSigTimeoutTime" BU_SG_REL_ AVP SG_ 194 WheelSpeed_RR 100;
BA_REL_ "GenSigTimeoutTime" BU_SG_REL_ AVM SG_ 194 WheelSpeed_RR 100;
BA_REL_ "GenSigTimeoutTime" BU_SG_REL_ PDC SG_ 194 WheelSpeed_RR 100;
BA_REL_ "GenSigTimeoutTime" BU_SG_REL_ HDMAP SG_ 194 WheelSpeed_RR 100;
BA_REL_ "GenSigTimeoutTime" BU_SG_REL_ CDS1 SG_ 194 MasterCylinderPressure 100;
BA_REL_ "GenSigTimeoutTime" BU_SG_REL_ CDS2 SG_ 194 MasterCylinderPressure 100;
BA_REL_ "GenSigTimeoutTime" BU_SG_REL_ ADV SG_ 194 MasterCylinderPressure 100;
BA_REL_ "GenSigTimeoutTime" BU_SG_REL_ HDMAP SG_ 194 MasterCylinderPressure 100;
BA_REL_ "GenSigTimeoutTime" BU_SG_REL_ CDS1 SG_ 194 LiveCounter_ABS_2 100;
BA_REL_ "GenSigTimeoutTime" BU_SG_REL_ CDS2 SG_ 194 LiveCounter_ABS_2 100;
BA_REL_ "GenSigTimeoutTime" BU_SG_REL_ ADV SG_ 194 LiveCounter_ABS_2 100;
BA_REL_ "GenSigTimeoutTime" BU_SG_REL_ AVP SG_ 194 LiveCounter_ABS_2 100;
BA_REL_ "GenSigTimeoutTime" BU_SG_REL_ AVM SG_ 194 LiveCounter_ABS_2 100;
BA_REL_ "GenSigTimeoutTime" BU_SG_REL_ PDC SG_ 194 LiveCounter_ABS_2 100;
BA_REL_ "GenSigTimeoutTime" BU_SG_REL_ HDMAP SG_ 194 LiveCounter_ABS_2 100;
BA_REL_ "GenSigTimeoutTime" BU_SG_REL_ CDS1 SG_ 304 Checksum_ABS_3 200;
BA_REL_ "GenSigTimeoutTime" BU_SG_REL_ CDS2 SG_ 304 Checksum_ABS_3 200;
BA_REL_ "GenSigTimeoutTime" BU_SG_REL_ ADV SG_ 304 Checksum_ABS_3 200;
BA_REL_ "GenSigTimeoutTime" BU_SG_REL_ AVP SG_ 304 Checksum_ABS_3 200;
BA_REL_ "GenSigTimeoutTime" BU_SG_REL_ AVM SG_ 304 Checksum_ABS_3 200;
BA_REL_ "GenSigTimeoutTime" BU_SG_REL_ PDC SG_ 304 Checksum_ABS_3 200;
BA_REL_ "GenSigTimeoutTime" BU_SG_REL_ HDMAP SG_ 304 Checksum_ABS_3 200;
BA_REL_ "GenSigTimeoutTime" BU_SG_REL_ CDS1 SG_ 304 WheelPulse_FL 200;
BA_REL_ "GenSigTimeoutTime" BU_SG_REL_ CDS2 SG_ 304 WheelPulse_FL 200;
BA_REL_ "GenSigTimeoutTime" BU_SG_REL_ ADV SG_ 304 WheelPulse_FL 200;
BA_REL_ "GenSigTimeoutTime" BU_SG_REL_ AVP SG_ 304 WheelPulse_FL 200;
BA_REL_ "GenSigTimeoutTime" BU_SG_REL_ AVM SG_ 304 WheelPulse_FL 200;
BA_REL_ "GenSigTimeoutTime" BU_SG_REL_ PDC SG_ 304 WheelPulse_FL 200;
BA_REL_ "GenSigTimeoutTime" BU_SG_REL_ HDMAP SG_ 304 WheelPulse_FL 200;
BA_REL_ "GenSigTimeoutTime" BU_SG_REL_ CDS1 SG_ 304 WheelPulse_FR 200;
BA_REL_ "GenSigTimeoutTime" BU_SG_REL_ CDS2 SG_ 304 WheelPulse_FR 200;
BA_REL_ "GenSigTimeoutTime" BU_SG_REL_ ADV SG_ 304 WheelPulse_FR 200;
BA_REL_ "GenSigTimeoutTime" BU_SG_REL_ AVP SG_ 304 WheelPulse_FR 200;
BA_REL_ "GenSigTimeoutTime" BU_SG_REL_ AVM SG_ 304 WheelPulse_FR 200;
BA_REL_ "GenSigTimeoutTime" BU_SG_REL_ PDC SG_ 304 WheelPulse_FR 200;
BA_REL_ "GenSigTimeoutTime" BU_SG_REL_ HDMAP SG_ 304 WheelPulse_FR 200;
BA_REL_ "GenSigTimeoutTime" BU_SG_REL_ CDS1 SG_ 304 WheelPulse_RL 200;
BA_REL_ "GenSigTimeoutTime" BU_SG_REL_ CDS2 SG_ 304 WheelPulse_RL 200;
BA_REL_ "GenSigTimeoutTime" BU_SG_REL_ ADV SG_ 304 WheelPulse_RL 200;
BA_REL_ "GenSigTimeoutTime" BU_SG_REL_ AVP SG_ 304 WheelPulse_RL 200;
BA_REL_ "GenSigTimeoutTime" BU_SG_REL_ AVM SG_ 304 WheelPulse_RL 200;
BA_REL_ "GenSigTimeoutTime" BU_SG_REL_ PDC SG_ 304 WheelPulse_RL 200;
BA_REL_ "GenSigTimeoutTime" BU_SG_REL_ HDMAP SG_ 304 WheelPulse_RL 200;
BA_REL_ "GenSigTimeoutTime" BU_SG_REL_ CDS1 SG_ 304 WheelPulse_RR 200;
BA_REL_ "GenSigTimeoutTime" BU_SG_REL_ CDS2 SG_ 304 WheelPulse_RR 200;
BA_REL_ "GenSigTimeoutTime" BU_SG_REL_ ADV SG_ 304 WheelPulse_RR 200;
BA_REL_ "GenSigTimeoutTime" BU_SG_REL_ AVP SG_ 304 WheelPulse_RR 200;
BA_REL_ "GenSigTimeoutTime" BU_SG_REL_ AVM SG_ 304 WheelPulse_RR 200;
BA_REL_ "GenSigTimeoutTime" BU_SG_REL_ PDC SG_ 304 WheelPulse_RR 200;
BA_REL_ "GenSigTimeoutTime" BU_SG_REL_ HDMAP SG_ 304 WheelPulse_RR 200;
BA_REL_ "GenSigTimeoutTime" BU_SG_REL_ PDC SG_ 304 WheelSpeedDirection_FL 200;
BA_REL_ "GenSigTimeoutTime" BU_SG_REL_ PDC SG_ 304 WheelSpeedDirection_FR 200;
BA_REL_ "GenSigTimeoutTime" BU_SG_REL_ PDC SG_ 304 WheelSpeedDirection_RL 200;
BA_REL_ "GenSigTimeoutTime" BU_SG_REL_ PDC SG_ 304 WheelSpeedDirection_RR 200;
BA_REL_ "GenSigTimeoutTime" BU_SG_REL_ CDS1 SG_ 304 LiveCounter_ABS_3 200;
BA_REL_ "GenSigTimeoutTime" BU_SG_REL_ CDS2 SG_ 304 LiveCounter_ABS_3 200;
BA_REL_ "GenSigTimeoutTime" BU_SG_REL_ ADV SG_ 304 LiveCounter_ABS_3 200;
BA_REL_ "GenSigTimeoutTime" BU_SG_REL_ AVP SG_ 304 LiveCounter_ABS_3 200;
BA_REL_ "GenSigTimeoutTime" BU_SG_REL_ AVM SG_ 304 LiveCounter_ABS_3 200;
BA_REL_ "GenSigTimeoutTime" BU_SG_REL_ PDC SG_ 304 LiveCounter_ABS_3 200;
BA_REL_ "GenSigTimeoutTime" BU_SG_REL_ HDMAP SG_ 304 LiveCounter_ABS_3 200;
BA_REL_ "GenSigTimeoutTime" BU_SG_REL_ CDS1 SG_ 306 Checksum_ESC_2_1 200;
BA_REL_ "GenSigTimeoutTime" BU_SG_REL_ CDS2 SG_ 306 Checksum_ESC_2_1 200;
BA_REL_ "GenSigTimeoutTime" BU_SG_REL_ ADV SG_ 306 Checksum_ESC_2_1 200;
BA_REL_ "GenSigTimeoutTime" BU_SG_REL_ AVP SG_ 306 Checksum_ESC_2_1 200;
BA_REL_ "GenSigTimeoutTime" BU_SG_REL_ AVM SG_ 306 Checksum_ESC_2_1 200;
BA_REL_ "GenSigTimeoutTime" BU_SG_REL_ PDC SG_ 306 Checksum_ESC_2_1 200;
BA_REL_ "GenSigTimeoutTime" BU_SG_REL_ CDS1 SG_ 306 WorkingSt_ESC 200;
BA_REL_ "GenSigTimeoutTime" BU_SG_REL_ CDS2 SG_ 306 WorkingSt_ESC 200;
BA_REL_ "GenSigTimeoutTime" BU_SG_REL_ CDS1 SG_ 306 ErrorSt_ESC 200;
BA_REL_ "GenSigTimeoutTime" BU_SG_REL_ CDS2 SG_ 306 ErrorSt_ESC 200;
BA_REL_ "GenSigTimeoutTime" BU_SG_REL_ ADV SG_ 306 ErrorSt_ESC 200;
BA_REL_ "GenSigTimeoutTime" BU_SG_REL_ CDS1 SG_ 306 Intervention_ESC 200;
BA_REL_ "GenSigTimeoutTime" BU_SG_REL_ CDS2 SG_ 306 Intervention_ESC 200;
BA_REL_ "GenSigTimeoutTime" BU_SG_REL_ ADV SG_ 306 Intervention_ESC 200;
BA_REL_ "GenSigTimeoutTime" BU_SG_REL_ CDS1 SG_ 306 ErrorSt_ABS 200;
BA_REL_ "GenSigTimeoutTime" BU_SG_REL_ CDS2 SG_ 306 ErrorSt_ABS 200;
BA_REL_ "GenSigTimeoutTime" BU_SG_REL_ CDS1 SG_ 306 Intervention_ABS 200;
BA_REL_ "GenSigTimeoutTime" BU_SG_REL_ CDS2 SG_ 306 Intervention_ABS 200;
BA_REL_ "GenSigTimeoutTime" BU_SG_REL_ ADV SG_ 306 Intervention_ABS 200;
BA_REL_ "GenSigTimeoutTime" BU_SG_REL_ CDS1 SG_ 306 Intervention_TCS 200;
BA_REL_ "GenSigTimeoutTime" BU_SG_REL_ CDS2 SG_ 306 Intervention_TCS 200;
BA_REL_ "GenSigTimeoutTime" BU_SG_REL_ ADV SG_ 306 Intervention_TCS 200;
BA_REL_ "GenSigTimeoutTime" BU_SG_REL_ CDS1 SG_ 306 ErrorSt_EBD 200;
BA_REL_ "GenSigTimeoutTime" BU_SG_REL_ ADV SG_ 306 ErrorSt_EBD 200;
BA_REL_ "GenSigTimeoutTime" BU_SG_REL_ CDS1 SG_ 306 AvailableSt_CDP 200;
BA_REL_ "GenSigTimeoutTime" BU_SG_REL_ CDS1 SG_ 306 Intervention_CDP_RWU 200;
BA_REL_ "GenSigTimeoutTime" BU_SG_REL_ CDS1 SG_ 306 ErrotSt_EPB 200;
BA_REL_ "GenSigTimeoutTime" BU_SG_REL_ CDS2 SG_ 306 ErrotSt_EPB 200;
BA_REL_ "GenSigTimeoutTime" BU_SG_REL_ ADV SG_ 306 ErrotSt_EPB 200;
BA_REL_ "GenSigTimeoutTime" BU_SG_REL_ AVP SG_ 306 ErrotSt_EPB 200;
BA_REL_ "GenSigTimeoutTime" BU_SG_REL_ AVM SG_ 306 ErrotSt_EPB 200;
BA_REL_ "GenSigTimeoutTime" BU_SG_REL_ CDS1 SG_ 306 AvailableSt_HDC 200;
BA_REL_ "GenSigTimeoutTime" BU_SG_REL_ CDS2 SG_ 306 AvailableSt_HDC 200;
BA_REL_ "GenSigTimeoutTime" BU_SG_REL_ CDS1 SG_ 306 WorkingSt_HDC 200;
BA_REL_ "GenSigTimeoutTime" BU_SG_REL_ CDS2 SG_ 306 WorkingSt_HDC 200;
BA_REL_ "GenSigTimeoutTime" BU_SG_REL_ CDS1 SG_ 306 AvailableSt_CDDS 200;
BA_REL_ "GenSigTimeoutTime" BU_SG_REL_ CDS2 SG_ 306 AvailableSt_CDDS 200;
BA_REL_ "GenSigTimeoutTime" BU_SG_REL_ CDS1 SG_ 306 Intervention_CDDS 200;
BA_REL_ "GenSigTimeoutTime" BU_SG_REL_ CDS2 SG_ 306 Intervention_CDDS 200;
BA_REL_ "GenSigTimeoutTime" BU_SG_REL_ CDS1 SG_ 306 AvailableSt_AEB 200;
BA_REL_ "GenSigTimeoutTime" BU_SG_REL_ CDS2 SG_ 306 AvailableSt_AEB 200;
BA_REL_ "GenSigTimeoutTime" BU_SG_REL_ CDS1 SG_ 306 Intervention_AEB 200;
BA_REL_ "GenSigTimeoutTime" BU_SG_REL_ CDS2 SG_ 306 Intervention_AEB 200;
BA_REL_ "GenSigTimeoutTime" BU_SG_REL_ CDS1 SG_ 306 AvailableSt_ABP 200;
BA_REL_ "GenSigTimeoutTime" BU_SG_REL_ CDS2 SG_ 306 AvailableSt_ABP 200;
BA_REL_ "GenSigTimeoutTime" BU_SG_REL_ CDS1 SG_ 306 Intervention_ABP 200;
BA_REL_ "GenSigTimeoutTime" BU_SG_REL_ CDS2 SG_ 306 Intervention_ABP 200;
BA_REL_ "GenSigTimeoutTime" BU_SG_REL_ CDS1 SG_ 306 AvailableSt_AWB 200;
BA_REL_ "GenSigTimeoutTime" BU_SG_REL_ CDS2 SG_ 306 AvailableSt_AWB 200;
BA_REL_ "GenSigTimeoutTime" BU_SG_REL_ CDS1 SG_ 306 Intervention_AWB 200;
BA_REL_ "GenSigTimeoutTime" BU_SG_REL_ CDS2 SG_ 306 Intervention_AWB 200;
BA_REL_ "GenSigTimeoutTime" BU_SG_REL_ CDS1 SG_ 306 VehicleStandstillSt 200;
BA_REL_ "GenSigTimeoutTime" BU_SG_REL_ CDS2 SG_ 306 VehicleStandstillSt 200;
BA_REL_ "GenSigTimeoutTime" BU_SG_REL_ ADV SG_ 306 VehicleStandstillSt 200;
BA_REL_ "GenSigTimeoutTime" BU_SG_REL_ CDS1 SG_ 306 WorkingSt_EPB 200;
BA_REL_ "GenSigTimeoutTime" BU_SG_REL_ CDS2 SG_ 306 WorkingSt_EPB 200;
BA_REL_ "GenSigTimeoutTime" BU_SG_REL_ ADV SG_ 306 WorkingSt_EPB 200;
BA_REL_ "GenSigTimeoutTime" BU_SG_REL_ AVP SG_ 306 WorkingSt_EPB 200;
BA_REL_ "GenSigTimeoutTime" BU_SG_REL_ AVM SG_ 306 WorkingSt_EPB 200;
BA_REL_ "GenSigTimeoutTime" BU_SG_REL_ PDC SG_ 306 WorkingSt_EPB 200;
BA_REL_ "GenSigTimeoutTime" BU_SG_REL_ CDS1 SG_ 306 APA_Available_ESC 200;
BA_REL_ "GenSigTimeoutTime" BU_SG_REL_ ADV SG_ 306 APA_Available_ESC 200;
BA_REL_ "GenSigTimeoutTime" BU_SG_REL_ CDS1 SG_ 306 APA_Intervention_ESC 200;
BA_REL_ "GenSigTimeoutTime" BU_SG_REL_ ADV SG_ 306 APA_Intervention_ESC 200;
BA_REL_ "GenSigTimeoutTime" BU_SG_REL_ CDS1 SG_ 306 LiveCounter_ESC_2_1 200;
BA_REL_ "GenSigTimeoutTime" BU_SG_REL_ CDS2 SG_ 306 LiveCounter_ESC_2_1 200;
BA_REL_ "GenSigTimeoutTime" BU_SG_REL_ ADV SG_ 306 LiveCounter_ESC_2_1 200;
BA_REL_ "GenSigTimeoutTime" BU_SG_REL_ AVP SG_ 306 LiveCounter_ESC_2_1 200;
BA_REL_ "GenSigTimeoutTime" BU_SG_REL_ AVM SG_ 306 LiveCounter_ESC_2_1 200;
BA_REL_ "GenSigTimeoutTime" BU_SG_REL_ PDC SG_ 306 LiveCounter_ESC_2_1 200;
BA_REL_ "GenSigTimeoutTime" BU_SG_REL_ CDS1 SG_ 308 Checksum_ESC_3_1 200;
BA_REL_ "GenSigTimeoutTime" BU_SG_REL_ CDS2 SG_ 308 Checksum_ESC_3_1 200;
BA_REL_ "GenSigTimeoutTime" BU_SG_REL_ ADV SG_ 308 Checksum_ESC_3_1 200;
BA_REL_ "GenSigTimeoutTime" BU_SG_REL_ IRC SG_ 308 Checksum_ESC_3_1 200;
BA_REL_ "GenSigTimeoutTime" BU_SG_REL_ AVP SG_ 308 Checksum_ESC_3_1 200;
BA_REL_ "GenSigTimeoutTime" BU_SG_REL_ AVM SG_ 308 Checksum_ESC_3_1 200;
BA_REL_ "GenSigTimeoutTime" BU_SG_REL_ PDC SG_ 308 Checksum_ESC_3_1 200;
BA_REL_ "GenSigTimeoutTime" BU_SG_REL_ HDMAP SG_ 308 Checksum_ESC_3_1 200;
BA_REL_ "GenSigTimeoutTime" BU_SG_REL_ Fradar SG_ 308 Checksum_ESC_3_1 200;
BA_REL_ "GenSigTimeoutTime" BU_SG_REL_ LCDA1 SG_ 308 Checksum_ESC_3_1 200;
BA_REL_ "GenSigTimeoutTime" BU_SG_REL_ LCDA2 SG_ 308 Checksum_ESC_3_1 200;
BA_REL_ "GenSigTimeoutTime" BU_SG_REL_ CDS1 SG_ 308 YawRate 200;
BA_REL_ "GenSigTimeoutTime" BU_SG_REL_ CDS2 SG_ 308 YawRate 200;
BA_REL_ "GenSigTimeoutTime" BU_SG_REL_ ADV SG_ 308 YawRate 200;
BA_REL_ "GenSigTimeoutTime" BU_SG_REL_ IRC SG_ 308 YawRate 200;
BA_REL_ "GenSigTimeoutTime" BU_SG_REL_ AVP SG_ 308 YawRate 200;
BA_REL_ "GenSigTimeoutTime" BU_SG_REL_ AVM SG_ 308 YawRate 200;
BA_REL_ "GenSigTimeoutTime" BU_SG_REL_ PDC SG_ 308 YawRate 200;
BA_REL_ "GenSigTimeoutTime" BU_SG_REL_ HDMAP SG_ 308 YawRate 200;
BA_REL_ "GenSigTimeoutTime" BU_SG_REL_ Fradar SG_ 308 YawRate 200;
BA_REL_ "GenSigTimeoutTime" BU_SG_REL_ LCDA1 SG_ 308 YawRate 200;
BA_REL_ "GenSigTimeoutTime" BU_SG_REL_ LCDA2 SG_ 308 YawRate 200;
BA_REL_ "GenSigTimeoutTime" BU_SG_REL_ CDS1 SG_ 308 YRSSt 200;
BA_REL_ "GenSigTimeoutTime" BU_SG_REL_ CDS2 SG_ 308 YRSSt 200;
BA_REL_ "GenSigTimeoutTime" BU_SG_REL_ ADV SG_ 308 YRSSt 200;
BA_REL_ "GenSigTimeoutTime" BU_SG_REL_ IRC SG_ 308 YRSSt 200;
BA_REL_ "GenSigTimeoutTime" BU_SG_REL_ AVP SG_ 308 YRSSt 200;
BA_REL_ "GenSigTimeoutTime" BU_SG_REL_ AVM SG_ 308 YRSSt 200;
BA_REL_ "GenSigTimeoutTime" BU_SG_REL_ HDMAP SG_ 308 YRSSt 200;
BA_REL_ "GenSigTimeoutTime" BU_SG_REL_ Fradar SG_ 308 YRSSt 200;
BA_REL_ "GenSigTimeoutTime" BU_SG_REL_ LCDA1 SG_ 308 YRSSt 200;
BA_REL_ "GenSigTimeoutTime" BU_SG_REL_ LCDA2 SG_ 308 YRSSt 200;
BA_REL_ "GenSigTimeoutTime" BU_SG_REL_ CDS1 SG_ 308 Acceleration_X 200;
BA_REL_ "GenSigTimeoutTime" BU_SG_REL_ CDS2 SG_ 308 Acceleration_X 200;
BA_REL_ "GenSigTimeoutTime" BU_SG_REL_ ADV SG_ 308 Acceleration_X 200;
BA_REL_ "GenSigTimeoutTime" BU_SG_REL_ AVP SG_ 308 Acceleration_X 200;
BA_REL_ "GenSigTimeoutTime" BU_SG_REL_ AVM SG_ 308 Acceleration_X 200;
BA_REL_ "GenSigTimeoutTime" BU_SG_REL_ HDMAP SG_ 308 Acceleration_X 200;
BA_REL_ "GenSigTimeoutTime" BU_SG_REL_ Fradar SG_ 308 Acceleration_X 200;
BA_REL_ "GenSigTimeoutTime" BU_SG_REL_ LCDA1 SG_ 308 Acceleration_X 200;
BA_REL_ "GenSigTimeoutTime" BU_SG_REL_ LCDA2 SG_ 308 Acceleration_X 200;
BA_REL_ "GenSigTimeoutTime" BU_SG_REL_ AVP SG_ 308 YawRate_Raw 200;
BA_REL_ "GenSigTimeoutTime" BU_SG_REL_ AVM SG_ 308 YawRate_Raw 200;
BA_REL_ "GenSigTimeoutTime" BU_SG_REL_ CDS1 SG_ 308 Acceleration_Y 200;
BA_REL_ "GenSigTimeoutTime" BU_SG_REL_ CDS2 SG_ 308 Acceleration_Y 200;
BA_REL_ "GenSigTimeoutTime" BU_SG_REL_ ADV SG_ 308 Acceleration_Y 200;
BA_REL_ "GenSigTimeoutTime" BU_SG_REL_ AVP SG_ 308 Acceleration_Y 200;
BA_REL_ "GenSigTimeoutTime" BU_SG_REL_ AVM SG_ 308 Acceleration_Y 200;
BA_REL_ "GenSigTimeoutTime" BU_SG_REL_ HDMAP SG_ 308 Acceleration_Y 200;
BA_REL_ "GenSigTimeoutTime" BU_SG_REL_ Fradar SG_ 308 Acceleration_Y 200;
BA_REL_ "GenSigTimeoutTime" BU_SG_REL_ LCDA1 SG_ 308 Acceleration_Y 200;
BA_REL_ "GenSigTimeoutTime" BU_SG_REL_ LCDA2 SG_ 308 Acceleration_Y 200;
BA_REL_ "GenSigTimeoutTime" BU_SG_REL_ CDS1 SG_ 308 ErrorSt_YRS 200;
BA_REL_ "GenSigTimeoutTime" BU_SG_REL_ CDS2 SG_ 308 ErrorSt_YRS 200;
BA_REL_ "GenSigTimeoutTime" BU_SG_REL_ ADV SG_ 308 ErrorSt_YRS 200;
BA_REL_ "GenSigTimeoutTime" BU_SG_REL_ AVP SG_ 308 ErrorSt_YRS 200;
BA_REL_ "GenSigTimeoutTime" BU_SG_REL_ AVM SG_ 308 ErrorSt_YRS 200;
BA_REL_ "GenSigTimeoutTime" BU_SG_REL_ HDMAP SG_ 308 ErrorSt_YRS 200;
BA_REL_ "GenSigTimeoutTime" BU_SG_REL_ Fradar SG_ 308 ErrorSt_YRS 200;
BA_REL_ "GenSigTimeoutTime" BU_SG_REL_ LCDA1 SG_ 308 ErrorSt_YRS 200;
BA_REL_ "GenSigTimeoutTime" BU_SG_REL_ LCDA2 SG_ 308 ErrorSt_YRS 200;
BA_REL_ "GenSigTimeoutTime" BU_SG_REL_ CDS1 SG_ 308 LiveCounter_ESC_3_1 200;
BA_REL_ "GenSigTimeoutTime" BU_SG_REL_ CDS2 SG_ 308 LiveCounter_ESC_3_1 200;
BA_REL_ "GenSigTimeoutTime" BU_SG_REL_ ADV SG_ 308 LiveCounter_ESC_3_1 200;
BA_REL_ "GenSigTimeoutTime" BU_SG_REL_ IRC SG_ 308 LiveCounter_ESC_3_1 200;
BA_REL_ "GenSigTimeoutTime" BU_SG_REL_ AVP SG_ 308 LiveCounter_ESC_3_1 200;
BA_REL_ "GenSigTimeoutTime" BU_SG_REL_ AVM SG_ 308 LiveCounter_ESC_3_1 200;
BA_REL_ "GenSigTimeoutTime" BU_SG_REL_ PDC SG_ 308 LiveCounter_ESC_3_1 200;
BA_REL_ "GenSigTimeoutTime" BU_SG_REL_ HDMAP SG_ 308 LiveCounter_ESC_3_1 200;
BA_REL_ "GenSigTimeoutTime" BU_SG_REL_ Fradar SG_ 308 LiveCounter_ESC_3_1 200;
BA_REL_ "GenSigTimeoutTime" BU_SG_REL_ LCDA1 SG_ 308 LiveCounter_ESC_3_1 200;
BA_REL_ "GenSigTimeoutTime" BU_SG_REL_ LCDA2 SG_ 308 LiveCounter_ESC_3_1 200;
BA_REL_ "GenSigTimeoutTime" BU_SG_REL_ CDS1 SG_ 312 Checksum_ESC_5_1 200;
BA_REL_ "GenSigTimeoutTime" BU_SG_REL_ CDS2 SG_ 312 Checksum_ESC_5_1 200;
BA_REL_ "GenSigTimeoutTime" BU_SG_REL_ ADV SG_ 312 Checksum_ESC_5_1 200;
BA_REL_ "GenSigTimeoutTime" BU_SG_REL_ HDMAP SG_ 312 Checksum_ESC_5_1 200;
BA_REL_ "GenSigTimeoutTime" BU_SG_REL_ DSM SG_ 312 Checksum_ESC_5_1 200;
BA_REL_ "GenSigTimeoutTime" BU_SG_REL_ CDS1 SG_ 312 ESC_AutoPark_LCSt 200;
BA_REL_ "GenSigTimeoutTime" BU_SG_REL_ ADV SG_ 312 ESC_AutoPark_LCSt 200;
BA_REL_ "GenSigTimeoutTime" BU_SG_REL_ CDS1 SG_ 312 ESC_AutoPark_LCFailureSt 200;
BA_REL_ "GenSigTimeoutTime" BU_SG_REL_ ADV SG_ 312 ESC_AutoPark_LCFailureSt 200;
BA_REL_ "GenSigTimeoutTime" BU_SG_REL_ CDS1 SG_ 312 ESC_AutoPark_LC_BrakeMode 200;
BA_REL_ "GenSigTimeoutTime" BU_SG_REL_ ADV SG_ 312 ESC_AutoPark_LC_BrakeMode 200;
BA_REL_ "GenSigTimeoutTime" BU_SG_REL_ CDS1 SG_ 312 ESC_LSMAvail_Parking 200;
BA_REL_ "GenSigTimeoutTime" BU_SG_REL_ ADV SG_ 312 ESC_LSMAvail_Parking 200;
BA_REL_ "GenSigTimeoutTime" BU_SG_REL_ CDS1 SG_ 312 ESC_AutoPark_LC_APA_Avail 200;
BA_REL_ "GenSigTimeoutTime" BU_SG_REL_ ADV SG_ 312 ESC_AutoPark_LC_APA_Avail 200;
BA_REL_ "GenSigTimeoutTime" BU_SG_REL_ CDS1 SG_ 312 ESC_VLCSt_L12 200;
BA_REL_ "GenSigTimeoutTime" BU_SG_REL_ CDS2 SG_ 312 ESC_VLCSt_L12 200;
BA_REL_ "GenSigTimeoutTime" BU_SG_REL_ CDS1 SG_ 312 ESC_VLCSt_L3 200;
BA_REL_ "GenSigTimeoutTime" BU_SG_REL_ CDS2 SG_ 312 ESC_VLCSt_L3 200;
BA_REL_ "GenSigTimeoutTime" BU_SG_REL_ CDS1 SG_ 312 ESC_VLC_Error_L12 200;
BA_REL_ "GenSigTimeoutTime" BU_SG_REL_ CDS2 SG_ 312 ESC_VLC_Error_L12 200;
BA_REL_ "GenSigTimeoutTime" BU_SG_REL_ CDS1 SG_ 312 ESC_VMC_Error_L3 200;
BA_REL_ "GenSigTimeoutTime" BU_SG_REL_ CDS2 SG_ 312 ESC_VMC_Error_L3 200;
BA_REL_ "GenSigTimeoutTime" BU_SG_REL_ CDS1 SG_ 312 ESC_AutoDriving_LC_Brakemode 200;
BA_REL_ "GenSigTimeoutTime" BU_SG_REL_ CDS2 SG_ 312 ESC_AutoDriving_LC_Brakemode 200;
BA_REL_ "GenSigTimeoutTime" BU_SG_REL_ CDS1 SG_ 312 ESC_AutoPark_LC_RPA_Avail 200;
BA_REL_ "GenSigTimeoutTime" BU_SG_REL_ ADV SG_ 312 ESC_AutoPark_LC_RPA_Avail 200;
BA_REL_ "GenSigTimeoutTime" BU_SG_REL_ CDS1 SG_ 312 ESC_AutoParkingSt_Feedback 200;
BA_REL_ "GenSigTimeoutTime" BU_SG_REL_ CDS2 SG_ 312 ESC_AutoParkingSt_Feedback 200;
BA_REL_ "GenSigTimeoutTime" BU_SG_REL_ ADV SG_ 312 ESC_AutoParkingSt_Feedback 200;
BA_REL_ "GenSigTimeoutTime" BU_SG_REL_ CDS1 SG_ 312 ESC_BrakePedalStatus 200;
BA_REL_ "GenSigTimeoutTime" BU_SG_REL_ CDS2 SG_ 312 ESC_BrakePedalStatus 200;
BA_REL_ "GenSigTimeoutTime" BU_SG_REL_ ADV SG_ 312 ESC_BrakePedalStatus 200;
BA_REL_ "GenSigTimeoutTime" BU_SG_REL_ AVP SG_ 312 ESC_BrakePedalStatus 200;
BA_REL_ "GenSigTimeoutTime" BU_SG_REL_ AVM SG_ 312 ESC_BrakePedalStatus 200;
BA_REL_ "GenSigTimeoutTime" BU_SG_REL_ HDMAP SG_ 312 ESC_BrakePedalStatus 200;
BA_REL_ "GenSigTimeoutTime" BU_SG_REL_ DSM SG_ 312 ESC_BrakePedalStatus 200;
BA_REL_ "GenSigTimeoutTime" BU_SG_REL_ CDS1 SG_ 312 ESC_BrakePedalStatus_Q 200;
BA_REL_ "GenSigTimeoutTime" BU_SG_REL_ CDS2 SG_ 312 ESC_BrakePedalStatus_Q 200;
BA_REL_ "GenSigTimeoutTime" BU_SG_REL_ ADV SG_ 312 ESC_BrakePedalStatus_Q 200;
BA_REL_ "GenSigTimeoutTime" BU_SG_REL_ HDMAP SG_ 312 ESC_BrakePedalStatus_Q 200;
BA_REL_ "GenSigTimeoutTime" BU_SG_REL_ DSM SG_ 312 ESC_BrakePedalStatus_Q 200;
BA_REL_ "GenSigTimeoutTime" BU_SG_REL_ CDS1 SG_ 312 ESC_BrakePedalDominant_Q 200;
BA_REL_ "GenSigTimeoutTime" BU_SG_REL_ CDS2 SG_ 312 ESC_BrakePedalDominant_Q 200;
BA_REL_ "GenSigTimeoutTime" BU_SG_REL_ ADV SG_ 312 ESC_BrakePedalDominant_Q 200;
BA_REL_ "GenSigTimeoutTime" BU_SG_REL_ HDMAP SG_ 312 ESC_BrakePedalDominant_Q 200;
BA_REL_ "GenSigTimeoutTime" BU_SG_REL_ DSM SG_ 312 ESC_BrakePedalDominant_Q 200;
BA_REL_ "GenSigTimeoutTime" BU_SG_REL_ CDS1 SG_ 312 ESC_BrakePedalDominant 200;
BA_REL_ "GenSigTimeoutTime" BU_SG_REL_ CDS2 SG_ 312 ESC_BrakePedalDominant 200;
BA_REL_ "GenSigTimeoutTime" BU_SG_REL_ ADV SG_ 312 ESC_BrakePedalDominant 200;
BA_REL_ "GenSigTimeoutTime" BU_SG_REL_ HDMAP SG_ 312 ESC_BrakePedalDominant 200;
BA_REL_ "GenSigTimeoutTime" BU_SG_REL_ DSM SG_ 312 ESC_BrakePedalDominant 200;
BA_REL_ "GenSigTimeoutTime" BU_SG_REL_ CDS1 SG_ 312 ESC_AutoPark_LC_AVP_Avail 200;
BA_REL_ "GenSigTimeoutTime" BU_SG_REL_ ADV SG_ 312 ESC_AutoPark_LC_AVP_Avail 200;
BA_REL_ "GenSigTimeoutTime" BU_SG_REL_ CDS1 SG_ 312 ESC_ShutOffFinished 200;
BA_REL_ "GenSigTimeoutTime" BU_SG_REL_ CDS2 SG_ 312 ESC_ShutOffFinished 200;
BA_REL_ "GenSigTimeoutTime" BU_SG_REL_ CDS1 SG_ 312 LiveCounter_ESC_5_1 200;
BA_REL_ "GenSigTimeoutTime" BU_SG_REL_ CDS2 SG_ 312 LiveCounter_ESC_5_1 200;
BA_REL_ "GenSigTimeoutTime" BU_SG_REL_ ADV SG_ 312 LiveCounter_ESC_5_1 200;
BA_REL_ "GenSigTimeoutTime" BU_SG_REL_ HDMAP SG_ 312 LiveCounter_ESC_5_1 200;
BA_REL_ "GenSigTimeoutTime" BU_SG_REL_ DSM SG_ 312 LiveCounter_ESC_5_1 200;
BA_REL_ "GenSigTimeoutTime" BU_SG_REL_ CDS1 SG_ 319 Checksum_ESC_7_1 200;
BA_REL_ "GenSigTimeoutTime" BU_SG_REL_ CDS2 SG_ 319 Checksum_ESC_7_1 200;
BA_REL_ "GenSigTimeoutTime" BU_SG_REL_ ADV SG_ 319 Checksum_ESC_7_1 200;
BA_REL_ "GenSigTimeoutTime" BU_SG_REL_ CDS1 SG_ 319 ESC_SuspendStatus_VMC 200;
BA_REL_ "GenSigTimeoutTime" BU_SG_REL_ CDS2 SG_ 319 ESC_SuspendStatus_VMC 200;
BA_REL_ "GenSigTimeoutTime" BU_SG_REL_ ADV SG_ 319 ESC_SuspendStatus_VMC 200;
BA_REL_ "GenSigTimeoutTime" BU_SG_REL_ CDS1 SG_ 319 ESC_BrakeFunctionOverrideStatus 200;
BA_REL_ "GenSigTimeoutTime" BU_SG_REL_ CDS2 SG_ 319 ESC_BrakeFunctionOverrideStatus 200;
BA_REL_ "GenSigTimeoutTime" BU_SG_REL_ ADV SG_ 319 ESC_BrakeFunctionOverrideStatus 200;
BA_REL_ "GenSigTimeoutTime" BU_SG_REL_ CDS1 SG_ 319 LiveCounter_ESC_7_1 200;
BA_REL_ "GenSigTimeoutTime" BU_SG_REL_ CDS2 SG_ 319 LiveCounter_ESC_7_1 200;
BA_REL_ "GenSigTimeoutTime" BU_SG_REL_ ADV SG_ 319 LiveCounter_ESC_7_1 200;
BA_REL_ "GenSigTimeoutTime" BU_SG_REL_ CDS1 SG_ 160 Checksum_ESC_eB_1 100;
BA_REL_ "GenSigTimeoutTime" BU_SG_REL_ CDS1 SG_ 160 ESC_BrakeFxAvailability 100;
BA_REL_ "GenSigTimeoutTime" BU_SG_REL_ CDS1 SG_ 160 ESC_BrakeFxActual 100;
BA_REL_ "GenSigTimeoutTime" BU_SG_REL_ CDS1 SG_ 160 Livecounter_ESC_eB_1 100;
BA_REL_ "GenSigTimeoutTime" BU_SG_REL_ CDS1 SG_ 161 Checksum_ESC_eB_2 100;
BA_REL_ "GenSigTimeoutTime" BU_SG_REL_ CDS1 SG_ 161 ESC_DrvReqTarFxBrakeAvail 100;
BA_REL_ "GenSigTimeoutTime" BU_SG_REL_ CDS1 SG_ 161 ESC_DrvReqTarFxBrake 100;
BA_REL_ "GenSigTimeoutTime" BU_SG_REL_ CDS1 SG_ 161 ESC_BrakeFxTarget 100;
BA_REL_ "GenSigTimeoutTime" BU_SG_REL_ CDS1 SG_ 161 Livecounter_ESC_eB_2 100;
BA_REL_ "GenSigTimeoutTime" BU_SG_REL_ CDS1 SG_ 317 Checksum_eB_2 200;
BA_REL_ "GenSigTimeoutTime" BU_SG_REL_ CDS2 SG_ 317 Checksum_eB_2 200;
BA_REL_ "GenSigTimeoutTime" BU_SG_REL_ CDS1 SG_ 317 eB_VLCSt_L3 200;
BA_REL_ "GenSigTimeoutTime" BU_SG_REL_ CDS2 SG_ 317 eB_VLCSt_L3 200;
BA_REL_ "GenSigTimeoutTime" BU_SG_REL_ CDS1 SG_ 317 eB_VMC_Error_L3 200;
BA_REL_ "GenSigTimeoutTime" BU_SG_REL_ CDS2 SG_ 317 eB_VMC_Error_L3 200;
BA_REL_ "GenSigTimeoutTime" BU_SG_REL_ CDS1 SG_ 317 eB_SuspendStatus_VMC 200;
BA_REL_ "GenSigTimeoutTime" BU_SG_REL_ CDS2 SG_ 317 eB_SuspendStatus_VMC 200;
BA_REL_ "GenSigTimeoutTime" BU_SG_REL_ CDS1 SG_ 317 eB_ShutOffFinished_L3 200;
BA_REL_ "GenSigTimeoutTime" BU_SG_REL_ CDS2 SG_ 317 eB_ShutOffFinished_L3 200;
BA_REL_ "GenSigTimeoutTime" BU_SG_REL_ CDS1 SG_ 317 LiveCounter_eB_2 200;
BA_REL_ "GenSigTimeoutTime" BU_SG_REL_ CDS2 SG_ 317 LiveCounter_eB_2 200;
BA_REL_ "GenSigTimeoutTime" BU_SG_REL_ CDS1 SG_ 336 Checksum_EPS_1_1 200;
BA_REL_ "GenSigTimeoutTime" BU_SG_REL_ CDS2 SG_ 336 Checksum_EPS_1_1 200;
BA_REL_ "GenSigTimeoutTime" BU_SG_REL_ ADV SG_ 336 Checksum_EPS_1_1 200;
BA_REL_ "GenSigTimeoutTime" BU_SG_REL_ DSM SG_ 336 Checksum_EPS_1_1 200;
BA_REL_ "GenSigTimeoutTime" BU_SG_REL_ CDS1 SG_ 336 EPS_1_HandSteeringTorque 200;
BA_REL_ "GenSigTimeoutTime" BU_SG_REL_ CDS2 SG_ 336 EPS_1_HandSteeringTorque 200;
BA_REL_ "GenSigTimeoutTime" BU_SG_REL_ ADV SG_ 336 EPS_1_HandSteeringTorque 200;
BA_REL_ "GenSigTimeoutTime" BU_SG_REL_ DSM SG_ 336 EPS_1_HandSteeringTorque 200;
BA_REL_ "GenSigTimeoutTime" BU_SG_REL_ CDS1 SG_ 336 EPS_1_HandSteeringTorqueSign 200;
BA_REL_ "GenSigTimeoutTime" BU_SG_REL_ CDS2 SG_ 336 EPS_1_HandSteeringTorqueSign 200;
BA_REL_ "GenSigTimeoutTime" BU_SG_REL_ ADV SG_ 336 EPS_1_HandSteeringTorqueSign 200;
BA_REL_ "GenSigTimeoutTime" BU_SG_REL_ DSM SG_ 336 EPS_1_HandSteeringTorqueSign 200;
BA_REL_ "GenSigTimeoutTime" BU_SG_REL_ CDS1 SG_ 336 EPS_1_ErrorStatus 200;
BA_REL_ "GenSigTimeoutTime" BU_SG_REL_ CDS2 SG_ 336 EPS_1_ErrorStatus 200;
BA_REL_ "GenSigTimeoutTime" BU_SG_REL_ ADV SG_ 336 EPS_1_ErrorStatus 200;
BA_REL_ "GenSigTimeoutTime" BU_SG_REL_ CDS1 SG_ 336 EPS_1_HandOffStatus 200;
BA_REL_ "GenSigTimeoutTime" BU_SG_REL_ CDS2 SG_ 336 EPS_1_HandOffStatus 200;
BA_REL_ "GenSigTimeoutTime" BU_SG_REL_ ADV SG_ 336 EPS_1_HandOffStatus 200;
BA_REL_ "GenSigTimeoutTime" BU_SG_REL_ DSM SG_ 336 EPS_1_HandOffStatus 200;
BA_REL_ "GenSigTimeoutTime" BU_SG_REL_ CDS1 SG_ 336 EPS_1_HandOffValid 200;
BA_REL_ "GenSigTimeoutTime" BU_SG_REL_ CDS2 SG_ 336 EPS_1_HandOffValid 200;
BA_REL_ "GenSigTimeoutTime" BU_SG_REL_ ADV SG_ 336 EPS_1_HandOffValid 200;
BA_REL_ "GenSigTimeoutTime" BU_SG_REL_ DSM SG_ 336 EPS_1_HandOffValid 200;
BA_REL_ "GenSigTimeoutTime" BU_SG_REL_ CDS1 SG_ 336 EPS_1_LKAStatus 200;
BA_REL_ "GenSigTimeoutTime" BU_SG_REL_ CDS2 SG_ 336 EPS_1_LKAStatus 200;
BA_REL_ "GenSigTimeoutTime" BU_SG_REL_ CDS1 SG_ 336 EPS_1_OverlayInputTorque 200;
BA_REL_ "GenSigTimeoutTime" BU_SG_REL_ CDS2 SG_ 336 EPS_1_OverlayInputTorque 200;
BA_REL_ "GenSigTimeoutTime" BU_SG_REL_ ADV SG_ 336 EPS_1_OverlayInputTorque 200;
BA_REL_ "GenSigTimeoutTime" BU_SG_REL_ CDS1 SG_ 336 EPS_1_OverlayInputTorqueSign 200;
BA_REL_ "GenSigTimeoutTime" BU_SG_REL_ CDS2 SG_ 336 EPS_1_OverlayInputTorqueSign 200;
BA_REL_ "GenSigTimeoutTime" BU_SG_REL_ ADV SG_ 336 EPS_1_OverlayInputTorqueSign 200;
BA_REL_ "GenSigTimeoutTime" BU_SG_REL_ Gateway SG_ 336 EPS_1_AbortFeedback_HAD 200;
BA_REL_ "GenSigTimeoutTime" BU_SG_REL_ CDS1 SG_ 336 EPS_1_AbortFeedback_HAD 200;
BA_REL_ "GenSigTimeoutTime" BU_SG_REL_ CDS2 SG_ 336 EPS_1_AbortFeedback_HAD 200;
BA_REL_ "GenSigTimeoutTime" BU_SG_REL_ ADV SG_ 336 EPS_1_AbortFeedback_HAD 200;
BA_REL_ "GenSigTimeoutTime" BU_SG_REL_ CDS1 SG_ 336 LiveCounter_EPS_1_1 200;
BA_REL_ "GenSigTimeoutTime" BU_SG_REL_ CDS2 SG_ 336 LiveCounter_EPS_1_1 200;
BA_REL_ "GenSigTimeoutTime" BU_SG_REL_ ADV SG_ 336 LiveCounter_EPS_1_1 200;
BA_REL_ "GenSigTimeoutTime" BU_SG_REL_ DSM SG_ 336 LiveCounter_EPS_1_1 200;
BA_REL_ "GenSigTimeoutTime" BU_SG_REL_ CDS1 SG_ 337 Checksum_EPS_1_2 200;
BA_REL_ "GenSigTimeoutTime" BU_SG_REL_ CDS2 SG_ 337 Checksum_EPS_1_2 200;
BA_REL_ "GenSigTimeoutTime" BU_SG_REL_ ADV SG_ 337 Checksum_EPS_1_2 200;
BA_REL_ "GenSigTimeoutTime" BU_SG_REL_ CDS1 SG_ 337 EPS_1_SACCStatus 200;
BA_REL_ "GenSigTimeoutTime" BU_SG_REL_ CDS2 SG_ 337 EPS_1_SACCStatus 200;
BA_REL_ "GenSigTimeoutTime" BU_SG_REL_ CDS1 SG_ 337 EPS_1_HWPStatus 200;
BA_REL_ "GenSigTimeoutTime" BU_SG_REL_ CDS2 SG_ 337 EPS_1_HWPStatus 200;
BA_REL_ "GenSigTimeoutTime" BU_SG_REL_ CDS1 SG_ 337 EPS_1_TJPStatus 200;
BA_REL_ "GenSigTimeoutTime" BU_SG_REL_ CDS2 SG_ 337 EPS_1_TJPStatus 200;
BA_REL_ "GenSigTimeoutTime" BU_SG_REL_ CDS1 SG_ 337 EPS_1_APAStatus 200;
BA_REL_ "GenSigTimeoutTime" BU_SG_REL_ ADV SG_ 337 EPS_1_APAStatus 200;
BA_REL_ "GenSigTimeoutTime" BU_SG_REL_ CDS1 SG_ 337 EPS_1_RPAStatus 200;
BA_REL_ "GenSigTimeoutTime" BU_SG_REL_ ADV SG_ 337 EPS_1_RPAStatus 200;
BA_REL_ "GenSigTimeoutTime" BU_SG_REL_ CDS1 SG_ 337 EPS_1_AVPStatus 200;
BA_REL_ "GenSigTimeoutTime" BU_SG_REL_ ADV SG_ 337 EPS_1_AVPStatus 200;
BA_REL_ "GenSigTimeoutTime" BU_SG_REL_ CDS1 SG_ 337 EPS_1_DegradeLevel_HAD 200;
BA_REL_ "GenSigTimeoutTime" BU_SG_REL_ CDS2 SG_ 337 EPS_1_DegradeLevel_HAD 200;
BA_REL_ "GenSigTimeoutTime" BU_SG_REL_ ADV SG_ 337 EPS_1_DegradeLevel_HAD 200;
BA_REL_ "GenSigTimeoutTime" BU_SG_REL_ CDS1 SG_ 337 EPS_1_DriftWarning 200;
BA_REL_ "GenSigTimeoutTime" BU_SG_REL_ CDS2 SG_ 337 EPS_1_DriftWarning 200;
BA_REL_ "GenSigTimeoutTime" BU_SG_REL_ CDS1 SG_ 337 EPS_1_AutoDrivingMode 200;
BA_REL_ "GenSigTimeoutTime" BU_SG_REL_ CDS2 SG_ 337 EPS_1_AutoDrivingMode 200;
BA_REL_ "GenSigTimeoutTime" BU_SG_REL_ ADV SG_ 337 EPS_1_AutoDrivingMode 200;
BA_REL_ "GenSigTimeoutTime" BU_SG_REL_ CDS1 SG_ 337 LiveCounter_EPS_1_2 200;
BA_REL_ "GenSigTimeoutTime" BU_SG_REL_ CDS2 SG_ 337 LiveCounter_EPS_1_2 200;
BA_REL_ "GenSigTimeoutTime" BU_SG_REL_ ADV SG_ 337 LiveCounter_EPS_1_2 200;
BA_REL_ "GenSigTimeoutTime" BU_SG_REL_ CDS1 SG_ 208 Checksum_EPS_1_SAS_1 100;
BA_REL_ "GenSigTimeoutTime" BU_SG_REL_ CDS2 SG_ 208 Checksum_EPS_1_SAS_1 100;
BA_REL_ "GenSigTimeoutTime" BU_SG_REL_ ADV SG_ 208 Checksum_EPS_1_SAS_1 100;
BA_REL_ "GenSigTimeoutTime" BU_SG_REL_ IRC SG_ 208 Checksum_EPS_1_SAS_1 100;
BA_REL_ "GenSigTimeoutTime" BU_SG_REL_ AVP SG_ 208 Checksum_EPS_1_SAS_1 100;
BA_REL_ "GenSigTimeoutTime" BU_SG_REL_ AVM SG_ 208 Checksum_EPS_1_SAS_1 100;
BA_REL_ "GenSigTimeoutTime" BU_SG_REL_ PDC SG_ 208 Checksum_EPS_1_SAS_1 100;
BA_REL_ "GenSigTimeoutTime" BU_SG_REL_ HDMAP SG_ 208 Checksum_EPS_1_SAS_1 100;
BA_REL_ "GenSigTimeoutTime" BU_SG_REL_ DSM SG_ 208 Checksum_EPS_1_SAS_1 100;
BA_REL_ "GenSigTimeoutTime" BU_SG_REL_ Fradar SG_ 208 Checksum_EPS_1_SAS_1 100;
BA_REL_ "GenSigTimeoutTime" BU_SG_REL_ LCDA1 SG_ 208 Checksum_EPS_1_SAS_1 100;
BA_REL_ "GenSigTimeoutTime" BU_SG_REL_ LCDA2 SG_ 208 Checksum_EPS_1_SAS_1 100;
BA_REL_ "GenSigTimeoutTime" BU_SG_REL_ CDS1 SG_ 208 SteeringWheelAngle 100;
BA_REL_ "GenSigTimeoutTime" BU_SG_REL_ CDS2 SG_ 208 SteeringWheelAngle 100;
BA_REL_ "GenSigTimeoutTime" BU_SG_REL_ ADV SG_ 208 SteeringWheelAngle 100;
BA_REL_ "GenSigTimeoutTime" BU_SG_REL_ IRC SG_ 208 SteeringWheelAngle 100;
BA_REL_ "GenSigTimeoutTime" BU_SG_REL_ AVP SG_ 208 SteeringWheelAngle 100;
BA_REL_ "GenSigTimeoutTime" BU_SG_REL_ AVM SG_ 208 SteeringWheelAngle 100;
BA_REL_ "GenSigTimeoutTime" BU_SG_REL_ PDC SG_ 208 SteeringWheelAngle 100;
BA_REL_ "GenSigTimeoutTime" BU_SG_REL_ HDMAP SG_ 208 SteeringWheelAngle 100;
BA_REL_ "GenSigTimeoutTime" BU_SG_REL_ DSM SG_ 208 SteeringWheelAngle 100;
BA_REL_ "GenSigTimeoutTime" BU_SG_REL_ Fradar SG_ 208 SteeringWheelAngle 100;
BA_REL_ "GenSigTimeoutTime" BU_SG_REL_ LCDA1 SG_ 208 SteeringWheelAngle 100;
BA_REL_ "GenSigTimeoutTime" BU_SG_REL_ LCDA2 SG_ 208 SteeringWheelAngle 100;
BA_REL_ "GenSigTimeoutTime" BU_SG_REL_ CDS1 SG_ 208 SteeringWheelAngleSign 100;
BA_REL_ "GenSigTimeoutTime" BU_SG_REL_ CDS2 SG_ 208 SteeringWheelAngleSign 100;
BA_REL_ "GenSigTimeoutTime" BU_SG_REL_ ADV SG_ 208 SteeringWheelAngleSign 100;
BA_REL_ "GenSigTimeoutTime" BU_SG_REL_ IRC SG_ 208 SteeringWheelAngleSign 100;
BA_REL_ "GenSigTimeoutTime" BU_SG_REL_ AVP SG_ 208 SteeringWheelAngleSign 100;
BA_REL_ "GenSigTimeoutTime" BU_SG_REL_ AVM SG_ 208 SteeringWheelAngleSign 100;
BA_REL_ "GenSigTimeoutTime" BU_SG_REL_ PDC SG_ 208 SteeringWheelAngleSign 100;
BA_REL_ "GenSigTimeoutTime" BU_SG_REL_ HDMAP SG_ 208 SteeringWheelAngleSign 100;
BA_REL_ "GenSigTimeoutTime" BU_SG_REL_ DSM SG_ 208 SteeringWheelAngleSign 100;
BA_REL_ "GenSigTimeoutTime" BU_SG_REL_ Fradar SG_ 208 SteeringWheelAngleSign 100;
BA_REL_ "GenSigTimeoutTime" BU_SG_REL_ LCDA1 SG_ 208 SteeringWheelAngleSign 100;
BA_REL_ "GenSigTimeoutTime" BU_SG_REL_ LCDA2 SG_ 208 SteeringWheelAngleSign 100;
BA_REL_ "GenSigTimeoutTime" BU_SG_REL_ CDS1 SG_ 208 SteeringWheelSpeed 100;
BA_REL_ "GenSigTimeoutTime" BU_SG_REL_ CDS2 SG_ 208 SteeringWheelSpeed 100;
BA_REL_ "GenSigTimeoutTime" BU_SG_REL_ IRC SG_ 208 SteeringWheelSpeed 100;
BA_REL_ "GenSigTimeoutTime" BU_SG_REL_ HDMAP SG_ 208 SteeringWheelSpeed 100;
BA_REL_ "GenSigTimeoutTime" BU_SG_REL_ DSM SG_ 208 SteeringWheelSpeed 100;
BA_REL_ "GenSigTimeoutTime" BU_SG_REL_ CDS1 SG_ 208 SteeringWheelSpeedSign 100;
BA_REL_ "GenSigTimeoutTime" BU_SG_REL_ CDS2 SG_ 208 SteeringWheelSpeedSign 100;
BA_REL_ "GenSigTimeoutTime" BU_SG_REL_ IRC SG_ 208 SteeringWheelSpeedSign 100;
BA_REL_ "GenSigTimeoutTime" BU_SG_REL_ HDMAP SG_ 208 SteeringWheelSpeedSign 100;
BA_REL_ "GenSigTimeoutTime" BU_SG_REL_ DSM SG_ 208 SteeringWheelSpeedSign 100;
BA_REL_ "GenSigTimeoutTime" BU_SG_REL_ CDS1 SG_ 208 SAS_St 100;
BA_REL_ "GenSigTimeoutTime" BU_SG_REL_ CDS2 SG_ 208 SAS_St 100;
BA_REL_ "GenSigTimeoutTime" BU_SG_REL_ ADV SG_ 208 SAS_St 100;
BA_REL_ "GenSigTimeoutTime" BU_SG_REL_ IRC SG_ 208 SAS_St 100;
BA_REL_ "GenSigTimeoutTime" BU_SG_REL_ AVP SG_ 208 SAS_St 100;
BA_REL_ "GenSigTimeoutTime" BU_SG_REL_ AVM SG_ 208 SAS_St 100;
BA_REL_ "GenSigTimeoutTime" BU_SG_REL_ HDMAP SG_ 208 SAS_St 100;
BA_REL_ "GenSigTimeoutTime" BU_SG_REL_ DSM SG_ 208 SAS_St 100;
BA_REL_ "GenSigTimeoutTime" BU_SG_REL_ Fradar SG_ 208 SAS_St 100;
BA_REL_ "GenSigTimeoutTime" BU_SG_REL_ LCDA1 SG_ 208 SAS_St 100;
BA_REL_ "GenSigTimeoutTime" BU_SG_REL_ LCDA2 SG_ 208 SAS_St 100;
BA_REL_ "GenSigTimeoutTime" BU_SG_REL_ CDS1 SG_ 208 LiveCounter_EPS_1_SAS_1 100;
BA_REL_ "GenSigTimeoutTime" BU_SG_REL_ CDS2 SG_ 208 LiveCounter_EPS_1_SAS_1 100;
BA_REL_ "GenSigTimeoutTime" BU_SG_REL_ ADV SG_ 208 LiveCounter_EPS_1_SAS_1 100;
BA_REL_ "GenSigTimeoutTime" BU_SG_REL_ IRC SG_ 208 LiveCounter_EPS_1_SAS_1 100;
BA_REL_ "GenSigTimeoutTime" BU_SG_REL_ AVP SG_ 208 LiveCounter_EPS_1_SAS_1 100;
BA_REL_ "GenSigTimeoutTime" BU_SG_REL_ AVM SG_ 208 LiveCounter_EPS_1_SAS_1 100;
BA_REL_ "GenSigTimeoutTime" BU_SG_REL_ PDC SG_ 208 LiveCounter_EPS_1_SAS_1 100;
BA_REL_ "GenSigTimeoutTime" BU_SG_REL_ HDMAP SG_ 208 LiveCounter_EPS_1_SAS_1 100;
BA_REL_ "GenSigTimeoutTime" BU_SG_REL_ DSM SG_ 208 LiveCounter_EPS_1_SAS_1 100;
BA_REL_ "GenSigTimeoutTime" BU_SG_REL_ Fradar SG_ 208 LiveCounter_EPS_1_SAS_1 100;
BA_REL_ "GenSigTimeoutTime" BU_SG_REL_ LCDA1 SG_ 208 LiveCounter_EPS_1_SAS_1 100;
BA_REL_ "GenSigTimeoutTime" BU_SG_REL_ LCDA2 SG_ 208 LiveCounter_EPS_1_SAS_1 100;
BA_REL_ "GenSigTimeoutTime" BU_SG_REL_ CDS1 SG_ 534 DMS_VehicleModeInfo 1000;
BA_REL_ "GenSigTimeoutTime" BU_SG_REL_ CDS2 SG_ 534 DMS_VehicleModeInfo 1000;
BA_REL_ "GenSigTimeoutTime" BU_SG_REL_ AVP SG_ 534 DMS_VehicleModeInfo 1000;
BA_REL_ "GenSigTimeoutTime" BU_SG_REL_ AVM SG_ 534 DMS_VehicleModeInfo 1000;
BA_REL_ "GenSigTimeoutTime" BU_SG_REL_ CDS1 SG_ 534 DMS_ErrorStatus 1000;
BA_REL_ "GenSigTimeoutTime" BU_SG_REL_ CDS1 SG_ 534 DMS_TargetVehicleMode 1000;
BA_REL_ "GenSigTimeoutTime" BU_SG_REL_ CDS2 SG_ 534 DMS_TargetVehicleMode 1000;
BA_REL_ "GenSigTimeoutTime" BU_SG_REL_ CDS1 SG_ 290 Checksum_HCU_2_12 200;
BA_REL_ "GenSigTimeoutTime" BU_SG_REL_ CDS2 SG_ 290 Checksum_HCU_2_12 200;
BA_REL_ "GenSigTimeoutTime" BU_SG_REL_ ADV SG_ 290 Checksum_HCU_2_12 200;
BA_REL_ "GenSigTimeoutTime" BU_SG_REL_ IRC SG_ 290 Checksum_HCU_2_12 200;
BA_REL_ "GenSigTimeoutTime" BU_SG_REL_ AVP SG_ 290 Checksum_HCU_2_12 200;
BA_REL_ "GenSigTimeoutTime" BU_SG_REL_ AVM SG_ 290 Checksum_HCU_2_12 200;
BA_REL_ "GenSigTimeoutTime" BU_SG_REL_ PDC SG_ 290 Checksum_HCU_2_12 200;
BA_REL_ "GenSigTimeoutTime" BU_SG_REL_ DSM SG_ 290 Checksum_HCU_2_12 200;
BA_REL_ "GenSigTimeoutTime" BU_SG_REL_ Fradar SG_ 290 Checksum_HCU_2_12 200;
BA_REL_ "GenSigTimeoutTime" BU_SG_REL_ LCDA1 SG_ 290 Checksum_HCU_2_12 200;
BA_REL_ "GenSigTimeoutTime" BU_SG_REL_ LCDA2 SG_ 290 Checksum_HCU_2_12 200;
BA_REL_ "GenSigTimeoutTime" BU_SG_REL_ CDS1 SG_ 290 HCU_LeverInfo 200;
BA_REL_ "GenSigTimeoutTime" BU_SG_REL_ CDS2 SG_ 290 HCU_LeverInfo 200;
BA_REL_ "GenSigTimeoutTime" BU_SG_REL_ ADV SG_ 290 HCU_LeverInfo 200;
BA_REL_ "GenSigTimeoutTime" BU_SG_REL_ IRC SG_ 290 HCU_LeverInfo 200;
BA_REL_ "GenSigTimeoutTime" BU_SG_REL_ AVP SG_ 290 HCU_LeverInfo 200;
BA_REL_ "GenSigTimeoutTime" BU_SG_REL_ AVM SG_ 290 HCU_LeverInfo 200;
BA_REL_ "GenSigTimeoutTime" BU_SG_REL_ PDC SG_ 290 HCU_LeverInfo 200;
BA_REL_ "GenSigTimeoutTime" BU_SG_REL_ DSM SG_ 290 HCU_LeverInfo 200;
BA_REL_ "GenSigTimeoutTime" BU_SG_REL_ Fradar SG_ 290 HCU_LeverInfo 200;
BA_REL_ "GenSigTimeoutTime" BU_SG_REL_ LCDA1 SG_ 290 HCU_LeverInfo 200;
BA_REL_ "GenSigTimeoutTime" BU_SG_REL_ LCDA2 SG_ 290 HCU_LeverInfo 200;
BA_REL_ "GenSigTimeoutTime" BU_SG_REL_ CDS1 SG_ 290 HCU_AutoParkingResponse_L12 200;
BA_REL_ "GenSigTimeoutTime" BU_SG_REL_ ADV SG_ 290 HCU_AutoParkingResponse_L12 200;
BA_REL_ "GenSigTimeoutTime" BU_SG_REL_ CDS1 SG_ 290 HCU_AutoParkingResponse_L3 200;
BA_REL_ "GenSigTimeoutTime" BU_SG_REL_ CDS1 SG_ 290 HCU_CapabilitySt_AutoParking 200;
BA_REL_ "GenSigTimeoutTime" BU_SG_REL_ CDS2 SG_ 290 HCU_CapabilitySt_AutoParking 200;
BA_REL_ "GenSigTimeoutTime" BU_SG_REL_ ADV SG_ 290 HCU_CapabilitySt_AutoParking 200;
BA_REL_ "GenSigTimeoutTime" BU_SG_REL_ CDS1 SG_ 290 Livecounter_HCU_2_12 200;
BA_REL_ "GenSigTimeoutTime" BU_SG_REL_ CDS2 SG_ 290 Livecounter_HCU_2_12 200;
BA_REL_ "GenSigTimeoutTime" BU_SG_REL_ ADV SG_ 290 Livecounter_HCU_2_12 200;
BA_REL_ "GenSigTimeoutTime" BU_SG_REL_ IRC SG_ 290 Livecounter_HCU_2_12 200;
BA_REL_ "GenSigTimeoutTime" BU_SG_REL_ AVP SG_ 290 Livecounter_HCU_2_12 200;
BA_REL_ "GenSigTimeoutTime" BU_SG_REL_ AVM SG_ 290 Livecounter_HCU_2_12 200;
BA_REL_ "GenSigTimeoutTime" BU_SG_REL_ PDC SG_ 290 Livecounter_HCU_2_12 200;
BA_REL_ "GenSigTimeoutTime" BU_SG_REL_ DSM SG_ 290 Livecounter_HCU_2_12 200;
BA_REL_ "GenSigTimeoutTime" BU_SG_REL_ Fradar SG_ 290 Livecounter_HCU_2_12 200;
BA_REL_ "GenSigTimeoutTime" BU_SG_REL_ LCDA1 SG_ 290 Livecounter_HCU_2_12 200;
BA_REL_ "GenSigTimeoutTime" BU_SG_REL_ LCDA2 SG_ 290 Livecounter_HCU_2_12 200;
BA_REL_ "GenSigTimeoutTime" BU_SG_REL_ CDS1 SG_ 264 Checksum_HCU_2_4 200;
BA_REL_ "GenSigTimeoutTime" BU_SG_REL_ CDS2 SG_ 264 Checksum_HCU_2_4 200;
BA_REL_ "GenSigTimeoutTime" BU_SG_REL_ CDS1 SG_ 264 HCU_AutoDrivingResponseSt_L12 200;
BA_REL_ "GenSigTimeoutTime" BU_SG_REL_ CDS2 SG_ 264 HCU_AutoDrivingResponseSt_L12 200;
BA_REL_ "GenSigTimeoutTime" BU_SG_REL_ CDS1 SG_ 264 HCU_AutoDrivingResponseSt_L3 200;
BA_REL_ "GenSigTimeoutTime" BU_SG_REL_ CDS2 SG_ 264 HCU_AutoDrivingResponseSt_L3 200;
BA_REL_ "GenSigTimeoutTime" BU_SG_REL_ CDS1 SG_ 264 HCU_CapabilitySt_AutoDriving 200;
BA_REL_ "GenSigTimeoutTime" BU_SG_REL_ CDS2 SG_ 264 HCU_CapabilitySt_AutoDriving 200;
BA_REL_ "GenSigTimeoutTime" BU_SG_REL_ CDS1 SG_ 264 LiveCounter_HCU_2_4 200;
BA_REL_ "GenSigTimeoutTime" BU_SG_REL_ CDS2 SG_ 264 LiveCounter_HCU_2_4 200;
BA_REL_ "GenSigTimeoutTime" BU_SG_REL_ CDS1 SG_ 147 Checksum_HCU_2_7 100;
BA_REL_ "GenSigTimeoutTime" BU_SG_REL_ CDS2 SG_ 147 Checksum_HCU_2_7 100;
BA_REL_ "GenSigTimeoutTime" BU_SG_REL_ ADV SG_ 147 Checksum_HCU_2_7 100;
BA_REL_ "GenSigTimeoutTime" BU_SG_REL_ DSM SG_ 147 Checksum_HCU_2_7 100;
BA_REL_ "GenSigTimeoutTime" BU_SG_REL_ CDS1 SG_ 147 HCU_EVReady 100;
BA_REL_ "GenSigTimeoutTime" BU_SG_REL_ CDS2 SG_ 147 HCU_EVReady 100;
BA_REL_ "GenSigTimeoutTime" BU_SG_REL_ ADV SG_ 147 HCU_EVReady 100;
BA_REL_ "GenSigTimeoutTime" BU_SG_REL_ DSM SG_ 147 HCU_EVReady 100;
BA_REL_ "GenSigTimeoutTime" BU_SG_REL_ CDS1 SG_ 147 LiveCounter_HCU_2_7 100;
BA_REL_ "GenSigTimeoutTime" BU_SG_REL_ CDS2 SG_ 147 LiveCounter_HCU_2_7 100;
BA_REL_ "GenSigTimeoutTime" BU_SG_REL_ ADV SG_ 147 LiveCounter_HCU_2_7 100;
BA_REL_ "GenSigTimeoutTime" BU_SG_REL_ DSM SG_ 147 LiveCounter_HCU_2_7 100;
BA_REL_ "GenSigTimeoutTime" BU_SG_REL_ CDS1 SG_ 146 Checksum_HCU_2_2 100;
BA_REL_ "GenSigTimeoutTime" BU_SG_REL_ CDS2 SG_ 146 Checksum_HCU_2_2 100;
BA_REL_ "GenSigTimeoutTime" BU_SG_REL_ ADV SG_ 146 Checksum_HCU_2_2 100;
BA_REL_ "GenSigTimeoutTime" BU_SG_REL_ HDMAP SG_ 146 Checksum_HCU_2_2 100;
BA_REL_ "GenSigTimeoutTime" BU_SG_REL_ LCDA1 SG_ 146 Checksum_HCU_2_2 100;
BA_REL_ "GenSigTimeoutTime" BU_SG_REL_ LCDA2 SG_ 146 Checksum_HCU_2_2 100;
BA_REL_ "GenSigTimeoutTime" BU_SG_REL_ CDS1 SG_ 146 HCU_AccelerationPedalPosition 100;
BA_REL_ "GenSigTimeoutTime" BU_SG_REL_ CDS2 SG_ 146 HCU_AccelerationPedalPosition 100;
BA_REL_ "GenSigTimeoutTime" BU_SG_REL_ ADV SG_ 146 HCU_AccelerationPedalPosition 100;
BA_REL_ "GenSigTimeoutTime" BU_SG_REL_ HDMAP SG_ 146 HCU_AccelerationPedalPosition 100;
BA_REL_ "GenSigTimeoutTime" BU_SG_REL_ LCDA1 SG_ 146 HCU_AccelerationPedalPosition 100;
BA_REL_ "GenSigTimeoutTime" BU_SG_REL_ LCDA2 SG_ 146 HCU_AccelerationPedalPosition 100;
BA_REL_ "GenSigTimeoutTime" BU_SG_REL_ CDS1 SG_ 146 HCU_CalcAccelerationPedalPositio 100;
BA_REL_ "GenSigTimeoutTime" BU_SG_REL_ CDS2 SG_ 146 HCU_CalcAccelerationPedalPositio 100;
BA_REL_ "GenSigTimeoutTime" BU_SG_REL_ ADV SG_ 146 HCU_CalcAccelerationPedalPositio 100;
BA_REL_ "GenSigTimeoutTime" BU_SG_REL_ HDMAP SG_ 146 HCU_CalcAccelerationPedalPositio 100;
BA_REL_ "GenSigTimeoutTime" BU_SG_REL_ CDS1 SG_ 146 HCU_AccelerationPedalOverride 100;
BA_REL_ "GenSigTimeoutTime" BU_SG_REL_ CDS2 SG_ 146 HCU_AccelerationPedalOverride 100;
BA_REL_ "GenSigTimeoutTime" BU_SG_REL_ ADV SG_ 146 HCU_AccelerationPedalOverride 100;
BA_REL_ "GenSigTimeoutTime" BU_SG_REL_ CDS1 SG_ 146 HCU_KickdownReq 100;
BA_REL_ "GenSigTimeoutTime" BU_SG_REL_ CDS2 SG_ 146 HCU_KickdownReq 100;
BA_REL_ "GenSigTimeoutTime" BU_SG_REL_ ADV SG_ 146 HCU_KickdownReq 100;
BA_REL_ "GenSigTimeoutTime" BU_SG_REL_ CDS1 SG_ 146 LiveCounter_HCU_2_2 100;
BA_REL_ "GenSigTimeoutTime" BU_SG_REL_ CDS2 SG_ 146 LiveCounter_HCU_2_2 100;
BA_REL_ "GenSigTimeoutTime" BU_SG_REL_ ADV SG_ 146 LiveCounter_HCU_2_2 100;
BA_REL_ "GenSigTimeoutTime" BU_SG_REL_ HDMAP SG_ 146 LiveCounter_HCU_2_2 100;
BA_REL_ "GenSigTimeoutTime" BU_SG_REL_ LCDA1 SG_ 146 LiveCounter_HCU_2_2 100;
BA_REL_ "GenSigTimeoutTime" BU_SG_REL_ LCDA2 SG_ 146 LiveCounter_HCU_2_2 100;
BA_REL_ "GenSigTimeoutTime" BU_SG_REL_ CDS1 SG_ 151 HCU_MCU1TMSpeed 100;
BA_REL_ "GenSigTimeoutTime" BU_SG_REL_ CDS2 SG_ 151 HCU_MCU1TMSpeed 100;
BA_REL_ "GenSigTimeoutTime" BU_SG_REL_ CDS1 SG_ 151 HCU_MCU1ActTMTorque 100;
BA_REL_ "GenSigTimeoutTime" BU_SG_REL_ CDS2 SG_ 151 HCU_MCU1ActTMTorque 100;
BA_REL_ "GenSigTimeoutTime" BU_SG_REL_ CDS1 SG_ 151 HCU_MCU1TMMAMTorque 100;
BA_REL_ "GenSigTimeoutTime" BU_SG_REL_ CDS2 SG_ 151 HCU_MCU1TMMAMTorque 100;
BA_REL_ "GenSigTimeoutTime" BU_SG_REL_ CDS1 SG_ 151 HCU_MCU1TMMAGTorque 100;
BA_REL_ "GenSigTimeoutTime" BU_SG_REL_ CDS2 SG_ 151 HCU_MCU1TMMAGTorque 100;
BA_REL_ "GenSigTimeoutTime" BU_SG_REL_ CDS1 SG_ 152 HCU_MCU2TMSpeed 100;
BA_REL_ "GenSigTimeoutTime" BU_SG_REL_ CDS2 SG_ 152 HCU_MCU2TMSpeed 100;
BA_REL_ "GenSigTimeoutTime" BU_SG_REL_ CDS1 SG_ 152 HCU_MCU2ActTMTorque 100;
BA_REL_ "GenSigTimeoutTime" BU_SG_REL_ CDS2 SG_ 152 HCU_MCU2ActTMTorque 100;
BA_REL_ "GenSigTimeoutTime" BU_SG_REL_ CDS1 SG_ 152 HCU_MCU2TMMAMTorque 100;
BA_REL_ "GenSigTimeoutTime" BU_SG_REL_ CDS2 SG_ 152 HCU_MCU2TMMAMTorque 100;
BA_REL_ "GenSigTimeoutTime" BU_SG_REL_ CDS1 SG_ 152 HCU_MCU2TMMAGTorque 100;
BA_REL_ "GenSigTimeoutTime" BU_SG_REL_ CDS2 SG_ 152 HCU_MCU2TMMAGTorque 100;
BA_REL_ "GenSigTimeoutTime" BU_SG_REL_ CDS1 SG_ 288 Checksum_EGSM_1 200;
BA_REL_ "GenSigTimeoutTime" BU_SG_REL_ ADV SG_ 288 Checksum_EGSM_1 200;
BA_REL_ "GenSigTimeoutTime" BU_SG_REL_ CDS1 SG_ 288 EGSM_SecurityButton 200;
BA_REL_ "GenSigTimeoutTime" BU_SG_REL_ ADV SG_ 288 EGSM_SecurityButton 200;
BA_REL_ "GenSigTimeoutTime" BU_SG_REL_ CDS1 SG_ 288 EGSM_SecurityButtonErrorSt 200;
BA_REL_ "GenSigTimeoutTime" BU_SG_REL_ ADV SG_ 288 EGSM_SecurityButtonErrorSt 200;
BA_REL_ "GenSigTimeoutTime" BU_SG_REL_ CDS1 SG_ 288 EGSM_ErrorStatus 200;
BA_REL_ "GenSigTimeoutTime" BU_SG_REL_ ADV SG_ 288 EGSM_ErrorStatus 200;
BA_REL_ "GenSigTimeoutTime" BU_SG_REL_ CDS1 SG_ 288 Livecounter_EGSM_1 200;
BA_REL_ "GenSigTimeoutTime" BU_SG_REL_ ADV SG_ 288 Livecounter_EGSM_1 200;
BA_REL_ "GenSigTimeoutTime" BU_SG_REL_ CDS1 SG_ 512 Checksum_ACU_1 1000;
BA_REL_ "GenSigTimeoutTime" BU_SG_REL_ CDS2 SG_ 512 Checksum_ACU_1 1000;
BA_REL_ "GenSigTimeoutTime" BU_SG_REL_ ADV SG_ 512 Checksum_ACU_1 1000;
BA_REL_ "GenSigTimeoutTime" BU_SG_REL_ CDS1 SG_ 512 CrashInfo 1000;
BA_REL_ "GenSigTimeoutTime" BU_SG_REL_ CDS2 SG_ 512 CrashInfo 1000;
BA_REL_ "GenSigTimeoutTime" BU_SG_REL_ ADV SG_ 512 CrashInfo 1000;
BA_REL_ "GenSigTimeoutTime" BU_SG_REL_ CDS1 SG_ 512 SysSt_ACU 1000;
BA_REL_ "GenSigTimeoutTime" BU_SG_REL_ CDS2 SG_ 512 SysSt_ACU 1000;
BA_REL_ "GenSigTimeoutTime" BU_SG_REL_ ADV SG_ 512 SysSt_ACU 1000;
BA_REL_ "GenSigTimeoutTime" BU_SG_REL_ CDS1 SG_ 512 SeatBeltSt_Driver 1000;
BA_REL_ "GenSigTimeoutTime" BU_SG_REL_ CDS2 SG_ 512 SeatBeltSt_Driver 1000;
BA_REL_ "GenSigTimeoutTime" BU_SG_REL_ ADV SG_ 512 SeatBeltSt_Driver 1000;
BA_REL_ "GenSigTimeoutTime" BU_SG_REL_ CDS1 SG_ 512 LiveCounter_ACU_1 1000;
BA_REL_ "GenSigTimeoutTime" BU_SG_REL_ CDS2 SG_ 512 LiveCounter_ACU_1 1000;
BA_REL_ "GenSigTimeoutTime" BU_SG_REL_ ADV SG_ 512 LiveCounter_ACU_1 1000;
BA_REL_ "GenSigTimeoutTime" BU_SG_REL_ Gateway SG_ 260 Checksum_APA_1 200;
BA_REL_ "GenSigTimeoutTime" BU_SG_REL_ HDMAP SG_ 260 Checksum_APA_1 200;
BA_REL_ "GenSigTimeoutTime" BU_SG_REL_ Gateway SG_ 260 APA_StopDistance 200;
BA_REL_ "GenSigTimeoutTime" BU_SG_REL_ Gateway SG_ 260 APA_SpeedLimitation 200;
BA_REL_ "GenSigTimeoutTime" BU_SG_REL_ Gateway SG_ 260 APA_FailureBrakeMode 200;
BA_REL_ "GenSigTimeoutTime" BU_SG_REL_ Gateway SG_ 260 TargetGearRequest_PSC 200;
BA_REL_ "GenSigTimeoutTime" BU_SG_REL_ Gateway SG_ 260 APA_PrefillRequest_Parking 200;
BA_REL_ "GenSigTimeoutTime" BU_SG_REL_ Gateway SG_ 260 APA_SecureRequest 200;
BA_REL_ "GenSigTimeoutTime" BU_SG_REL_ Gateway SG_ 260 APA_ComfortBrakeReq 200;
BA_REL_ "GenSigTimeoutTime" BU_SG_REL_ Gateway SG_ 260 APA_AutoParkingReq 200;
BA_REL_ "GenSigTimeoutTime" BU_SG_REL_ Gateway SG_ 260 APA_DirectionCmd 200;
BA_REL_ "GenSigTimeoutTime" BU_SG_REL_ Gateway SG_ 260 APA_AutoParkReq 200;
BA_REL_ "GenSigTimeoutTime" BU_SG_REL_ Gateway SG_ 260 APA_BrakeFunctionMode 200;
BA_REL_ "GenSigTimeoutTime" BU_SG_REL_ HDMAP SG_ 260 APA_BrakeFunctionMode 200;
BA_REL_ "GenSigTimeoutTime" BU_SG_REL_ Gateway SG_ 260 LiveCounter_APA_1 200;
BA_REL_ "GenSigTimeoutTime" BU_SG_REL_ HDMAP SG_ 260 LiveCounter_APA_1 200;
BA_REL_ "GenSigTimeoutTime" BU_SG_REL_ Gateway SG_ 256 Checksum_ADV_2 200;
BA_REL_ "GenSigTimeoutTime" BU_SG_REL_ Gateway SG_ 256 ADV_ErrorSt 200;
BA_REL_ "GenSigTimeoutTime" BU_SG_REL_ Gateway SG_ 256 ADV_AutoParkingModeReq 200;
BA_REL_ "GenSigTimeoutTime" BU_SG_REL_ Gateway SG_ 256 ADV_AutoParkingRequestSt 200;
BA_REL_ "GenSigTimeoutTime" BU_SG_REL_ Gateway SG_ 256 ADV_DisableECASAdjust 200;
BA_REL_ "GenSigTimeoutTime" BU_SG_REL_ Gateway SG_ 256 ADV_ECASNormalRequest 200;
BA_REL_ "GenSigTimeoutTime" BU_SG_REL_ Gateway SG_ 256 ADV_ErrorSt_APA 200;
BA_REL_ "GenSigTimeoutTime" BU_SG_REL_ Gateway SG_ 256 ADV_ErrorSt_RPA 200;
BA_REL_ "GenSigTimeoutTime" BU_SG_REL_ Gateway SG_ 256 ADV_ErrorSt_AVP 200;
BA_REL_ "GenSigTimeoutTime" BU_SG_REL_ Gateway SG_ 256 ADV_WorkingSt_APA 200;
BA_REL_ "GenSigTimeoutTime" BU_SG_REL_ Gateway SG_ 256 ADV_WorkingSt_RPA 200;
BA_REL_ "GenSigTimeoutTime" BU_SG_REL_ Gateway SG_ 256 ADV_WorkingSt_AVP 200;
BA_REL_ "GenSigTimeoutTime" BU_SG_REL_ Gateway SG_ 256 ADV_SteeringWheelAngleRequest 200;
BA_REL_ "GenSigTimeoutTime" BU_SG_REL_ Gateway SG_ 256 ADV_SteeringWheelAngleSignReques 200;
BA_REL_ "GenSigTimeoutTime" BU_SG_REL_ Gateway SG_ 256 ADV_SteeringWheelAngleControlReq 200;
BA_REL_ "GenSigTimeoutTime" BU_SG_REL_ Gateway SG_ 256 LiveCounter_ADV_2 200;
BA_REL_ "GenSigTimeoutTime" BU_SG_REL_ Gateway SG_ 280 Checksum_HAD_1 200;
BA_REL_ "GenSigTimeoutTime" BU_SG_REL_ CDS2 SG_ 280 Checksum_HAD_1 200;
BA_REL_ "GenSigTimeoutTime" BU_SG_REL_ AVP SG_ 280 Checksum_HAD_1 200;
BA_REL_ "GenSigTimeoutTime" BU_SG_REL_ HDMAP SG_ 280 Checksum_HAD_1 200;
BA_REL_ "GenSigTimeoutTime" BU_SG_REL_ Gateway SG_ 280 HAD_WorkingSt_AEB_L12 200;
BA_REL_ "GenSigTimeoutTime" BU_SG_REL_ CDS2 SG_ 280 HAD_WorkingSt_AEB_L12 200;
BA_REL_ "GenSigTimeoutTime" BU_SG_REL_ Gateway SG_ 280 HAD_ErrorSt_AEB_L12 200;
BA_REL_ "GenSigTimeoutTime" BU_SG_REL_ CDS2 SG_ 280 HAD_ErrorSt_AEB_L12 200;
BA_REL_ "GenSigTimeoutTime" BU_SG_REL_ Gateway SG_ 280 HAD_ErrorSt_ACC_L12 200;
BA_REL_ "GenSigTimeoutTime" BU_SG_REL_ CDS2 SG_ 280 HAD_ErrorSt_ACC_L12 200;
BA_REL_ "GenSigTimeoutTime" BU_SG_REL_ Gateway SG_ 280 HAD_WorkingSt_ACC_L12 200;
BA_REL_ "GenSigTimeoutTime" BU_SG_REL_ CDS2 SG_ 280 HAD_WorkingSt_ACC_L12 200;
BA_REL_ "GenSigTimeoutTime" BU_SG_REL_ AVP SG_ 280 HAD_WorkingSt_ACC_L12 200;
BA_REL_ "GenSigTimeoutTime" BU_SG_REL_ HDMAP SG_ 280 HAD_WorkingSt_ACC_L12 200;
BA_REL_ "GenSigTimeoutTime" BU_SG_REL_ Gateway SG_ 280 HAD_ABPReq_L12 200;
BA_REL_ "GenSigTimeoutTime" BU_SG_REL_ CDS2 SG_ 280 HAD_ABPReq_L12 200;
BA_REL_ "GenSigTimeoutTime" BU_SG_REL_ Gateway SG_ 280 HAD_AWBReq_L12 200;
BA_REL_ "GenSigTimeoutTime" BU_SG_REL_ CDS2 SG_ 280 HAD_AWBReq_L12 200;
BA_REL_ "GenSigTimeoutTime" BU_SG_REL_ Gateway SG_ 280 HAD_AWBlevel_L12 200;
BA_REL_ "GenSigTimeoutTime" BU_SG_REL_ CDS2 SG_ 280 HAD_AWBlevel_L12 200;
BA_REL_ "GenSigTimeoutTime" BU_SG_REL_ Gateway SG_ 280 HAD_CruiseModeFunctionInd 200;
BA_REL_ "GenSigTimeoutTime" BU_SG_REL_ CDS2 SG_ 280 HAD_CruiseModeFunctionInd 200;
BA_REL_ "GenSigTimeoutTime" BU_SG_REL_ AVP SG_ 280 HAD_CruiseModeFunctionInd 200;
BA_REL_ "GenSigTimeoutTime" BU_SG_REL_ Gateway SG_ 280 HAD_BrakeModeReq_L12 200;
BA_REL_ "GenSigTimeoutTime" BU_SG_REL_ CDS2 SG_ 280 HAD_BrakeModeReq_L12 200;
BA_REL_ "GenSigTimeoutTime" BU_SG_REL_ Gateway SG_ 280 HAD_DrivedownReq_L12 200;
BA_REL_ "GenSigTimeoutTime" BU_SG_REL_ CDS2 SG_ 280 HAD_DrivedownReq_L12 200;
BA_REL_ "GenSigTimeoutTime" BU_SG_REL_ Gateway SG_ 280 HAD_SecureRequest_L12 200;
BA_REL_ "GenSigTimeoutTime" BU_SG_REL_ CDS2 SG_ 280 HAD_SecureRequest_L12 200;
BA_REL_ "GenSigTimeoutTime" BU_SG_REL_ Gateway SG_ 280 HAD_AEBSensitivity_L12 200;
BA_REL_ "GenSigTimeoutTime" BU_SG_REL_ CDS2 SG_ 280 HAD_AEBSensitivity_L12 200;
BA_REL_ "GenSigTimeoutTime" BU_SG_REL_ Gateway SG_ 280 HAD_AutoDrivingReq 200;
BA_REL_ "GenSigTimeoutTime" BU_SG_REL_ CDS2 SG_ 280 HAD_AutoDrivingReq 200;
BA_REL_ "GenSigTimeoutTime" BU_SG_REL_ Gateway SG_ 280 LiveCounter_HAD_1 200;
BA_REL_ "GenSigTimeoutTime" BU_SG_REL_ CDS2 SG_ 280 LiveCounter_HAD_1 200;
BA_REL_ "GenSigTimeoutTime" BU_SG_REL_ AVP SG_ 280 LiveCounter_HAD_1 200;
BA_REL_ "GenSigTimeoutTime" BU_SG_REL_ HDMAP SG_ 280 LiveCounter_HAD_1 200;
BA_REL_ "GenSigTimeoutTime" BU_SG_REL_ Gateway SG_ 281 Checksum_HAD_2 200;
BA_REL_ "GenSigTimeoutTime" BU_SG_REL_ CDS2 SG_ 281 Checksum_HAD_2 200;
BA_REL_ "GenSigTimeoutTime" BU_SG_REL_ HDMAP SG_ 281 Checksum_HAD_2 200;
BA_REL_ "GenSigTimeoutTime" BU_SG_REL_ Gateway SG_ 281 HAD_AutoDrivingReq_L12 200;
BA_REL_ "GenSigTimeoutTime" BU_SG_REL_ CDS2 SG_ 281 HAD_AutoDrivingReq_L12 200;
BA_REL_ "GenSigTimeoutTime" BU_SG_REL_ HDMAP SG_ 281 HAD_AutoDrivingReq_L12 200;
BA_REL_ "GenSigTimeoutTime" BU_SG_REL_ Gateway SG_ 281 HAD_SpeedChangeRequest_L12 200;
BA_REL_ "GenSigTimeoutTime" BU_SG_REL_ CDS2 SG_ 281 HAD_SpeedChangeRequest_L12 200;
BA_REL_ "GenSigTimeoutTime" BU_SG_REL_ HDMAP SG_ 281 HAD_SpeedChangeRequest_L12 200;
BA_REL_ "GenSigTimeoutTime" BU_SG_REL_ Gateway SG_ 281 HAD_MaxAccGrad_L12 200;
BA_REL_ "GenSigTimeoutTime" BU_SG_REL_ CDS2 SG_ 281 HAD_MaxAccGrad_L12 200;
BA_REL_ "GenSigTimeoutTime" BU_SG_REL_ Gateway SG_ 281 HAD_MinAccGrad_L12 200;
BA_REL_ "GenSigTimeoutTime" BU_SG_REL_ CDS2 SG_ 281 HAD_MinAccGrad_L12 200;
BA_REL_ "GenSigTimeoutTime" BU_SG_REL_ Gateway SG_ 281 HAD_MaxComfBand_L12 200;
BA_REL_ "GenSigTimeoutTime" BU_SG_REL_ CDS2 SG_ 281 HAD_MaxComfBand_L12 200;
BA_REL_ "GenSigTimeoutTime" BU_SG_REL_ Gateway SG_ 281 HAD_MinComfBand_L12 200;
BA_REL_ "GenSigTimeoutTime" BU_SG_REL_ CDS2 SG_ 281 HAD_MinComfBand_L12 200;
BA_REL_ "GenSigTimeoutTime" BU_SG_REL_ Gateway SG_ 281 HAD_UseMaxComfBand_L12 200;
BA_REL_ "GenSigTimeoutTime" BU_SG_REL_ CDS2 SG_ 281 HAD_UseMaxComfBand_L12 200;
BA_REL_ "GenSigTimeoutTime" BU_SG_REL_ Gateway SG_ 281 LiveCounter_HAD_2 200;
BA_REL_ "GenSigTimeoutTime" BU_SG_REL_ CDS2 SG_ 281 LiveCounter_HAD_2 200;
BA_REL_ "GenSigTimeoutTime" BU_SG_REL_ HDMAP SG_ 281 LiveCounter_HAD_2 200;
VAL_ 265 SVB1_GearRequest 7 "Invalid Value" 6 "Reserved" 5 "Reserved" 4 "D" 3 "N" 2 "R" 1 "Reserved" 0 "No Request" ;
VAL_ 265 SVB1_AccelerationRequestSt 1 "Request" 0 "No Request" ;
VAL_ 265 SVB1_TakeOverRequest 1 "Request" 0 "No Request" ;
VAL_ 265 SVB1_AccelerationRequest 63 "SNA" ;
VAL_ 265 SVB1_SteeringSpeedRequest 511 "SNA" ;
VAL_ 265 SVB1_StandStillRequest 1 "Request" 0 "No Request" ;
VAL_ 265 SVB1_SteeringSpeedSignRequest 3 "Reserved" 2 "Right(Negative)" 1 "Left(Positive)" 0 "No Request" ;
VAL_ 265 SVB1_SteeringAngleSignRequest 3 "Reserved" 2 "Right(Negative)" 1 "Left(Positive)" 0 "No Request" ;
VAL_ 265 SVB1_SteeringAngleRequest 1023 "SNA" ;
VAL_ 265 SVB1_SteeringRequestSt 3 "Reserved" 2 "Reserved" 1 "Request" 0 "No Request" ;
VAL_ 265 SVB1_FailureStatus 3 "Reserved" 2 "Reserved" 1 "Error" 0 "No Error" ;
VAL_ 265 SVB1_DecelerationRequestSt 3 "Reserved" 2 "AEB request" 1 "ACC request" 0 "No Request" ;
VAL_ 265 SVB1_DecelerationRequest 1023 "SNA" ;
VAL_ 416 SVB1_LeftTurningLightRequest 3 "Reserved" 2 "On" 1 "Off" 0 "No Request" ;
VAL_ 416 SVB1_RightTurningLightRequest 3 "Reserved" 2 "On" 1 "Off" 0 "No Request" ;
VAL_ 416 SVB1_HazardLightRequest 3 "Reserved" 2 "On" 1 "Off" 0 "No Request" ;
VAL_ 416 SVB1_FogRequest 7 "reserved" 6 "RequestFrontFogAndRearFogBothOff" 5 "RequestFrontFogAndRearFogBothOn" 4 "Only request rear fog off" 3 "Only request rear fog on" 2 "Only request front fog off" 1 "Only request front fog on" 0 "No Request" ;
VAL_ 416 SVB1_HornRequest 1 "request" 0 "no request" ;
VAL_ 416 SVB1_Lowbeamrequest 3 "reserved" 2 "reserved" 1 "request" 0 "no request" ;
VAL_ 416 SVB1_HighBeamRequest 3 "reserved" 2 "reserved" 1 "request" 0 "no request" ;
VAL_ 416 SVB1_HU_SpeechReq_LeftTempAdjSW 7 "invalid value" 6 "reserved" 5 "minus two step" 4 "minus one step" 3 "reserved" 2 "add two step" 1 "Add one step" 0 "no request" ;
VAL_ 416 SVB1_PositionLightRequest 7 "reserved" 6 "RequestFrontPosAndRearPosBothOff" 5 "RequestFrontPosAndRearPosBothOn" 4 "Only request rear position off" 3 "Only request rear position on" 2 "Only request front position off" 1 "Only request front position on" 0 "No request" ;
VAL_ 416 SVB1_HU_SpeechRequest_AC 3 "reserved" 2 "off" 1 "on" 0 "no request" ;
VAL_ 416 SVB1_HU_SpeechRequest_FRSREC 3 "reserved" 2 "rec" 1 "frs" 0 "no request" ;
VAL_ 416 SVB1_HU_SpeechRequest_BlwlevelAd 3 "invalid value" 2 "down" 1 "up" 0 "no request" ;
VAL_ 416 SVB1_HU_SpeechReq_FLseatHeatLeve 7 "reserved" 6 "reserved" 5 "reserved" 4 "level 3" 3 "level 2" 2 "level 1" 1 "off" 0 "no request" ;
VAL_ 416 SVB1_HU_SpeechReq_FRseatHeatLeve 7 "reserved" 6 "reserved" 5 "reserved" 4 "level 3" 3 "level 2" 2 "level 1" 1 "off" 0 "no request" ;
VAL_ 416 SVB1_EPBRequest 3 "Invalid Value" 2 "Locking" 1 "Releasing" 0 "No Request" ;
VAL_ 416 SVB1_RequestTurnOffLowVoltage 3 "reserved" 2 "reserved" 1 "request" 0 "no request" ;
VAL_ 459 VehicleCoordinateY 4095 "SNA" ;
VAL_ 459 VehicleCoordinateX 8191 "SNA" ;
VAL_ 605 ParkingSlotDegree_Right 4095 "SNA" ;
VAL_ 605 ParkingSlotDegree_Left 4095 "SNA" ;
VAL_ 605 SensorErrorSt_RRS 1 "Error" 0 "No error" ;
VAL_ 605 ObjectRange_RRS 7 "Invalid Value" 6 "Range 6" 5 "Range 5" 4 "Range 4" 3 "Range 3" 2 "Range 2" 1 "Range 1" 0 "No Object" ;
VAL_ 605 SensorErrorSt_RLS 1 "Error" 0 "No error" ;
VAL_ 605 ObjectRange_RLS 7 "Invalid Value" 6 "Range 6" 5 "Range 5" 4 "Range 4" 3 "Range 3" 2 "Range 2" 1 "Range 1" 0 "No Object" ;
VAL_ 605 SensorErrorSt_FRS 1 "Error" 0 "No error" ;
VAL_ 605 ObjectRange_FRS 7 "Invalid Value" 6 "Range 6" 5 "Range 5" 4 "Range 4" 3 "Range 3" 2 "Range 2" 1 "Range 1" 0 "No Object" ;
VAL_ 605 SensorErrorSt_FLS 1 "Error" 0 "No error" ;
VAL_ 605 ObjectRange_FLS 7 "Invalid Value" 6 "Range 6" 5 "Range 5" 4 "Range 4" 3 "Range 3" 2 "Range 2" 1 "Range 1" 0 "No Object" ;
VAL_ 605 SensorBlockageSt_RRS 1 "Blockage" 0 "No blockage" ;
VAL_ 605 SensorBlockageSt_RLS 1 "Blockage" 0 "No blockage" ;
VAL_ 605 SensorBlockageSt_FRS 1 "Blockage" 0 "No blockage" ;
VAL_ 605 SensorBlockageSt_FLS 1 "Blockage" 0 "No blockage" ;
VAL_ 605 SensorBlockageSt_FL 1 "Blockage" 0 "No blockage" ;
VAL_ 605 SensorBlockageSt_FML 1 "Blockage" 0 "No blockage" ;
VAL_ 605 SensorBlockageSt_FMR 1 "Blockage" 0 "No blockage" ;
VAL_ 605 SensorBlockageSt_FR 1 "Blockage" 0 "No blockage" ;
VAL_ 605 SensorBlockageSt_RL 1 "Blockage" 0 "No blockage" ;
VAL_ 605 SensorBlockageSt_RML 1 "Blockage" 0 "No blockage" ;
VAL_ 605 SensorBlockageSt_RMR 1 "Blockage" 0 "No blockage" ;
VAL_ 605 SensorBlockageSt_RR 1 "Blockage" 0 "No blockage" ;
VAL_ 448 BCoordinateX_Left 4095 "SNA" ;
VAL_ 448 BCoordinateY_Left 1023 "SNA" ;
VAL_ 448 ACoordinateX_Left 4095 "SNA" ;
VAL_ 448 ACoordinateY_Left 1023 "SNA" ;
VAL_ 449 RearObjCoordinateX 4095 "SNA" ;
VAL_ 449 RearObjCoordinateY 4095 "SNA" ;
VAL_ 449 FrontObjCoordinateX 4095 "SNA" ;
VAL_ 449 FrontObjCoordinateY 4095 "SNA" ;
VAL_ 450 TxRxSt_FML 3 "Reserved" 2 "Rx" 1 "Tx" 0 "Reserved" ;
VAL_ 450 TxRxSt_FL 3 "Reserved" 2 "Rx" 1 "Tx" 0 "Reserved" ;
VAL_ 450 DistanceValue_FML 1023 "SNA" ;
VAL_ 450 DistanceValue_FL 1023 "SNA" ;
VAL_ 451 TxRxSt_FMR 3 "Reserved" 2 "Rx" 1 "Tx" 0 "Reserved" ;
VAL_ 451 TxRxSt_FR 3 "Reserved" 2 "Rx" 1 "Tx" 0 "Reserved" ;
VAL_ 451 DistanceValue_FMR 1023 "SNA" ;
VAL_ 451 DistanceValue_FR 1023 "SNA" ;
VAL_ 452 TxRxSt_RML 3 "Reserved" 2 "Rx" 1 "Tx" 0 "Reserved" ;
VAL_ 452 TxRxSt_RL 3 "Reserved" 2 "Rx" 1 "Tx" 0 "Reserved" ;
VAL_ 452 DistanceValue_RML 1023 "SNA" ;
VAL_ 452 DistanceValue_RL 1023 "SNA" ;
VAL_ 453 TxRxSt_RMR 3 "Reserved" 2 "Rx" 1 "Tx" 0 "Reserved" ;
VAL_ 453 TxRxSt_RR 3 "Reserved" 2 "Rx" 1 "Tx" 0 "Reserved" ;
VAL_ 453 DistanceValue_RMR 1023 "SNA" ;
VAL_ 453 DistanceValue_RR 1023 "SNA" ;
VAL_ 454 ParkingSlotDepth_Left 1023 "SNA" ;
VAL_ 454 DistanceValue_FRS 1023 "SNA" ;
VAL_ 454 DistanceValue_FLS 1023 "SNA" ;
VAL_ 192 WheelSpeed_FL 32767 "SNA" ;
VAL_ 192 WheelSpeed_FR 32767 "SNA" ;
VAL_ 192 AvailableSt_EPBSwitch 1 "Available" 0 "Not available" ;
VAL_ 192 VehiclSpeed 32767 "SNA" ;
VAL_ 192 VehiclSpeed_Q 1 "Faulty" 0 "Normal" ;
VAL_ 192 DrivingDirection 3 "Invalid Value" 2 "Backward" 1 "Forward" 0 "Stop" ;
VAL_ 192 EPBSwitch 3 "Reserved" 2 "Down" 1 "Up" 0 "No press" ;
VAL_ 194 WheelSpeed_RL 32767 "SNA" ;
VAL_ 194 WheelSpeed_RR 32767 "SNA" ;
VAL_ 194 MasterCylinderPressure 2047 "SNA" ;
VAL_ 304 WheelPulse_FL 255 "SNA" ;
VAL_ 304 WheelPulse_FR 255 "SNA" ;
VAL_ 304 WheelPulse_RL 255 "SNA" ;
VAL_ 304 WheelPulse_RR 255 "SNA" ;
VAL_ 304 WheelSpeedDirection_FL 3 "Invalid Value" 2 "Backward" 1 "Forward" 0 "Stop" ;
VAL_ 304 WheelSpeedDirection_FR 3 "Invalid Value" 2 "Backward" 1 "Forward" 0 "Stop" ;
VAL_ 304 WheelSpeedDirection_RL 3 "Invalid Value" 2 "Backward" 1 "Forward" 0 "Stop" ;
VAL_ 304 WheelSpeedDirection_RR 3 "Invalid Value" 2 "Backward" 1 "Forward" 0 "Stop" ;
VAL_ 306 WorkingSt_ESC 1 "On" 0 "Off" ;
VAL_ 306 ErrorSt_ESC 1 "Error" 0 "No Error" ;
VAL_ 306 Intervention_ESC 1 "Intervention" 0 "No Intervention" ;
VAL_ 306 ErrorSt_ABS 1 "Error" 0 "No Error" ;
VAL_ 306 Intervention_ABS 1 "Intervention" 0 "No Intervention" ;
VAL_ 306 Intervention_TCS 1 "Intervention" 0 "No Intervention" ;
VAL_ 306 ErrorSt_EBD 1 "Error" 0 "No error" ;
VAL_ 306 AvailableSt_CDP 1 "Available" 0 "Not Available" ;
VAL_ 306 Intervention_CDP_RWU 1 "Intervention" 0 "No intervention" ;
VAL_ 306 LampCmd_EPB 3 "Reserved" 2 "On" 1 "Flash" 0 "Off" ;
VAL_ 306 ErrotSt_EPB 3 "Reserved" 2 "Test mode" 1 "Error " 0 "No error" ;
VAL_ 306 AvailableSt_HDC 1 "Available" 0 "Not Available" ;
VAL_ 306 WorkingSt_HDC 3 "Error" 2 "Intervention" 1 "Standby" 0 "Off" ;
VAL_ 306 ErrorSt_AVH 1 "No error" 0 "Error" ;
VAL_ 306 WorkingSt_AVH 3 "Inactive" 2 "Intervention" 1 "Stand By" 0 "Off" ;
VAL_ 306 AvailableSt_CDDS 1 "Available" 0 "Not Available" ;
VAL_ 306 Intervention_CDDS 1 "Intervention" 0 "No Intervention" ;
VAL_ 306 AvailableSt_AEB 1 "Available" 0 "Not Available" ;
VAL_ 306 Intervention_AEB 1 "Intervention" 0 "No Intervention" ;
VAL_ 306 AvailableSt_ABP 1 "Available" 0 "Not Available" ;
VAL_ 306 Intervention_ABP 1 "Intervention" 0 "No Intervention" ;
VAL_ 306 AvailableSt_AWB 1 "Available" 0 "Not Available" ;
VAL_ 306 Intervention_AWB 1 "Intervention" 0 "No intervention" ;
VAL_ 306 AvailableSt_HBA 1 "Available" 0 "Not Available" ;
VAL_ 306 Intervention_HBA 1 "Intervention" 0 "No Intervention" ;
VAL_ 306 WorkingSt_HBB 3 "HBB Disabled" 2 "Reserved" 1 "HBB_FailedBoost" 0 "HBB Normal Mode" ;
VAL_ 306 Intervention_HBB 1 "Intervention" 0 "No intervention" ;
VAL_ 306 Intervention_EmergencyBrake 1 "Intervention" 0 "No intervention" ;
VAL_ 306 VehicleStandstillSt 1 "The vehicle is in standstill." 0 "The vehicle is not  in standstill." ;
VAL_ 306 BrakeLightCtrlCmd 1 "Illuminate" 0 "Not illuminate" ;
VAL_ 306 WorkingSt_EPB 3 "Unknown" 2 "Locked" 1 "Releasing/Locking" 0 "Released" ;
VAL_ 306 APA_Available_ESC 1 "Available" 0 "Not Available" ;
VAL_ 306 APA_Intervention_ESC 1 "Intervention" 0 "No intervention" ;
VAL_ 308 YawRate 4095 "SNA" ;
VAL_ 308 YRSSt 1 "Not Calibrated" 0 "Calibrated" ;
VAL_ 308 Acceleration_X 2047 "SNA" ;
VAL_ 308 YawRate_Raw 4095 "SNA" ;
VAL_ 308 Acceleration_Y 2047 "SNA" ;
VAL_ 308 ErrorSt_YRS 1 "Error" 0 "No Error" ;
VAL_ 312 ESC_AutoPark_LCSt 7 "Invalid" 6 "Reserved" 5 "Active_RPA" 4 "Active_APA" 3 "Reserved" 2 "Reserved" 1 "Standby" 0 "Off" ;
VAL_ 312 ESC_AutoPark_LCFailureSt 7 "Invalid" 6 "Reserved" 5 "Unexpected_GearIntervention" 4 "Reserved" 3 "Unexpected_EPB_Action" 2 "Unexpected_GearPosition" 1 "Vehicle_blocked" 0 "No Error" ;
VAL_ 312 ESC_AutoPark_LC_BrakeMode 3 "Reserved" 2 "Emergency" 1 "Comfortable" 0 "Inactive" ;
VAL_ 312 ESC_LSMAvail_Parking 1 "Not available" 0 "Available" ;
VAL_ 312 ESC_AutoPark_LC_APA_Avail 3 "Available" 2 "FailureDetectedReducedAvl" 1 "FailureDetectedFullyAvl" 0 "Not Available" ;
VAL_ 312 ESC_VLCSt_L12 1 "Active" 0 "Inactive" ;
VAL_ 312 ESC_VLCSt_L3 1 "Active" 0 "Inactive" ;
VAL_ 312 ESC_VLC_Error_L12 1 "Not available" 0 "Available" ;
VAL_ 312 ESC_VMC_Error_L3 3 "Availablewithfault" 2 "Available" 1 "Not Available" 0 "Not initialized" ;
VAL_ 312 ESC_AutoDriving_LC_Brakemode 3 "Reserved" 2 "Emergency" 1 "Comfortable" 0 "Inactive" ;
VAL_ 312 ESC_AutoPark_LC_RPA_Avail 3 "Available" 2 "FailureDetectedReducedAvl" 1 "FailureDetectedFullyAvl" 0 "Not available" ;
VAL_ 312 ESC_AutoParkingSt_Feedback 1 "Autoparking function active" 0 "Autoparking function inactive" ;
VAL_ 312 ESC_BrakePedalStatus 1 "brake pedal applied" 0 "brake pedal not applied" ;
VAL_ 312 ESC_BrakePedalStatus_Q 3 "Reserved" 2 "Full" 1 "Fault" 0 "NotInitialized" ;
VAL_ 312 ESC_BrakePedalDominant_Q 3 "Reserved" 2 "Full" 1 "Fault" 0 "NotInitialized" ;
VAL_ 312 ESC_BrakePedalDominant 1 "Dominant" 0 "No dominant" ;
VAL_ 312 ESC_AutoPark_LC_AVP_Avail 3 "Available" 2 "FailureDetectedReducedAvl" 1 "FailureDetectedFullyAvl" 0 "Available" ;
VAL_ 312 ESC_ShutOffFinished 1 "Active" 0 "Inactive" ;
VAL_ 319 ESC_SuspendStatus_VMC 3 "Park Brake Suspend" 2 "Other Suspend" 1 "Driver Suspend" 0 "No Suspend" ;
VAL_ 319 ESC_BrakeFunctionOverrideStatus 1 "Active" 0 "Inactive" ;
VAL_ 160 ESC_BrakeFxAvailability 3 "Reserved" 2 "Full" 1 "Fault" 0 "NotInitialized" ;
VAL_ 161 ESC_DrvReqTarFxBrakeAvail 3 "Reserved" 2 "Full" 1 " Fault" 0 " NotInitialized" ;
VAL_ 317 eB_TargetGearReq_VMC 7 "Invalid" 6 "Reserved" 5 "Reserved" 4 "Target gear D" 3 "Target gear N" 2 "Target gear R" 1 "Target gear P" 0 "No Request" ;
VAL_ 317 eB_VLCSt_L3 1 "Active" 0 "Inactive" ;
VAL_ 317 eB_VMC_Error_L3 3 "Availablewithfault" 2 "Available" 1 "Not Available" 0 "Not initialized" ;
VAL_ 317 eB_VMC_Error_Parking 7 "Useable" 6 "Reserved" 5 "Reserved" 4 "Reserved" 3 "Reserved" 2 "Error" 1 "Error but useable" 0 "Not useable" ;
VAL_ 317 eB_SuspendStatus_VMC 3 "Reserved" 2 "Other suspend" 1 "HCU Suspend" 0 "Normal" ;
VAL_ 317 eB_ShutOffFinished_L3 1 "Active" 0 "Inactive" ;
VAL_ 336 EPS_1_HandSteeringTorque 1023 "SNA" ;
VAL_ 336 EPS_1_HandSteeringTorqueSign 1 "Right (Negative)" 0 "Left (Positive)" ;
VAL_ 336 EPS_1_ErrorStatus 3 "Reserved" 2 "Critical Error(lose)" 1 "General Error(Derate)" 0 "No Error" ;
VAL_ 336 EPS_1_HandOffStatus 1 "Hands On" 0 "Hands Off" ;
VAL_ 336 EPS_1_HandOffValid 1 "Invalid" 0 "Valid" ;
VAL_ 336 EPS_1_LKAStatus 7 "Reserved" 6 "Reserved" 5 "Transit" 4 "Not configured" 3 "Permanently fail" 2 "Active" 1 "Available for control" 0 "Temporary inhibit" ;
VAL_ 336 EPS_1_OverlayInputTorque 1023 "SNA" ;
VAL_ 336 EPS_1_OverlayInputTorqueSign 1 "Right (Negative)" 0 "Left (Positive)" ;
VAL_ 336 EPS_1_AbortFeedback_HAD 31 "Reserved" 30 "Reserved" 29 "Reserved" 28 "Reserved" 27 "Reserved" 26 "Reserved" 25 "Reserved" 24 "Reserved" 23 "Reserved" 22 "Reserved" 21 "Reserved" 20 "Reserved" 19 "Reserved" 18 "Reserved" 17 "Reserved" 16 "Reserved" 15 "Reserved" 14 "Reserved" 13 "Reserved" 12 "Reserved" 11 "Reserved" 10 "Reserved" 9 "Reserved" 8 "Reserved" 7 "Reserved" 6 "Reserved" 5 "Reserved" 4 "Reserved" 3 "Reserved" 2 "Irrecoverable interruption" 1 "Recoverable interruption" 0 "No driving interuption" ;
VAL_ 337 EPS_1_SACCStatus 7 "Reserved" 6 "Reserved" 5 "Transit" 4 "Not configured" 3 "Permanently fail" 2 "Active" 1 "Available for control" 0 "Temporary inhibit" ;
VAL_ 337 EPS_1_HWPStatus 7 "Reserved" 6 "Reserved" 5 "Transit" 4 "Not configured" 3 "Permanently fail" 2 "Active" 1 "Available for control" 0 "Temporary inhibit" ;
VAL_ 337 EPS_1_TJPStatus 7 "Reserved" 6 "Reserved" 5 "Transit" 4 "Not configured" 3 "Permanently fail" 2 "Active" 1 "Available for control" 0 "Temporary inhibit" ;
VAL_ 337 EPS_1_APAStatus 7 "Reserved" 6 "Reserved" 5 "Transit" 4 "Not configured" 3 "Permanently fail" 2 "Active" 1 "Available for control" 0 "Temporary inhibit" ;
VAL_ 337 EPS_1_RPAStatus 7 "Reserved" 6 "Reserved" 5 "Transit" 4 "Not configured" 3 "Permanently fail" 2 "Active" 1 "Available for control" 0 "Temporary inhibit" ;
VAL_ 337 EPS_1_AVPStatus 7 "Reserved" 6 "Reserved" 5 "Transit" 4 "Not configured" 3 "Permanently fail" 2 "Active" 1 "Available for control" 0 "Temporary inhibit" ;
VAL_ 337 EPS_1_DegradeLevel_HAD 15 "Critical Error(lose)" 14 "Reserved" 13 "Reserved" 12 "Reserved" 11 "Reserved" 10 "Reserved" 9 "Reserved" 8 "DM8" 7 "DM7" 6 "DM6" 5 "DM5" 4 "DM4" 3 "DM3" 2 "DM2" 1 "DM1" 0 "No Error" ;
VAL_ 337 EPS_1_DriftWarning 3 "Drft Warning" 2 "Corrected" 1 "Calculating" 0 "Normal" ;
VAL_ 337 EPS_1_AutoDrivingMode 15 "Reserved" 14 "Reserved" 13 "Reserved" 12 "Reserved" 11 "Reserved" 10 "Reserved" 9 "Reserved" 8 "Reserved" 7 "AVP" 6 "RPA" 5 "APA" 4 "TJP" 3 "HWP" 2 "SACC" 1 "LKA" 0 "Idle" ;
VAL_ 208 SteeringWheelAngle 32767 "SNA" ;
VAL_ 208 SteeringWheelAngleSign 1 "Right " 0 "Left" ;
VAL_ 208 SteeringWheelSpeed 32767 "SNA" ;
VAL_ 208 SteeringWheelSpeedSign 1 "Right" 0 "Left " ;
VAL_ 208 SAS_St 3 "Permanent Error Detected" 2 "Intermittent Error Detected" 1 "SAS Not Calibrated" 0 "SAS Angle And Speed Correct" ;
VAL_ 534 DMS_VehicleModeInfo 15 "Invalid value" 14 "Reserved" 13 "Reserved" 12 "Reserved" 11 "Reserved" 10 "Extreme" 9 "Mud Ruts" 8 "Sand" 7 "EV" 6 "Individual" 5 "Off road" 4 "Snow" 3 "Sport" 2 "Comfort" 1 "Eco" 0 "Auto" ;
VAL_ 534 DMS_ErrorStatus 1 "Error" 0 "No error" ;
VAL_ 534 DMS_TargetVehicleMode 15 "Invalid value" 14 "Reserved" 13 "Reserved" 12 "Reserved" 11 "Reserved" 10 "Extreme" 9 "Mud Ruts" 8 "Sand" 7 "EV" 6 "Individual" 5 "Off road" 4 "Snow" 3 "Sport" 2 "Comfort" 1 "Eco" 0 "Auto" ;
VAL_ 290 HCU_LeverInfo 7 "Invalid Value" 6 "Reserved" 5 "No connection" 4 "Reserved" 3 "D" 2 "N" 1 "R" 0 "P" ;
VAL_ 290 HCU_AutoParkingResponse_L12 1 "Response" 0 "No response" ;
VAL_ 290 HCU_AutoParkingResponse_L3 1 "Response" 0 "No response" ;
VAL_ 290 HCU_CapabilitySt_AutoParking 3 "Reserved" 2 "Fault" 1 "Reduced" 0 "Normal" ;
VAL_ 264 HCU_AutoDrivingResponseSt_L12 1 "Response" 0 "No response" ;
VAL_ 264 HCU_AutoDrivingResponseSt_L3 1 "Response" 0 "No response" ;
VAL_ 264 HCU_CapabilitySt_AutoDriving 3 "Reserved" 2 "Fault" 1 "Reduced" 0 "Normal" ;
VAL_ 147 HCU_EVReady 3 "Reserved" 2 "Enable running(always on)" 1 "Preparing" 0 "Not useable(always off)" ;
VAL_ 146 HCU_AccelerationPedalPosition 255 "SNA" ;
VAL_ 146 HCU_CalcAccelerationPedalPositio 255 "SNA" ;
VAL_ 146 HCU_AccelerationPedalOverride 1 "Active" 0 "Inactive" ;
VAL_ 146 HCU_KickdownReq 1 "Active" 0 "Inactive" ;
VAL_ 151 HCU_MCU1TMSpeed 65535 "SNA" ;
VAL_ 151 HCU_MCU1ActTMTorque 16383 "SNA" ;
VAL_ 151 HCU_MCU1TMMAMTorque 8191 "SNA" ;
VAL_ 151 HCU_MCU1TMMAGTorque 8191 "SNA" ;
VAL_ 152 HCU_MCU2TMSpeed 65535 "SNA" ;
VAL_ 152 HCU_MCU2ActTMTorque 16383 "SNA" ;
VAL_ 152 HCU_MCU2TMMAMTorque 8191 "SNA" ;
VAL_ 152 HCU_MCU2TMMAGTorque 8191 "SNA" ;
VAL_ 288 EGSM_SecurityButton 1 "Pressed" 0 "Not Pressed" ;
VAL_ 288 EGSM_SecurityButtonErrorSt 1 "Error" 0 "No Error" ;
VAL_ 288 EGSM_ErrorStatus 1 "Error" 0 "No error" ;
VAL_ 512 SeatbeltWarningCmd_Passenger 3 "Red Flash(2HZ)" 2 "On" 1 "Red Flash(1HZ)" 0 "Off" ;
VAL_ 512 SeatbeltWarningCmd_Driver 3 "Red Flash(2HZ)" 2 "On" 1 "Red Flash(1HZ)" 0 "Off" ;
VAL_ 512 CrashInfo 1 "Crash" 0 "No Crash" ;
VAL_ 512 SysSt_ACU 3 "Reserved" 2 "Factory mode" 1 "Error" 0 "No error" ;
VAL_ 512 SeatBeltSt_Driver 3 "Reserved" 2 "Reserved" 1 "Buckled" 0 "Unbuckled" ;
VAL_ 260 APA_FailureBrakeMode 3 "Reserved" 2 "Emergency" 1 "Comfortable" 0 "Idle (No Braking)" ;
VAL_ 260 TargetGearRequest_PSC 7 "Invalid" 6 "Reserved" 5 "Reserved" 4 "Target gear D" 3 "Target gear N" 2 "Target gear R" 1 "Target gear P" 0 "No Request" ;
VAL_ 260 APA_PrefillRequest_Parking 1 "Request" 0 "No Request" ;
VAL_ 260 APA_SecureRequest 1 "Request" 0 "No Request" ;
VAL_ 260 APA_ComfortBrakeReq 3 "Invalid" 2 "Comfort brake type 2" 1 "Comfort barke type 1" 0 "No Request" ;
VAL_ 260 APA_AutoParkingReq 1 "Request" 0 "No Request" ;
VAL_ 260 APA_DirectionCmd 3 "Reserved" 2 "Backward" 1 "Forward" 0 "No Request" ;
VAL_ 260 APA_AutoParkReq 3 "Reserved" 2 "RPA(L23)" 1 "APA(L12)" 0 "No ActIve" ;
VAL_ 260 APA_BrakeFunctionMode 15 "Reserved" 14 "Reserved" 13 "Reserved" 12 "Reserved" 11 "Reserved" 10 "Reserved" 9 "Reserved" 8 "Reserved" 7 "Reserved" 6 "Reserved" 5 "Reserved" 4 "Reserved" 3 "Reserved" 2 "RPA(L23)" 1 "APA(L12)" 0 "No ActIve" ;
VAL_ 256 ADV_ErrorSt 1 "Error" 0 "No Error" ;
VAL_ 256 ADV_AutoParkingModeReq 7 "Reserved" 6 "Reserved" 5 "Reserved" 4 "Reserved" 3 "AVP" 2 "RPA" 1 "APA" 0 "No request" ;
VAL_ 256 ADV_AutoParkingRequestSt 3 "Reserved" 2 "Auto Parking Active" 1 "Auto Parking Request" 0 "No Request" ;
VAL_ 256 ADV_DisableECASAdjust 1 "Active" 0 "Inactive" ;
VAL_ 256 ADV_ECASNormalRequest 1 "Request" 0 "No Request" ;
VAL_ 256 ADV_ErrorSt_APA 3 "Reserved" 2 "Error" 1 "Derate" 0 "Normal" ;
VAL_ 256 ADV_ErrorSt_RPA 3 "Reserved" 2 "Error" 1 "Derate" 0 "Normal" ;
VAL_ 256 ADV_ErrorSt_AVP 3 "Reserved" 2 "Error" 1 "Derate" 0 "Normal" ;
VAL_ 256 ADV_WorkingSt_APA 7 "Reserved" 6 "Reserved" 5 "Reserved" 4 "Exit" 3 "Active" 2 "Available" 1 "Standby" 0 "Off" ;
VAL_ 256 ADV_WorkingSt_RPA 7 "Reserved" 6 "Reserved" 5 "Reserved" 4 "Exit" 3 "Active" 2 "Available" 1 "Standby" 0 "Off" ;
VAL_ 256 ADV_WorkingSt_AVP 7 "Reserved" 6 "Reserved" 5 "Reserved" 4 "Exit" 3 "Active" 2 "Available" 1 "Standby" 0 "Off" ;
VAL_ 256 ADV_SteeringWheelAngleRequest 32767 "SNA" ;
VAL_ 256 ADV_SteeringWheelAngleSignReques 3 "Reserved" 2 "Right (Negative)" 1 "Left (Positive)" 0 "No Request" ;
VAL_ 256 ADV_SteeringWheelAngleControlReq 3 "Reserved" 2 "Reserved" 1 "EPS control request" 0 "No Request" ;
VAL_ 280 HAD_WorkingSt_AEB_L12 3 "Reserved" 2 "Active" 1 "Standby" 0 "Off" ;
VAL_ 280 HAD_ErrorSt_AEB_L12 1 "Error" 0 "No Error" ;
VAL_ 280 HAD_ErrorSt_ACC_L12 1 "Error" 0 "No Error" ;
VAL_ 280 HAD_WorkingSt_ACC_L12 7 "Reserved" 6 "Reserved" 5 "Reserved" 4 "Shutoff" 3 "Override" 2 "Active" 1 "Stand By" 0 "Off" ;
VAL_ 280 HAD_ABPReq_L12 1 "Request" 0 "Inactive" ;
VAL_ 280 HAD_AWBReq_L12 1 "Request" 0 "Inactive" ;
VAL_ 280 HAD_AWBlevel_L12 7 "Reserved" 6 "Reserved" 5 "Reserved" 4 "Level4" 3 "Level3" 2 "Level2" 1 "Level1" 0 "Inactive" ;
VAL_ 280 HAD_CruiseModeFunctionInd 3 "Reseved" 2 "SACC" 1 "ACC" 0 "Off" ;
VAL_ 280 HAD_BrakeModeReq_L12 3 "Reserved" 2 "Emergency" 1 "Comfortable" 0 "LongControlOff" ;
VAL_ 280 HAD_DrivedownReq_L12 1 "Request" 0 "No Request" ;
VAL_ 280 HAD_SecureRequest_L12 1 "Request" 0 "No Request" ;
VAL_ 280 HAD_AEBSensitivity_L12 3 "High" 2 "Normal" 1 "Low" 0 "Inactive" ;
VAL_ 280 HAD_AutoDrivingReq 3 "Reserved" 2 "L3" 1 "L12" 0 "Inactive" ;
VAL_ 281 HAD_AutoDrivingReq_L12 3 "Reserved" 2 "L3Request" 1 "L1L2Request" 0 "No Request" ;
VAL_ 281 HAD_SpeedChangeRequest_L12 2047 "SNA" ;
VAL_ 281 HAD_MaxAccGrad_L12 255 "SNA" ;
VAL_ 281 HAD_MinAccGrad_L12 255 "SNA" ;
VAL_ 281 HAD_MaxComfBand_L12 255 "SNA" ;
VAL_ 281 HAD_MinComfBand_L12 255 "SNA" ;
VAL_ 281 HAD_UseMaxComfBand_L12 1 "Active" 0 "Inactive" ;
